VERSION ""

NS_ :

BS_:

BU_: ABS_BASE ATCM_DMSM GENERIC_GWMWakeup PBM IPMB TCU_TBS FDSM GSM TRCM GWM _delete ABS_ESC HUD IPMA CCM SASM PSCM SCCM HCM ATCM SUMA_RLM ATCM_FFSM PCU SECM VDM TBM OCS GENERIC TCCM TSTR RCM

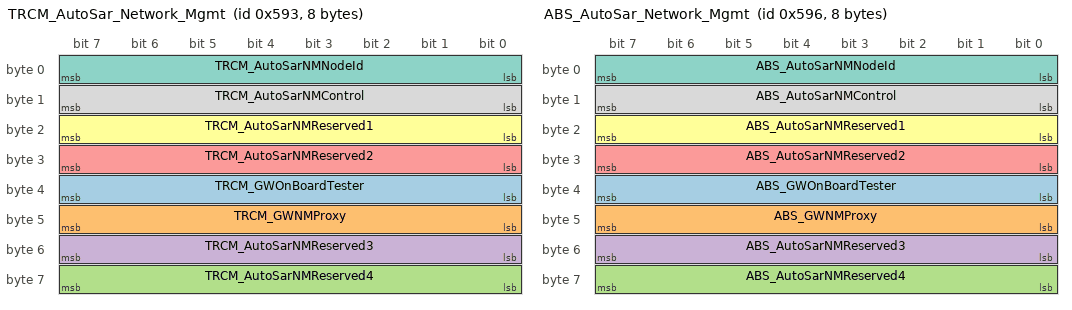
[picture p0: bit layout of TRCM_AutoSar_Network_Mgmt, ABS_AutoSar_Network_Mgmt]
BO_ 1427 TRCM_AutoSar_Network_Mgmt: 8 TRCM
 SG_ TRCM_GWOnBoardTester : 39|8@0+ (1,0) [0|255] "unitless"  GWM
 SG_ TRCM_GWNMProxy : 47|8@0+ (1,0) [0|255] "unitless"  GWM
 SG_ TRCM_AutoSarNMReserved4 : 63|8@0+ (1,0) [0|255] "unitless"  GWM
 SG_ TRCM_AutoSarNMReserved3 : 55|8@0+ (1,0) [0|255] "unitless"  GWM
 SG_ TRCM_AutoSarNMReserved2 : 31|8@0+ (1,0) [0|255] "unitless"  GWM
 SG_ TRCM_AutoSarNMReserved1 : 23|8@0+ (1,0) [0|255] "unitless"  GWM
 SG_ TRCM_AutoSarNMNodeId : 7|8@0+ (1,0) [0|255] "unitless"  GWM
 SG_ TRCM_AutoSarNMControl : 15|8@0+ (1,0) [0|255] "unitless"  GWM

BO_ 1430 ABS_AutoSar_Network_Mgmt: 8 ABS_ESC
 SG_ ABS_GWOnBoardTester : 39|8@0+ (1,0) [0|255] "unitless"  SCCM,GSM,PSCM,GWM
 SG_ ABS_GWNMProxy : 47|8@0+ (1,0) [0|255] "unitless"  SCCM,GSM,PSCM,GWM
 SG_ ABS_AutoSarNMReserved4 : 63|8@0+ (1,0) [0|255] "unitless"  SCCM,GSM,PSCM,GWM
 SG_ ABS_AutoSarNMReserved3 : 55|8@0+ (1,0) [0|255] "unitless"  SCCM,GSM,PSCM,GWM
 SG_ ABS_AutoSarNMReserved2 : 31|8@0+ (1,0) [0|255] "unitless"  SCCM,GSM,PSCM,GWM
 SG_ ABS_AutoSarNMReserved1 : 23|8@0+ (1,0) [0|255] "unitless"  SCCM,GSM,PSCM,GWM
 SG_ ABS_AutoSarNMNodeId : 7|8@0+ (1,0) [0|255] "unitless"  SCCM,GSM,PSCM,GWM
 SG_ ABS_AutoSarNMControl : 15|8@0+ (1,0) [0|255] "unitless"  SCCM,GSM,PSCM,GWM

BO_ 1082 GatewayData_HS2: 8 GWM
 SG_ EsaOn_B_Rq_UB : 33|1@0+ (1,0) [0|1] "SED"  PSCM
 SG_ EsaOn_B_Rq : 34|1@0+ (1,0) [0|1] "SED"  PSCM
 SG_ RearDiffLck_D_RqArb_UB : 35|1@0+ (1,0) [0|1] "SED"  TCCM
 SG_ RearDiffLck_D_RqArb : 25|2@0+ (1,0) [0|3] "SED"  TCCM
 SG_ AwdMde_D_RqArb_UB : 36|1@0+ (1,0) [0|1] "SED"  TCCM
 SG_ AwdMde_D_RqArb : 39|3@0+ (1,0) [0|7] "SED"  TCCM
 SG_ SelDrvMdeTxtReset_B_Rq_UB : 43|1@0+ (1,0) [0|1] "SED"  ABS_ESC,ABS_BASE
 SG_ SelDrvMdeTxtReset_B_Rq : 44|1@0+ (1,0) [0|1] "SED"  ABS_ESC,ABS_BASE
 SG_ SelDrvMdeDsply_B_Avail_UB : 50|1@0+ (1,0) [0|1] "SED"  ABS_BASE,ABS_ESC
 SG_ AirSusp_D_RqDrv_UB : 16|1@0+ (1,0) [0|1] "SED"  VDM
 SG_ DrvInputRequired_B_Rq_UB : 52|1@0+ (1,0) [0|1] "SED"  SCCM
 SG_ DrvInputRequired_B_Rq : 32|1@0+ (1,0) [0|1] "SED"  SCCM
 SG_ SelDrvMdeSwtch_D_Stat2_UB : 45|1@0+ (1,0) [0|1] "SED"  ABS_BASE,ABS_ESC
 SG_ SelDrvMdeSwtch_D_Stat2 : 47|2@0+ (1,0) [0|3] "SED"  ABS_BASE,ABS_ESC
 SG_ SelDrvMdeSwtch_D_Stat3_UB : 42|1@0+ (1,0) [0|1] "SED"  ABS_BASE,ABS_ESC
 SG_ FapLcStopHold_B_Rq : 57|1@0+ (1,0) [0|1] "SED"  ABS_BASE,ABS_ESC
 SG_ SelDrvMdeDsply_B_Avail : 51|1@0+ (1,0) [0|1] "SED"  ABS_BASE,ABS_ESC
 SG_ FapLcPrchgBrk_B_Rq : 59|1@0+ (1,0) [0|1] "SED"  ABS_BASE,ABS_ESC
 SG_ FapLcStopHold_B_Rq_UB : 56|1@0+ (1,0) [0|1] "SED"  ABS_BASE,ABS_ESC
 SG_ FapLcPrchgBrk_B_Rq_UB : 58|1@0+ (1,0) [0|1] "SED"  ABS_BASE,ABS_ESC
 SG_ LnchCtl_N_Rq_UB : 23|1@0+ (1,0) [0|1] "SED"  ABS_BASE,ABS_ESC
 SG_ LnchCtl_D_Rq_UB : 0|1@0+ (1,0) [0|1] "SED"  ABS_BASE,ABS_ESC
 SG_ LnchCtl_N_Rq : 15|8@0+ (50,0) [0|12750] "rpm"  ABS_BASE,ABS_ESC
 SG_ LnchCtl_D_Rq : 2|2@0+ (1,0) [0|3] "SED"  ABS_BASE,ABS_ESC
 SG_ AirSusp_D_RqDrv : 31|2@0+ (1,0) [0|3] "SED"  VDM
 SG_ AwdRnge_D_ActlIpc_UB : 26|1@0+ (1,0) [0|1] "SED"  ABS_BASE,ABS_ESC,TCCM
 SG_ AwdRnge_D_ActlIpc : 29|3@0+ (1,0) [0|7] "SED"  ABS_BASE,ABS_ESC,TCCM
 SG_ NtrlTowMdeEnbl_B_RqDrv_UB : 60|1@0+ (1,0) [0|1] "SED"  TCCM
 SG_ NtrlTowMdeEnbl_B_RqDrv : 48|1@0+ (1,0) [0|1] "SED"  TCCM
 SG_ DrvSlipCtlMde_B_RqMyKey_UB : 17|1@0+ (1,0) [0|1] "SED"  ABS_BASE,ABS_ESC
 SG_ DrvSlipCtlMde_B_RqMyKey : 18|1@0+ (1,0) [0|1] "SED"  ABS_BASE,ABS_ESC
 SG_ AwdDrvMde_D_Rq_UB : 49|1@0+ (1,0) [0|1] "SED"  TCCM
 SG_ AwdDrvMde_D_Rq : 63|3@0+ (1,0) [0|7] "SED"  TCCM
 SG_ MetricActv_B_Actl_UB : 53|1@0+ (1,0) [0|1] "SED"  IPMA
 SG_ MetricActv_B_Actl : 54|1@0+ (1,0) [0|1] "SED"  IPMA
 SG_ CamraFrntBttn_D_Stat2_UB : 3|1@0+ (1,0) [0|1] "SED"  IPMB
 SG_ CamraFrntBttn_D_Stat2 : 4|1@0+ (1,0) [0|1] "SED"  IPMB
 SG_ BrkLineLck_D_Rq_UB : 5|1@0+ (1,0) [0|1] "SED"  ABS_BASE,ABS_ESC
 SG_ BrkLineLck_D_Rq : 7|2@0+ (1,0) [0|3] "SED"  ABS_BASE,ABS_ESC
 SG_ SuspDrvMde_D_Rq_UB : 19|1@0+ (1,0) [0|1] "SED"  VDM
 SG_ SuspDrvMde_D_Rq : 22|3@0+ (1,0) [0|7] "SED"  VDM
 SG_ SelDrvMdePt_D_Stat_UB : 55|1@0+ (1,0) [0|1] "SED"  ABS_BASE,ABS_ESC
 SG_ SelDrvMdePt_D_Stat : 41|2@0+ (1,0) [0|3] "SED"  ABS_BASE,ABS_ESC

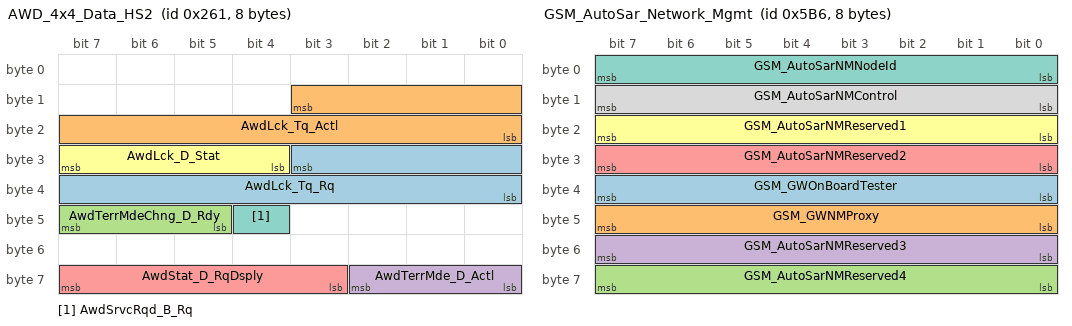
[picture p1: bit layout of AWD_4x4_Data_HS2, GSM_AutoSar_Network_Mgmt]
BO_ 609 AWD_4x4_Data_HS2: 8 GWM
 SG_ AwdLck_Tq_Rq : 27|12@0+ (1,0) [0|4093] "Nm"  GENERIC
 SG_ AwdLck_Tq_Actl : 11|12@0+ (1,0) [0|4093] "Nm"  ABS_BASE,ABS_ESC
 SG_ AwdTerrMdeChng_D_Rdy : 47|3@0+ (1,0) [0|7] "SED"  ATCM
 SG_ AwdTerrMde_D_Actl : 58|3@0+ (1,0) [0|7] "SED"  ATCM
 SG_ AwdStat_D_RqDsply : 63|5@0+ (1,0) [0|31] "SED"  ABS_BASE,ABS_ESC
 SG_ AwdLck_D_Stat : 31|4@0+ (1,0) [0|15] "SED"  ABS_BASE,ABS_ESC
 SG_ AwdSrvcRqd_B_Rq : 44|1@0+ (1,0) [0|1] "SED"  ABS_BASE,ABS_ESC,RCM

BO_ 1462 GSM_AutoSar_Network_Mgmt: 8 GSM
 SG_ GSM_GWOnBoardTester : 39|8@0+ (1,0) [0|255] "unitless"  GWM
 SG_ GSM_GWNMProxy : 47|8@0+ (1,0) [0|255] "unitless"  GWM
 SG_ GSM_AutoSarNMReserved4 : 63|8@0+ (1,0) [0|255] "unitless"  GWM
 SG_ GSM_AutoSarNMReserved3 : 55|8@0+ (1,0) [0|255] "unitless"  GWM
 SG_ GSM_AutoSarNMReserved2 : 31|8@0+ (1,0) [0|255] "unitless"  GWM
 SG_ GSM_AutoSarNMReserved1 : 23|8@0+ (1,0) [0|255] "unitless"  GWM
 SG_ GSM_AutoSarNMNodeId : 7|8@0+ (1,0) [0|255] "unitless"  GWM
 SG_ GSM_AutoSarNMControl : 15|8@0+ (1,0) [0|255] "unitless"  GWM

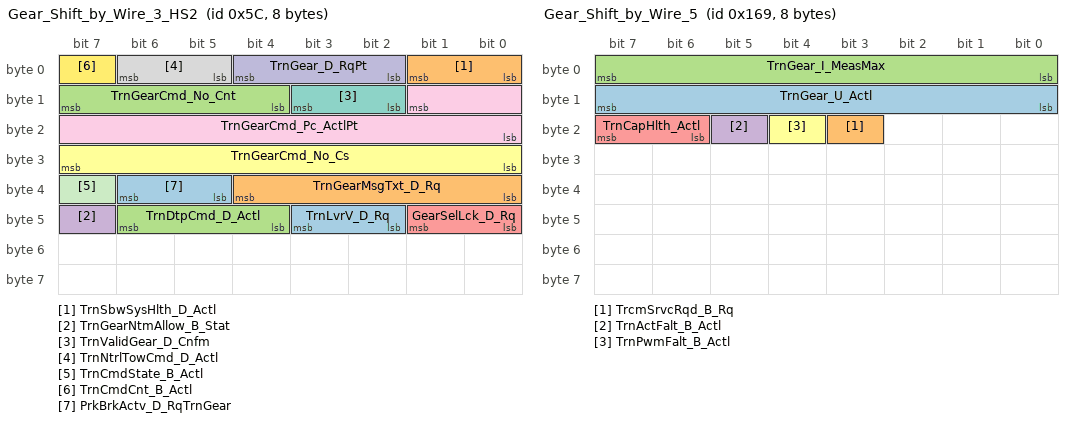
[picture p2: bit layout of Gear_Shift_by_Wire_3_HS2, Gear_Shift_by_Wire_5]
BO_ 92 Gear_Shift_by_Wire_3_HS2: 8 GWM
 SG_ TrnLvrV_D_Rq : 43|2@0+ (1,0) [0|3] "SED"  TRCM
 SG_ TrnSbwSysHlth_D_Actl : 1|2@0+ (1,0) [0|3] "SED"  GSM,TRCM
 SG_ TrnDtpCmd_D_Actl : 46|3@0+ (1,0) [0|7] "SED"  GSM,TRCM
 SG_ TrnGearNtmAllow_B_Stat : 47|1@0+ (1,0) [0|1] "SED"  GENERIC
 SG_ GearSelLck_D_Rq : 41|2@0+ (1,0) [0|3] "SED"  GSM,TRCM
 SG_ TrnGearCmd_No_Cs : 31|8@0+ (1,0) [0|255] "Unitless"  TRCM,GSM
 SG_ TrnValidGear_D_Cnfm : 11|2@0+ (1,0) [0|3] "SED"  TRCM,GSM
 SG_ TrnNtrlTowCmd_D_Actl : 6|2@0+ (1,0) [0|3] "SED"  ABS_BASE,ABS_ESC,TRCM,GSM
 SG_ TrnGearCmd_Pc_ActlPt : 9|10@0+ (0.1,0) [0|102.2] "percent duty cycle"  TRCM,GSM
 SG_ TrnGear_D_RqPt : 4|3@0+ (1,0) [0|7] "SED"  TRCM,GSM
 SG_ TrnCmdState_B_Actl : 39|1@0+ (1,0) [0|1] "SED"  TRCM,GSM
 SG_ TrnCmdCnt_B_Actl : 7|1@0+ (1,0) [0|1] "unitless"  TRCM,GSM
 SG_ PrkBrkActv_D_RqTrnGear : 38|2@0+ (1,0) [0|3] "SED"  ABS_BASE,GSM,TRCM,ABS_ESC
 SG_ TrnGearMsgTxt_D_Rq : 36|5@0+ (1,0) [0|31] "SED"  GENERIC
 SG_ TrnGearCmd_No_Cnt : 15|4@0+ (1,0) [0|15] "Unitless"  GSM,TRCM

BO_ 361 Gear_Shift_by_Wire_5: 8 TRCM
 SG_ TrnGear_U_Actl : 15|8@0+ (0.1,0) [0|25.5] "volt"  GWM
 SG_ TrcmSrvcRqd_B_Rq : 19|1@0+ (1,0) [0|1] "SED"  GWM
 SG_ TrnGear_I_MeasMax : 7|8@0+ (0.1,0) [0|25.4] "Amps"  GWM
 SG_ TrnActFalt_B_Actl : 21|1@0+ (1,0) [0|1] "SED"  GWM
 SG_ TrnCapHlth_Actl : 23|2@0+ (1,0) [0|3] "SED"  GWM
 SG_ TrnPwmFalt_B_Actl : 20|1@0+ (1,0) [0|1] "SED"  GWM

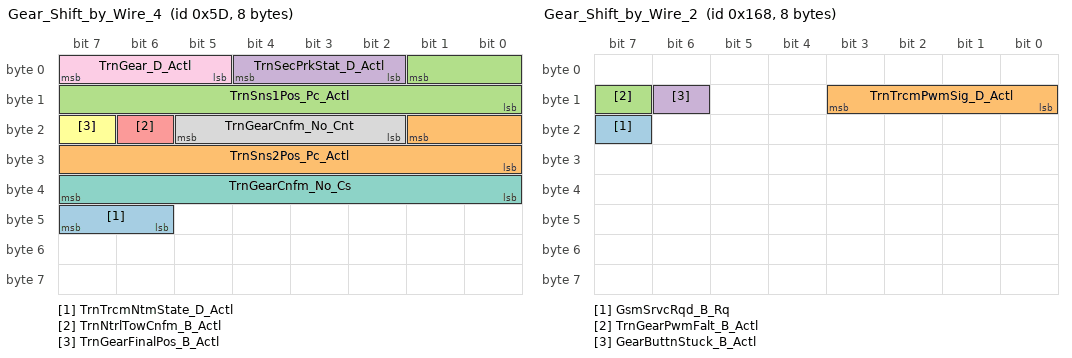
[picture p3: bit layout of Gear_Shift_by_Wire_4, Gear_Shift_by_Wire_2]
BO_ 93 Gear_Shift_by_Wire_4: 8 TRCM
 SG_ TrnTrcmNtmState_D_Actl : 47|2@0+ (1,0) [0|3] "SED"  GSM,GWM
 SG_ TrnSns2Pos_Pc_Actl : 17|10@0+ (0.1,0) [0|102.2] "percent duty cycle"  GSM,GWM
 SG_ TrnSns1Pos_Pc_Actl : 1|10@0+ (0.1,0) [0|102.2] "percent duty cycle"  GSM,GWM
 SG_ TrnSecPrkStat_D_Actl : 4|3@0+ (1,0) [0|7] "SED"  GSM,GWM
 SG_ TrnNtrlTowCnfm_B_Actl : 22|1@0+ (1,0) [0|1] "SED"  GSM,GWM
 SG_ TrnGearFinalPos_B_Actl : 23|1@0+ (1,0) [0|1] "SED"  GSM,GWM
 SG_ TrnGearCnfm_No_Cs : 39|8@0+ (1,0) [0|255] "Unitless"  GSM,GWM
 SG_ TrnGearCnfm_No_Cnt : 21|4@0+ (1,0) [0|15] "Unitless"  GSM,GWM
 SG_ TrnGear_D_Actl : 7|3@0+ (1,0) [0|7] "SED"  GSM,GWM

BO_ 360 Gear_Shift_by_Wire_2: 8 GSM
 SG_ GsmSrvcRqd_B_Rq : 23|1@0+ (1,0) [0|1] "SED"  GWM
 SG_ TrnTrcmPwmSig_D_Actl : 11|4@0+ (1,0) [0|15] "SED"  GWM
 SG_ TrnGearPwmFalt_B_Actl : 15|1@0+ (1,0) [0|1] "SED"  GWM
 SG_ GearButtnStuck_B_Actl : 14|1@0+ (1,0) [0|1] "SED"  GWM

BO_ 90 Gear_Shift_by_Wire: 8 GSM
 SG_ TrnGsmNtmState_D_Actl : 55|2@0+ (1,0) [0|3] "SED"  ABS_BASE,ABS_ESC,GWM,TRCM
 SG_ DrQltyDrv_D_StatGsm : 42|3@0+ (1,0) [0|7] "SED"  ABS_BASE,ABS_ESC,IPMA,TRCM,GWM,CCM
 SG_ TrnBtsiOvrrd_B_Stat : 43|1@0+ (1,0) [0|1] "SED"  TRCM,GWM
 SG_ GsmGearMsgTxt_D_Rq : 63|2@0+ (1,0) [0|3] "SED"  GWM
 SG_ TrnRng_D_RqGsm : 51|4@0+ (1,0) [0|15] "SED"  GWM
 SG_ PrkBrkActv_D_RqGsmGear : 53|2@0+ (1,0) [0|3] "SED"  ABS_ESC,ABS_BASE,GWM
 SG_ TrnValidGearRq_D_Stat : 25|2@0+ (1,0) [0|3] "SED"  TRCM,GWM
 SG_ TrnGearRqCnt_B_Actl : 26|1@0+ (1,0) [0|1] "unitless"  TRCM,GWM
 SG_ TrnGearButtn_U_Actl : 23|8@0+ (0.05,0) [0|12.7] "VOLT"  TRCM,GWM
 SG_ TrnGearButtn_B_ActlR2 : 8|1@0+ (1,0) [0|1] "SED"  TRCM,GWM
 SG_ TrnGearButtn_B_ActlR1 : 9|1@0+ (1,0) [0|1] "SED"  TRCM,GWM
 SG_ TrnGearButtn_B_ActlR0 : 10|1@0+ (1,0) [0|1] "SED"  TRCM,GWM
 SG_ TrnGearButtn_B_ActlP2 : 11|1@0+ (1,0) [0|1] "SED"  TRCM,GWM
 SG_ TrnGearButtn_B_ActlP1 : 12|1@0+ (1,0) [0|1] "SED"  TRCM,GWM
 SG_ TrnGearButtn_B_ActlP0 : 13|1@0+ (1,0) [0|1] "SED"  TRCM,GWM
 SG_ TrnGearButtn_B_ActlN2 : 14|1@0+ (1,0) [0|1] "SED"  TRCM,GWM
 SG_ TrnGearButtn_B_ActlN1 : 15|1@0+ (1,0) [0|1] "SED"  TRCM,GWM
 SG_ TrnGearButtn_B_ActlN0 : 0|1@0+ (1,0) [0|1] "SED"  TRCM,GWM
 SG_ TrnGearButtn_B_ActlM2 : 1|1@0+ (1,0) [0|1] "SED"  TRCM,GWM
 SG_ TrnGearButtn_B_ActlM1 : 2|1@0+ (1,0) [0|1] "SED"  TRCM,GWM
 SG_ TrnGearButtn_B_ActlM0 : 3|1@0+ (1,0) [0|1] "SED"  TRCM,GWM
 SG_ TrnGearButtn_B_ActlD2 : 4|1@0+ (1,0) [0|1] "SED"  TRCM,GWM
 SG_ TrnGearButtn_B_ActlD1 : 5|1@0+ (1,0) [0|1] "SED"  TRCM,GWM
 SG_ TrnGearButtn_B_ActlD0 : 6|1@0+ (1,0) [0|1] "SED"  TRCM,GWM
 SG_ TrnGear_No_Cs : 39|8@0+ (1,0) [0|255] "Unitless"  TRCM,GWM
 SG_ TrnGear_No_Cnt : 47|4@0+ (1,0) [0|15] "Unitless"  TRCM,GWM
 SG_ TrnGear_D_RqDrv : 31|5@0+ (1,0) [0|31] "SED"  TRCM,GWM
 SG_ BrkSwtchPos_B_ActlGsm : 7|1@0+ (1,0) [0|1] "SED"  TRCM,GWM

BO_ 1809 TesterPhysicalReqTRCM: 8 TSTR
 SG_ TesterPhysicalReqTRCM : 7|64@0+ (1,0) [0|1.84467E+019] "unitless"  TRCM

BO_ 1842 TesterPhysicalReqGSM: 8 TSTR
 SG_ TesterPhysicalReqGSM : 7|64@0+ (1,0) [0|1.84467E+019] "unitless"  GSM

BO_ 1817 TesterPhysicalResTRCM: 8 TRCM
 SG_ TesterPhysicalResTRCM : 7|64@0+ (1,0) [0|1.84467E+019] "unitless"  TSTR

BO_ 1850 TesterPhysicalResGSM: 8 GSM
 SG_ TesterPhysicalResGSM : 7|64@0+ (1,0) [0|1.84467E+019] "unitless"  TSTR

BO_ 1889 TesterPhysicalReqTCCM: 8 TSTR
 SG_ TesterPhysicalReqTCCM : 7|64@0+ (1,0) [0|1.84467E+019] "unitless"  TCCM

BO_ 1897 TesterPhysicalResTCCM: 8 TCCM
 SG_ TesterPhysicalResTCCM : 7|64@0+ (1,0) [0|1.84467E+019] "unitless"  TSTR

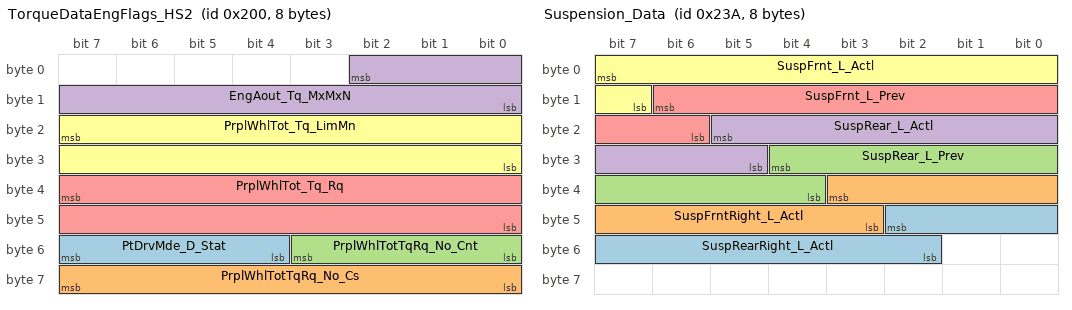
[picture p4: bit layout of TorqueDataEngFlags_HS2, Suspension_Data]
BO_ 512 TorqueDataEngFlags_HS2: 8 GWM
 SG_ PtDrvMde_D_Stat : 55|4@0+ (1,0) [0|15] "SED"  ABS_BASE,ABS_ESC,SASM,CCM,IPMA
 SG_ PrplWhlTotTqRq_No_Cs : 63|8@0+ (1,0) [0|255] "Unitless"  ABS_BASE,ABS_ESC
 SG_ PrplWhlTotTqRq_No_Cnt : 51|4@0+ (1,0) [0|15] "Unitless"  ABS_BASE,ABS_ESC
 SG_ EngAout_Tq_MxMxN : 2|11@0+ (1,-500) [-500|1547] "Nm"  GENERIC
 SG_ PrplWhlTot_Tq_Rq : 39|16@0+ (4,-131072) [-131072|131068] "Nm"  ABS_BASE,TCCM,ABS_ESC,VDM
 SG_ PrplWhlTot_Tq_LimMn : 23|16@0+ (4,-131072) [-131072|131068] "Nm"  ABS_BASE,ABS_ESC

BO_ 936 ParkAid_Data_HS2: 8 GWM
 SG_ ApaChime_D_Rq : 39|3@0+ (1,0) [0|7] "SED"  GENERIC
 SG_ ApaSys_D_Stat : 61|3@0+ (1,0) [0|7] "SED"  GENERIC
 SG_ ApaSteWhl_D_RqDrv : 63|2@0+ (1,0) [0|3] "SED"  GENERIC
 SG_ ApaSteScanMde_D_Stat : 49|2@0+ (1,0) [0|3] "SED"  GENERIC
 SG_ ApaSelSapp_D_Stat : 51|2@0+ (1,0) [0|3] "SED"  GENERIC
 SG_ ApaSelPpa_D_Stat : 53|2@0+ (1,0) [0|3] "SED"  GENERIC
 SG_ ApaSelPoa_D_Stat : 55|2@0+ (1,0) [0|3] "SED"  GENERIC
 SG_ ApaScan_D_Stat : 41|2@0+ (1,0) [0|3] "SED"  GENERIC
 SG_ ApaLongCtl_D_RqDrv : 44|3@0+ (1,0) [0|7] "SED"  GENERIC
 SG_ ApaGearShif_D_RqDrv : 47|3@0+ (1,0) [0|7] "SED"  GENERIC
 SG_ ApaActvSide2_D_Stat : 33|2@0+ (1,0) [0|3] "SED"  GENERIC
 SG_ ApaAcsy_D_RqDrv : 36|3@0+ (1,0) [0|7] "SED"  GENERIC
 SG_ ApaTrgtDist_D_Stat : 11|4@0+ (1,0) [0|15] "SED"  GENERIC
 SG_ ApaMsgTxt_D_Rq : 15|4@0+ (1,0) [0|15] "SED"  GENERIC
 SG_ EPASExtAngleStatReq : 23|1@0+ (1,0) [0|1] "SED"  ABS_BASE,ABS_ESC,PSCM
 SG_ SAPPStatusCoding : 7|8@0+ (1,0) [0|255] "unitless"  IPMB,VDM,PSCM
 SG_ ExtSteeringAngleReq2 : 22|15@0+ (0.1,-1000) [-1000|2276.5] "Degrees"  PSCM

BO_ 570 Suspension_Data: 8 VDM
 SG_ SuspRearRight_L_Actl : 42|9@0+ (0.782779,-200) [-200|199.21729] "millimeter"  HCM,ABS_BASE,PSCM,ABS_ESC
 SG_ SuspFrntRight_L_Actl : 35|9@0+ (0.782779,-200) [-200|199.21729] "millimeter"  HCM,ABS_BASE,PSCM,ABS_ESC
 SG_ SuspRear_L_Prev : 28|9@0+ (0.782779,-200) [-200|199.21729] "millimeter"  ABS_BASE,ABS_ESC,HCM
 SG_ SuspRear_L_Actl : 21|9@0+ (0.782779,-200) [-200|199.21729] "millimeter"  ABS_BASE,PSCM,ABS_ESC,HCM
 SG_ SuspFrnt_L_Prev : 14|9@0+ (0.782779,-200) [-200|199.21729] "millimeter"  ABS_BASE,ABS_ESC,HCM
 SG_ SuspFrnt_L_Actl : 7|9@0+ (0.782779,-200) [-200|199.21729] "millimeter"  ABS_BASE,PSCM,ABS_ESC,HCM

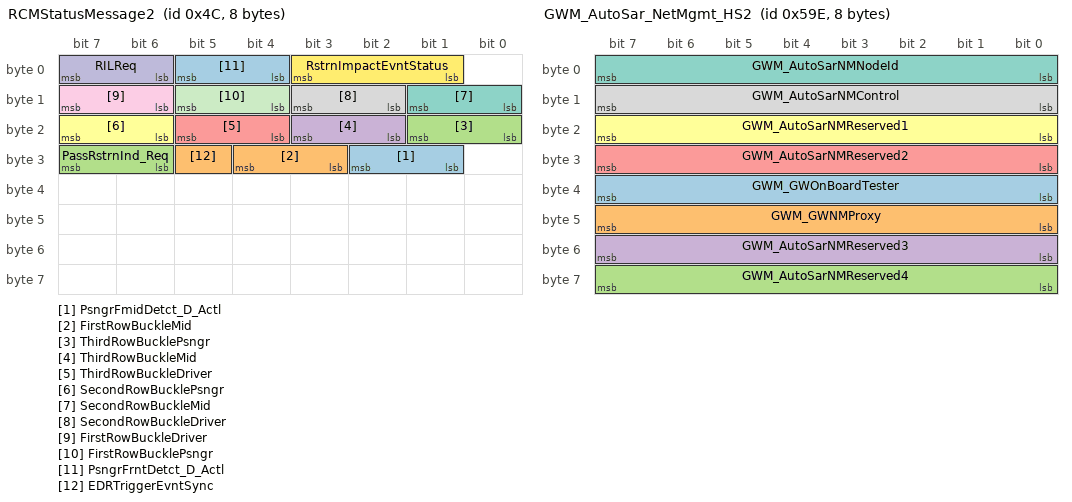
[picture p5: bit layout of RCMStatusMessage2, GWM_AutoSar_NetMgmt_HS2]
BO_ 76 RCMStatusMessage2: 8 RCM
 SG_ PsngrFmidDetct_D_Actl : 26|2@0+ (1,0) [0|3] "SED"  GWM
 SG_ FirstRowBuckleMid : 28|2@0+ (1,0) [0|3] "SED"  GWM
 SG_ ThirdRowBucklePsngr : 17|2@0+ (1,0) [0|3] "SED"  GWM
 SG_ ThirdRowBuckleMid : 19|2@0+ (1,0) [0|3] "SED"  GWM
 SG_ ThirdRowBuckleDriver : 21|2@0+ (1,0) [0|3] "SED"  GWM
 SG_ SecondRowBucklePsngr : 23|2@0+ (1,0) [0|3] "SED"  GWM
 SG_ SecondRowBuckleMid : 9|2@0+ (1,0) [0|3] "SED"  GWM
 SG_ SecondRowBuckleDriver : 11|2@0+ (1,0) [0|3] "SED"  GWM
 SG_ FirstRowBuckleDriver : 15|2@0+ (1,0) [0|3] "SED"  ABS_BASE,PBM,IPMA,GSM,ABS_ESC,CCM,GWM
 SG_ RILReq : 7|2@0+ (1,0) [0|3] "SED"  GWM
 SG_ FirstRowBucklePsngr : 13|2@0+ (1,0) [0|3] "SED"  OCS,GWM,CCM
 SG_ RstrnImpactEvntStatus : 3|3@0+ (1,0) [0|7] "SED"  ABS_BASE,SCCM,ABS_ESC,SASM,OCS,CCM,GWM,IPMA
 SG_ PsngrFrntDetct_D_Actl : 5|2@0+ (1,0) [0|3] "SED"  GWM
 SG_ EDRTriggerEvntSync : 29|1@0+ (1,0) [0|1] "SED"  IPMA,GWM,CCM
 SG_ PassRstrnInd_Req : 31|2@0+ (1,0) [0|3] "SED"  GWM

BO_ 120 EngineData_9_HS2: 8 GWM
 SG_ TrlrAidSwtch_D_RqDrv : 22|2@0+ (1,0) [0|3] "SED"  PSCM
 SG_ TrlrAidCtl_U_RqDrv : 27|12@0+ (0.00125,0) [0|5.11625] "volt"  PSCM
 SG_ TrlrAidSwtch_D_RqDrv_UB : 20|1@0+ (1,0) [0|1] "SED"  PSCM
 SG_ TrlrAidCtl_U_RqDrv_UB : 31|1@0+ (1,0) [0|1] "SED"  PSCM
 SG_ BpedDrvMsgTxt_B_Dsply_UB : 17|1@0+ (1,0) [0|1] "SED"  RCM
 SG_ BpedDrvMsgTxt_B_Dsply : 18|1@0+ (1,0) [0|1] "SED"  RCM
 SG_ PassRstrnInd_Stat_UB : 1|1@0+ (1,0) [0|1] "SED"  RCM
 SG_ PassRstrnInd_Stat : 30|3@0+ (1,0) [0|7] "SED"  RCM
 SG_ HtrnWarnLamp_B_Dsply_UB : 4|1@0+ (1,0) [0|1] "SED"  GENERIC
 SG_ HtrnWarnLamp_B_Dsply : 5|1@0+ (1,0) [0|1] "SED"  RCM
 SG_ ECMMILRequest_UB : 8|1@0+ (1,0) [0|1] "SED"  RCM
 SG_ ECMMILRequest : 10|2@0+ (1,0) [0|3] "SED"  RCM
 SG_ TrnIpcDsplyMde_D_Stat : 12|2@0+ (1,0) [0|3] "SED"  GSM,TRCM
 SG_ TrnIpcDsplyMde_D_Actl : 15|3@0+ (1,0) [0|7] "SED"  GSM,TRCM
 SG_ EngSrvcRqd_B_Rq_UB : 2|1@0+ (1,0) [0|1] "SED"  GENERIC
 SG_ EngSrvcRqd_B_Rq : 3|1@0+ (1,0) [0|1] "SED"  RCM
 SG_ HtrnSrvcRqd_B_Dsply : 7|1@0+ (1,0) [0|1] "SED"  RCM
 SG_ HtrnSrvcRqd_B_Dsply_UB : 6|1@0+ (1,0) [0|1] "SED"  GENERIC
 SG_ TrnIpcDsplyMde_D_Stat_UB : 23|1@0+ (1,0) [0|1] "SED"  GSM,TRCM
 SG_ TrnIpcDsplyMde_D_Actl_UB : 0|1@0+ (1,0) [0|1] "SED"  GSM,TRCM

BO_ 1665 RCM_Rapid_Data_Response_2: 8 RCM
 SG_ UUDTRCMResponse2 : 7|64@0+ (1,0) [0|1.844674407371E+019] "unitless"  TSTR

BO_ 2041 TesterPhysicalResPCU: 8 RCM
 SG_ TesterPhysicalResPCU : 7|64@0+ (1,0) [0|1.84467E+019] "unitless"  TSTR

BO_ 1438 GWM_AutoSar_NetMgmt_HS2: 8 GWM
 SG_ GWM_GWOnBoardTester : 39|8@0+ (1,0) [0|255] "unitless"  SCCM,GSM,PSCM,ABS_BASE,SUMA_RLM,ATCM_DMSM,ATCM_FFSM,ABS_ESC
 SG_ GWM_GWNMProxy : 47|8@0+ (1,0) [0|255] "unitless"  SCCM,GSM,PSCM,ABS_BASE,SUMA_RLM,ATCM_DMSM,ATCM_FFSM,ABS_ESC
 SG_ GWM_AutoSarNMReserved4 : 63|8@0+ (1,0) [0|255] "unitless"  SCCM,GSM,PSCM,ABS_BASE,SUMA_RLM,ATCM_DMSM,ATCM_FFSM,ABS_ESC
 SG_ GWM_AutoSarNMReserved3 : 55|8@0+ (1,0) [0|255] "unitless"  SCCM,GSM,PSCM,ABS_BASE,SUMA_RLM,ATCM_DMSM,ATCM_FFSM,ABS_ESC
 SG_ GWM_AutoSarNMReserved2 : 31|8@0+ (1,0) [0|255] "unitless"  SCCM,GSM,PSCM,ABS_BASE,SUMA_RLM,ATCM_DMSM,ATCM_FFSM,ABS_ESC
 SG_ GWM_AutoSarNMReserved1 : 23|8@0+ (1,0) [0|255] "unitless"  SCCM,GSM,PSCM,ABS_BASE,SUMA_RLM,ATCM_DMSM,ATCM_FFSM,ABS_ESC
 SG_ GWM_AutoSarNMNodeId : 7|8@0+ (1,0) [0|255] "unitless"  GSM,PSCM,ABS_BASE,SUMA_RLM,ATCM_DMSM,ATCM_FFSM,ABS_ESC,SCCM
 SG_ GWM_AutoSarNMControl : 15|8@0+ (1,0) [0|255] "unitless"  GSM,PSCM,ABS_BASE,SUMA_RLM,ATCM_DMSM,ATCM_FFSM,ABS_ESC,SCCM

BO_ 1034 GGCC_Config_Mgmt_ID_1_HS2: 8 GWM
 SG_ VehicleGGCCData : 7|64@0+ (1,0) [0|1.84467E+019] "mixed"  SUMA_RLM,ABS_BASE,PBM,TCU_TBS,FDSM,SASM,IPMA,HCM,TCCM,ABS_ESC,OCS,RCM,CCM,GSM,TRCM,TBM,ATCM,HUD,PSCM,SCCM,VDM

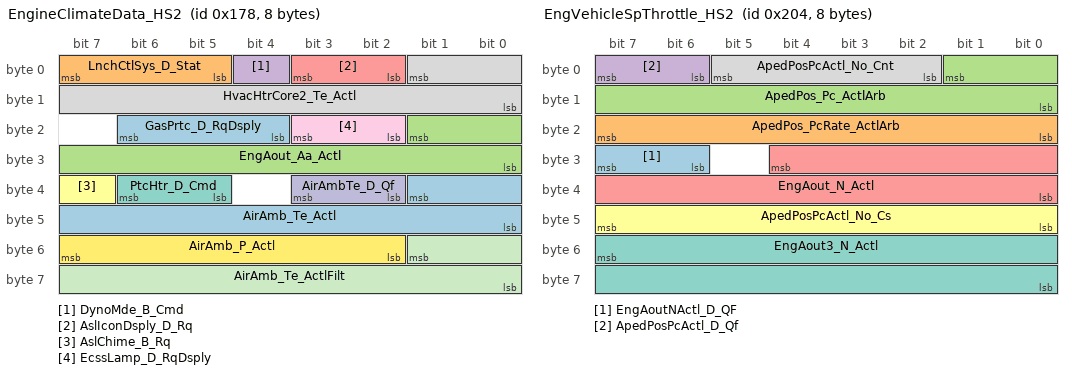
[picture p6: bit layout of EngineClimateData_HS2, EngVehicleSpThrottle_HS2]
BO_ 376 EngineClimateData_HS2: 8 GWM
 SG_ GasPrtc_D_RqDsply : 22|3@0+ (1,0) [0|7] "SED"  GENERIC
 SG_ LnchCtlSys_D_Stat : 7|3@0+ (1,0) [0|7] "SED"  ABS_BASE,ABS_ESC
 SG_ EngAout_Aa_Actl : 17|10@0+ (0.05,-25.6) [-25.6|25.55] "rpm/ms"  ABS_BASE,ABS_ESC
 SG_ DynoMde_B_Cmd : 4|1@0+ (1,0) [0|1] "SED"  ABS_BASE,ABS_ESC
 SG_ AslIconDsply_D_Rq : 3|2@0+ (1,0) [0|3] "SED"  IPMA
 SG_ AslChime_B_Rq : 39|1@0+ (1,0) [0|1] "SED"  GENERIC
 SG_ PtcHtr_D_Cmd : 38|2@0+ (1,0) [0|3] "SED"  GENERIC
 SG_ HvacHtrCore2_Te_Actl : 1|10@0+ (0.25,-50) [-50|205.5] "degC"  GENERIC
 SG_ EcssLamp_D_RqDsply : 19|2@0+ (1,0) [0|3] "SED"  GENERIC
 SG_ AirAmbTe_D_Qf : 35|2@0+ (1,0) [0|3] "SED"  SUMA_RLM,ABS_BASE,RCM,PBM,IPMA,TCCM,SCCM,FDSM,ABS_ESC,VDM
 SG_ AirAmb_Te_ActlFilt : 49|10@0+ (0.25,-128) [-128|127.75] "deg C"  RCM,FDSM,IPMA,VDM
 SG_ AirAmb_P_Actl : 55|6@0+ (10,500) [500|1110] "mbar"  SUMA_RLM,ABS_BASE,ABS_ESC,VDM
 SG_ AirAmb_Te_Actl : 33|10@0+ (0.25,-128) [-128|127.75] "degC"  SUMA_RLM,ABS_BASE,PBM,HCM,TCCM,SCCM,ABS_ESC,VDM

BO_ 516 EngVehicleSpThrottle_HS2: 8 GWM
 SG_ EngAoutNActl_D_QF : 31|2@0+ (1,0) [0|3] "SED"  GENERIC
 SG_ ApedPos_PcRate_ActlArb : 23|8@0+ (0.04,-5) [-5|5.12] "%/ms"  IPMA
 SG_ ApedPos_Pc_ActlArb : 1|10@0+ (0.1,0) [0|102.3] "%"  ABS_BASE,PBM,HCM,PSCM,TCCM,FDSM,ABS_ESC,VDM,CCM,IPMA,OCS,RCM
 SG_ ApedPosPcActl_D_Qf : 7|2@0+ (1,0) [0|3] "SED"  ABS_BASE,PBM,IPMA,HCM,FDSM,ABS_ESC,PSCM,VDM,OCS,CCM,RCM
 SG_ EngAout_N_Actl : 28|13@0+ (2,0) [0|16382] "rpm"  SUMA_RLM,ABS_BASE,PBM,HUD,HCM,PSCM,TCCM,GSM,TRCM,ABS_ESC,VDM,RCM
 SG_ ApedPosPcActl_No_Cs : 47|8@0+ (1,0) [0|255] "Unitless"  ABS_BASE,ABS_ESC
 SG_ EngAout3_N_Actl : 55|16@0+ (0.25,0) [0|16383.5] "RPM"  GENERIC
 SG_ ApedPosPcActl_No_Cnt : 5|4@0+ (1,0) [0|15] "Unitless"  ABS_BASE,ABS_ESC

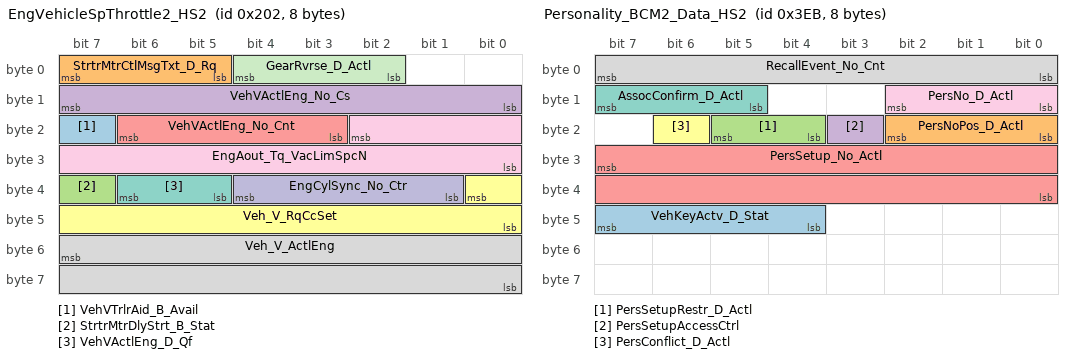
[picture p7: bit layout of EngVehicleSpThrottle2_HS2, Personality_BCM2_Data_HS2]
BO_ 514 EngVehicleSpThrottle2_HS2: 8 GWM
 SG_ VehVTrlrAid_B_Avail : 23|1@0+ (1,0) [0|1] "SED"  PSCM
 SG_ StrtrMtrCtlMsgTxt_D_Rq : 7|3@0+ (1,0) [0|7] "SED"  GENERIC
 SG_ StrtrMtrDlyStrt_B_Stat : 39|1@0+ (1,0) [0|1] "SED"  GENERIC
 SG_ VehVActlEng_No_Cs : 15|8@0+ (1,0) [0|255] "Unitless"  ABS_BASE,SASM,ABS_ESC,PSCM
 SG_ VehVActlEng_No_Cnt : 22|4@0+ (1,0) [0|15] "Unitless"  ABS_BASE,SASM,ABS_ESC,PSCM
 SG_ Veh_V_RqCcSet : 32|9@0+ (0.5,0) [0|255.5] "kph"  IPMA,CCM,PSCM
 SG_ VehVActlEng_D_Qf : 38|2@0+ (1,0) [0|3] "SED"  ABS_BASE,SCCM,HCM,TCU_TBS,SASM,IPMB,GSM,RCM,TRCM,ABS_ESC,VDM,OCS,CCM,IPMA,PSCM,HUD
 SG_ Veh_V_ActlEng : 55|16@0+ (0.01,0) [0|655.35] "kph"  SUMA_RLM,ABS_BASE,IPMB,TBM,HCM,SASM,TCU_TBS,GSM,RCM,TRCM,ABS_ESC,VDM,OCS,CCM,SCCM,PSCM,IPMA,HUD
 SG_ EngAout_Tq_VacLimSpcN : 18|11@0+ (1,-500) [-500|1547] "Nm"  GENERIC
 SG_ EngCylSync_No_Ctr : 36|4@0+ (1,0) [0|15] "unitless"  GENERIC
 SG_ GearRvrse_D_Actl : 4|3@0+ (1,0) [0|7] "SED"  ABS_BASE,IPMB,HCM,RCM,ABS_ESC,CCM,IPMA,OCS,SCCM,VDM,PSCM

BO_ 1003 Personality_BCM2_Data_HS2: 8 GWM
 SG_ VehKeyActv_D_Stat : 47|4@0+ (1,0) [0|15] "SED"  HCM,GENERIC
 SG_ PersNoPos_D_Actl : 18|3@0+ (1,0) [0|7] "SED"  HCM,VDM
 SG_ PersSetupRestr_D_Actl : 21|2@0+ (1,0) [0|3] "SED"  HCM,VDM,CCM
 SG_ PersSetupAccessCtrl : 19|1@0+ (1,0) [0|1] "SED"  HCM,VDM,CCM
 SG_ PersSetup_No_Actl : 31|16@0+ (1,0) [0|65535] "Number"  HCM,VDM,CCM
 SG_ PersConflict_D_Actl : 22|1@0+ (1,0) [0|1] "SED"  HCM,GENERIC
 SG_ AssocConfirm_D_Actl : 15|3@0+ (1,0) [0|7] "SED"  HCM,GENERIC
 SG_ RecallEvent_No_Cnt : 7|8@0+ (1,0) [0|255] "Counts"  HCM,IPMA,SASM,VDM,CCM
 SG_ PersNo_D_Actl : 10|3@0+ (1,0) [0|7] "SED"  HCM,SASM,IPMA,VDM,CCM

BO_TX_BU_ 1430 : ABS_BASE,ABS_ESC;
BO_TX_BU_ 90 : GENERIC_GWMWakeup,GSM;
BO_TX_BU_ 76 : GENERIC_GWMWakeup,RCM;
CM_ SG_ 1430 ABS_GWOnBoardTester "Signal not transmitted on gas, diesel and HEV.  Only supported on PHEV.";
CM_ SG_ 1430 ABS_GWNMProxy "Signal not transmitted on gas, diesel and HEV.  Only supported on PHEV.";
CM_ SG_ 1430 ABS_AutoSarNMReserved4 "Signal not transmitted on gas, diesel and HEV.  Only supported on PHEV.";
CM_ SG_ 1430 ABS_AutoSarNMReserved3 "Signal not transmitted on gas, diesel and HEV.  Only supported on PHEV.";
CM_ SG_ 1430 ABS_AutoSarNMReserved2 "Signal not transmitted on gas, diesel and HEV.  Only supported on PHEV.";
CM_ SG_ 1430 ABS_AutoSarNMReserved1 "Signal not transmitted on gas, diesel and HEV.  Only supported on PHEV.";
CM_ SG_ 1430 ABS_AutoSarNMNodeId "Signal not transmitted on gas, diesel and HEV.  Only supported on PHEV.";
CM_ SG_ 1430 ABS_AutoSarNMControl "Signal not transmitted on gas, diesel and HEV.  Only supported on PHEV.";
CM_ SG_ 1082 MetricActv_B_Actl "0 =Inactive(English), 1=Active(Metric)";
CM_ BO_ 609 "Used on Applications with 4x4 supplied by Motorola.";
CM_ SG_ 609 AwdLck_Tq_Rq "Signal not transmitted on programs that do not have AWD.";
CM_ SG_ 609 AwdStat_D_RqDsply "Signal not transmitted on programs that do not have AWD.";
CM_ SG_ 609 AwdSrvcRqd_B_Rq "Signal not transmitted on programs that do not have AWD.";
CM_ SG_ 1462 GSM_GWOnBoardTester "Signal not transmitted on gas, diesel and HEV.  Only supported on PHEV.";
CM_ SG_ 1462 GSM_GWNMProxy "Signal not transmitted on gas, diesel and HEV.  Only supported on PHEV.";
CM_ SG_ 1462 GSM_AutoSarNMReserved4 "Signal not transmitted on gas, diesel and HEV.  Only supported on PHEV.";
CM_ SG_ 1462 GSM_AutoSarNMReserved3 "Signal not transmitted on gas, diesel and HEV.  Only supported on PHEV.";
CM_ SG_ 1462 GSM_AutoSarNMReserved2 "Signal not transmitted on gas, diesel and HEV.  Only supported on PHEV.";
CM_ SG_ 1462 GSM_AutoSarNMReserved1 "Signal not transmitted on gas, diesel and HEV.  Only supported on PHEV.";
CM_ SG_ 1462 GSM_AutoSarNMNodeId "Signal not transmitted on gas, diesel and HEV.  Only supported on PHEV.";
CM_ SG_ 1462 GSM_AutoSarNMControl "Signal not transmitted on gas, diesel and HEV.  Only supported on PHEV.";
CM_ SG_ 92 TrnSbwSysHlth_D_Actl "Signal not transmitted on vehicles that do not have shift by wire.";
CM_ SG_ 92 TrnDtpCmd_D_Actl "Signal not transmitted on vehicles that do not have shift by wire.";
CM_ SG_ 92 TrnGearNtmAllow_B_Stat "Signal not transmitted on vehicles that do not have shift by wire.";
CM_ SG_ 92 TrnGearCmd_No_Cs "Signal not transmitted on vehicles that do not have shift by wire.";
CM_ SG_ 92 TrnValidGear_D_Cnfm "Signal not transmitted on vehicles that do not have shift by wire.";
CM_ SG_ 92 TrnNtrlTowCmd_D_Actl "Signal not transmitted on vehicles that do not have shift by wire.";
CM_ SG_ 92 TrnGearCmd_Pc_ActlPt "Signal not transmitted on vehicles that do not have shift by wire.";
CM_ SG_ 92 TrnGear_D_RqPt "Signal not transmitted on vehicles that do not have shift by wire.";
CM_ SG_ 92 TrnCmdState_B_Actl "Signal not transmitted on vehicles that do not have shift by wire.";
CM_ SG_ 92 TrnCmdCnt_B_Actl "Signal not transmitted on vehicles that do not have shift by wire.";
CM_ SG_ 92 PrkBrkActv_D_RqTrnGear "Signal not transmitted on vehicles that do not have shift by wire.";
CM_ SG_ 92 TrnGearMsgTxt_D_Rq "Signal not transmitted on vehicles that do not have shift by wire.";
CM_ SG_ 92 TrnGearCmd_No_Cnt "Signal not transmitted on vehicles that do not have shift by wire.";
CM_ SG_ 361 TrcmSrvcRqd_B_Rq "Signal not transmitted on vehicles that do not have shift by wire.";
CM_ SG_ 361 TrnGear_I_MeasMax "Signal not transmitted on vehicles that do not have shift by wire.";
CM_ SG_ 361 TrnActFalt_B_Actl "Signal not transmitted on vehicles that do not have shift by wire.";
CM_ SG_ 361 TrnCapHlth_Actl "Signal not transmitted on vehicles that do not have shift by wire.";
CM_ SG_ 361 TrnPwmFalt_B_Actl "Signal not transmitted on vehicles that do not have shift by wire.";
CM_ SG_ 93 TrnTrcmNtmState_D_Actl "Signal not transmitted on vehicles that do not have shift by wire.";
CM_ SG_ 93 TrnSns2Pos_Pc_Actl "Signal not transmitted on vehicles that do not have shift by wire.";
CM_ SG_ 93 TrnSns1Pos_Pc_Actl "Signal not transmitted on vehicles that do not have shift by wire.";
CM_ SG_ 93 TrnSecPrkStat_D_Actl "Signal not transmitted on vehicles that do not have shift by wire.";
CM_ SG_ 93 TrnNtrlTowCnfm_B_Actl "Signal not transmitted on vehicles that do not have shift by wire.";
CM_ SG_ 93 TrnGearFinalPos_B_Actl "Signal not transmitted on vehicles that do not have shift by wire.";
CM_ SG_ 93 TrnGearCnfm_No_Cs "Signal not transmitted on vehicles that do not have shift by wire.";
CM_ SG_ 93 TrnGearCnfm_No_Cnt "Signal not transmitted on vehicles that do not have shift by wire.";
CM_ SG_ 93 TrnGear_D_Actl "Signal not transmitted on vehicles that do not have shift by wire.";
CM_ SG_ 360 GsmSrvcRqd_B_Rq "Signal not transmitted on vehicles that do not have shift by wire.";
CM_ SG_ 360 TrnTrcmPwmSig_D_Actl "Signal not transmitted on vehicles that do not have shift by wire.";
CM_ SG_ 360 TrnGearPwmFalt_B_Actl "Signal not transmitted on vehicles that do not have shift by wire.";
CM_ SG_ 360 GearButtnStuck_B_Actl "Signal not transmitted on vehicles that do not have shift by wire.";
CM_ SG_ 90 TrnGsmNtmState_D_Actl "Signal not transmitted on vehicles that do not have shift by wire.";
CM_ SG_ 90 DrQltyDrv_D_StatGsm "Signal not transmitted on vehicles that do not have shift by wire.";
CM_ SG_ 90 TrnBtsiOvrrd_B_Stat "Signal not transmitted on vehicles that do not have shift by wire.";
CM_ SG_ 90 TrnValidGearRq_D_Stat "Signal not transmitted on vehicles that do not have shift by wire.";
CM_ SG_ 90 TrnGearRqCnt_B_Actl "Signal not transmitted on vehicles that do not have shift by wire.";
CM_ SG_ 90 TrnGearButtn_U_Actl "Signal not transmitted on vehicles that do not have shift by wire.";
CM_ SG_ 90 TrnGearButtn_B_ActlR2 "Signal not transmitted on vehicles that do not have shift by wire.";
CM_ SG_ 90 TrnGearButtn_B_ActlR1 "Signal not transmitted on vehicles that do not have shift by wire.";
CM_ SG_ 90 TrnGearButtn_B_ActlR0 "Signal not transmitted on vehicles that do not have shift by wire.";
CM_ SG_ 90 TrnGearButtn_B_ActlP2 "Signal not transmitted on vehicles that do not have shift by wire.";
CM_ SG_ 90 TrnGearButtn_B_ActlP1 "Signal not transmitted on vehicles that do not have shift by wire.";
CM_ SG_ 90 TrnGearButtn_B_ActlP0 "Signal not transmitted on vehicles that do not have shift by wire.";
CM_ SG_ 90 TrnGearButtn_B_ActlN2 "Signal not transmitted on vehicles that do not have shift by wire.";
CM_ SG_ 90 TrnGearButtn_B_ActlN1 "Signal not transmitted on vehicles that do not have shift by wire.";
CM_ SG_ 90 TrnGearButtn_B_ActlN0 "Signal not transmitted on vehicles that do not have shift by wire.";
CM_ SG_ 90 TrnGearButtn_B_ActlM2 "Signal not transmitted on vehicles that do not have shift by wire.";
CM_ SG_ 90 TrnGearButtn_B_ActlM1 "Signal not transmitted on vehicles that do not have shift by wire.";
CM_ SG_ 90 TrnGearButtn_B_ActlM0 "Signal not transmitted on vehicles that do not have shift by wire.";
CM_ SG_ 90 TrnGearButtn_B_ActlD2 "Signal not transmitted on vehicles that do not have shift by wire.";
CM_ SG_ 90 TrnGearButtn_B_ActlD1 "Signal not transmitted on vehicles that do not have shift by wire.";
CM_ SG_ 90 TrnGearButtn_B_ActlD0 "Signal not transmitted on vehicles that do not have shift by wire.";
CM_ SG_ 90 TrnGear_No_Cs "Signal not transmitted on vehicles that do not have shift by wire.";
CM_ SG_ 90 TrnGear_No_Cnt "Signal not transmitted on vehicles that do not have shift by wire.";
CM_ SG_ 90 TrnGear_D_RqDrv "Signal not transmitted on vehicles that do not have shift by wire.";
CM_ SG_ 90 BrkSwtchPos_B_ActlGsm "Signal not transmitted on vehicles that do not have shift by wire.";
CM_ SG_ 512 PrplWhlTotTqRq_No_Cs "Signal not transmitted on gas variants.";
CM_ SG_ 512 PrplWhlTotTqRq_No_Cnt "Signal not transmitted on gas variants.";
CM_ SG_ 512 EngAout_Tq_MxMxN "Signal not transmitted on gas variants.";
CM_ SG_ 1438 GWM_GWOnBoardTester "Signal not transmitted on gas, diesel and HEV.  Only supported on PHEV.";
CM_ SG_ 1438 GWM_GWNMProxy "Signal not transmitted on gas, diesel and HEV.  Only supported on PHEV.";
CM_ SG_ 1438 GWM_AutoSarNMReserved4 "Signal not transmitted on gas, diesel and HEV.  Only supported on PHEV.";
CM_ SG_ 1438 GWM_AutoSarNMReserved3 "Signal not transmitted on gas, diesel and HEV.  Only supported on PHEV.";
CM_ SG_ 1438 GWM_AutoSarNMReserved2 "Signal not transmitted on gas, diesel and HEV.  Only supported on PHEV.";
CM_ SG_ 1438 GWM_AutoSarNMReserved1 "Signal not transmitted on gas, diesel and HEV.  Only supported on PHEV.";
CM_ SG_ 1438 GWM_AutoSarNMNodeId "Signal not transmitted on gas, diesel and HEV.  Only supported on PHEV.";
CM_ SG_ 1438 GWM_AutoSarNMControl "Signal not transmitted on gas, diesel and HEV.  Only supported on PHEV.";
CM_ SG_ 1034 VehicleGGCCData "RCMGenSigTimeout=6000";
CM_ SG_ 376 EngAout_Aa_Actl "Signal not transmitted on HEV variants.";
CM_ SG_ 516 ApedPos_Pc_ActlArb "ABSGenSigTimeoutTime=1000";
CM_ SG_ 516 ApedPosPcActl_No_Cs "Signal not transmitted on gas and diesel variants.";
CM_ SG_ 516 EngAout3_N_Actl "Signal not transmitted on gas and diesel variants.";
CM_ SG_ 516 ApedPosPcActl_No_Cnt "Signal not transmitted on gas and diesel variants.";
CM_ SG_ 514 EngAout_Tq_VacLimSpcN "Signal not transmitted on gas and diesel variances.";
CM_ SG_ 514 EngCylSync_No_Ctr "Signal not transmitted on gas and diesel variances.";
CM_ SG_ 514 GearRvrse_D_Actl "Do not implement GearRvrse_D_Actl  until eTracker 8804151 is approved, 11/24/09";
BA_DEF_ SG_  "GenSigTimeoutTime_GWM" INT 0 100000;
BA_DEF_ BO_  "FrameGatewayNetwork" STRING ;
BA_DEF_ BO_  "FrameGatewayMS1" HEX 0 1407;
BA_DEF_ BO_  "FrameGatewayHS3" HEX 0 1407;
BA_DEF_ BO_  "FrameGatewayHS1" HEX 0 1407;
BA_DEF_ BO_  "NetworkInitialization" ENUM  "No","Yes";
BA_DEF_ BO_  "FrameGatewayId" HEX 0 1407;
BA_DEF_ BO_  "EventRateOfChange" INT 10 10000;
BA_DEF_ BO_  "GenMsgStartDelayTime" INT 0 10000;
BA_DEF_ BO_  "GenMsgNrOfRepetition" INT 0 100;
BA_DEF_ BO_  "GenMsgDelayTime" INT 0 1000;
BA_DEF_ BO_  "GenMsgCycleTime" INT 0 100000;
BA_DEF_ BO_  "GenMsgSendType" ENUM  "FixedPeriodic","Event","EnabledPeriodic","NotUsed","NotUsed","EventPeriodic","NotUsed","NotUsed","NoMsgSendType";
BA_DEF_ SG_  "U_U611_U625_MY20_Phev_Tx" ENUM  "No","Yes";
BA_DEF_ SG_  "U_CX482_CX483_MY20_Hev_Tx" ENUM  "No","Yes";
BA_DEF_ SG_  "U_CX482_CX483_MY20_Gas_Tx" ENUM  "No","Yes";
BA_DEF_ SG_  "U_CX482_CX483_MY20_Diesel_Tx" ENUM  "No","Yes";
BA_DEF_ SG_  "U_U611_U625_MY20_Hev_Tx" ENUM  "No","Yes";
BA_DEF_ SG_  "U_U611_U625_MY20_Gas_Tx" ENUM  "No","Yes";
BA_DEF_ SG_  "U_U611_U625_MY20_Diesel_Tx" ENUM  "No","Yes";
BA_DEF_ SG_  "U_LC1_B500_MY18_Gas_Tx" ENUM  "No","Yes";
BA_DEF_ SG_  "U_LC1_B500_MY18_Diesel_Tx" ENUM  "No","Yes";
BA_DEF_ SG_  "U_B500_MY18_Diesel_Tx" ENUM  "No","Yes";
BA_DEF_ SG_  "U_B500_MY18_Gas_Tx" ENUM  "No","Yes";
BA_DEF_ SG_  "U_C490_MY18_Tx" ENUM  "No","Yes";
BA_DEF_ SG_  "U_B562_MY18_Gas_Tx" ENUM  "No","Yes";
BA_DEF_ SG_  "U_C519_MY18_5_Gas_Tx" ENUM  "No","Yes";
BA_DEF_ SG_  "U_C519_MY18_5_Diesel_Tx" ENUM  "No","Yes";
BA_DEF_ SG_  "U_B515_MCA_MY17_Gas_Tx" ENUM  "No","Yes";
BA_DEF_ SG_  "U_B515_MCA_MY17_Diesel_Tx" ENUM  "No","Yes";
BA_DEF_ SG_  "U_B479_MY17_Diesel_Tx" ENUM  "No","Yes";
BA_DEF_ SG_  "U_B479_MY17_Gas_Tx" ENUM  "No","Yes";
BA_DEF_ SG_  "U_B562LC_MY15_Gas_Tx" ENUM  "No","Yes";
BA_DEF_ SG_  "U_B562LC_MY15_Diesel_Tx" ENUM  "No","Yes";
BA_DEF_ SG_  "U_U611_U625_MY20_Phev_Rx" ENUM  "No","Yes";
BA_DEF_ SG_  "U_CX482_CX483_MY20_Hev_Rx" ENUM  "No","Yes";
BA_DEF_ SG_  "U_CX482_CX483_MY20_Gas_Rx" ENUM  "No","Yes";
BA_DEF_ SG_  "U_CX482_CX483_MY20_Diesel_Rx" ENUM  "No","Yes";
BA_DEF_ SG_  "U_U611_U625_MY20_Hev_Rx" ENUM  "No","Yes";
BA_DEF_ SG_  "U_U611_U625_MY20_Gas_Rx" ENUM  "No","Yes";
BA_DEF_ SG_  "U_U611_U625_MY20_Diesel_Rx" ENUM  "No","Yes";
BA_DEF_ SG_  "U_B500_MY18_Diesel_Rx" ENUM  "No","Yes";
BA_DEF_ SG_  "U_B500_MY18_Gas_Rx" ENUM  "No","Yes";
BA_DEF_ SG_  "U_C490_MY18_Rx" ENUM  "No","Yes";
BA_DEF_ SG_  "U_B562_MY18_Gas_Rx" ENUM  "No","Yes";
BA_DEF_ SG_  "U_C519_MY18_5_Gas_Rx" ENUM  "No","Yes";
BA_DEF_ SG_  "U_C519_MY18_5_Diesel_Rx" ENUM  "No","Yes";
BA_DEF_ SG_  "U_B515_MCA_MY17_Gas_Rx" ENUM  "No","Yes";
BA_DEF_ SG_  "U_B515_MCA_MY17_Diesel_Rx" ENUM  "No","Yes";
BA_DEF_ SG_  "U_B479_MY17_Diesel_Rx" ENUM  "No","Yes";
BA_DEF_ SG_  "U_B479_MY17_Gas_Rx" ENUM  "No","Yes";
BA_DEF_ SG_  "U_B562LC_MY15_Gas_Rx" ENUM  "No","Yes";
BA_DEF_ SG_  "U_B562LC_MY15_Diesel_Rx" ENUM  "No","Yes";
BA_DEF_ SG_  "ContentDependant" ENUM  "No","Yes";
BA_DEF_ SG_  "GenSigStartValue" INT 0 1000000000;
BA_DEF_ SG_  "UsedOnPgmDBC" ENUM  "No","Yes";
BA_DEF_ SG_  "CrossOver_InfoCAN" ENUM  "No","Yes";
BA_DEF_ SG_  "WakeupSignal" ENUM  "No","Yes";
BA_DEF_ SG_  "GenSigMissingSourceValue" INT 0 1000000000;
BA_DEF_ SG_  "GenSigSendType" ENUM  "Cyclic","OnWrite","vector_leerstring","OnChange","vector_leerstring","IfActive","vector_leerstring","NoSigSendType";
BA_DEF_ BO_  "GenMsgRoutingTimeoutTime" INT 0 1000;
BA_DEF_ BO_  "MessageGateway" ENUM  "No","Yes";
BA_DEF_ BO_  "NmAsrMessage" ENUM  "No","Yes";
BA_DEF_ BO_  "TpApplType" STRING ;
BA_DEF_ BO_  "DiagState" ENUM  "No","Yes";
BA_DEF_ BO_  "DiagRequest" ENUM  "No","Yes";
BA_DEF_ BO_  "DiagResponse" ENUM  "No","Yes";
BA_DEF_ BO_  "GenMsgILSupport" ENUM  "No","Yes";
BA_DEF_DEF_  "GenSigTimeoutTime_GWM" 0;
BA_DEF_DEF_  "FrameGatewayNetwork" "NONE";
BA_DEF_DEF_  "FrameGatewayMS1" 0;
BA_DEF_DEF_  "FrameGatewayHS3" 0;
BA_DEF_DEF_  "FrameGatewayHS1" 0;
BA_DEF_DEF_  "NetworkInitialization" "Yes";
BA_DEF_DEF_  "FrameGatewayId" 0;
BA_DEF_DEF_  "EventRateOfChange" 10000;
BA_DEF_DEF_  "GenMsgStartDelayTime" 0;
BA_DEF_DEF_  "GenMsgNrOfRepetition" 1;
BA_DEF_DEF_  "GenMsgDelayTime" 20;
BA_DEF_DEF_  "GenMsgCycleTime" 0;
BA_DEF_DEF_  "GenMsgSendType" "NoMsgSendType";
BA_DEF_DEF_  "U_U611_U625_MY20_Phev_Tx" "No";
BA_DEF_DEF_  "U_CX482_CX483_MY20_Hev_Tx" "No";
BA_DEF_DEF_  "U_CX482_CX483_MY20_Gas_Tx" "No";
BA_DEF_DEF_  "U_CX482_CX483_MY20_Diesel_Tx" "No";
BA_DEF_DEF_  "U_U611_U625_MY20_Hev_Tx" "No";
BA_DEF_DEF_  "U_U611_U625_MY20_Gas_Tx" "No";
BA_DEF_DEF_  "U_U611_U625_MY20_Diesel_Tx" "No";
BA_DEF_DEF_  "U_LC1_B500_MY18_Gas_Tx" "No";
BA_DEF_DEF_  "U_LC1_B500_MY18_Diesel_Tx" "No";
BA_DEF_DEF_  "U_B500_MY18_Diesel_Tx" "No";
BA_DEF_DEF_  "U_B500_MY18_Gas_Tx" "No";
BA_DEF_DEF_  "U_C490_MY18_Tx" "No";
BA_DEF_DEF_  "U_B562_MY18_Gas_Tx" "No";
BA_DEF_DEF_  "U_C519_MY18_5_Gas_Tx" "No";
BA_DEF_DEF_  "U_C519_MY18_5_Diesel_Tx" "No";
BA_DEF_DEF_  "U_B515_MCA_MY17_Gas_Tx" "No";
BA_DEF_DEF_  "U_B515_MCA_MY17_Diesel_Tx" "No";
BA_DEF_DEF_  "U_B479_MY17_Diesel_Tx" "No";
BA_DEF_DEF_  "U_B479_MY17_Gas_Tx" "No";
BA_DEF_DEF_  "U_B562LC_MY15_Gas_Tx" "No";
BA_DEF_DEF_  "U_B562LC_MY15_Diesel_Tx" "No";
BA_DEF_DEF_  "U_U611_U625_MY20_Phev_Rx" "No";
BA_DEF_DEF_  "U_CX482_CX483_MY20_Hev_Rx" "No";
BA_DEF_DEF_  "U_CX482_CX483_MY20_Gas_Rx" "No";
BA_DEF_DEF_  "U_CX482_CX483_MY20_Diesel_Rx" "No";
BA_DEF_DEF_  "U_U611_U625_MY20_Hev_Rx" "No";
BA_DEF_DEF_  "U_U611_U625_MY20_Gas_Rx" "No";
BA_DEF_DEF_  "U_U611_U625_MY20_Diesel_Rx" "No";
BA_DEF_DEF_  "U_B500_MY18_Diesel_Rx" "No";
BA_DEF_DEF_  "U_B500_MY18_Gas_Rx" "No";
BA_DEF_DEF_  "U_C490_MY18_Rx" "No";
BA_DEF_DEF_  "U_B562_MY18_Gas_Rx" "No";
BA_DEF_DEF_  "U_C519_MY18_5_Gas_Rx" "No";
BA_DEF_DEF_  "U_C519_MY18_5_Diesel_Rx" "No";
BA_DEF_DEF_  "U_B515_MCA_MY17_Gas_Rx" "No";
BA_DEF_DEF_  "U_B515_MCA_MY17_Diesel_Rx" "No";
BA_DEF_DEF_  "U_B479_MY17_Diesel_Rx" "No";
BA_DEF_DEF_  "U_B479_MY17_Gas_Rx" "No";
BA_DEF_DEF_  "U_B562LC_MY15_Gas_Rx" "No";
BA_DEF_DEF_  "U_B562LC_MY15_Diesel_Rx" "No";
BA_DEF_DEF_  "ContentDependant" "No";
BA_DEF_DEF_  "GenSigStartValue" 0;
BA_DEF_DEF_  "UsedOnPgmDBC" "Yes";
BA_DEF_DEF_  "CrossOver_InfoCAN" "No";
BA_DEF_DEF_  "WakeupSignal" "No";
BA_DEF_DEF_  "GenSigMissingSourceValue" 0;
BA_DEF_DEF_  "GenSigSendType" "NoSigSendType";
BA_DEF_DEF_  "GenMsgRoutingTimeoutTime" 0;
BA_DEF_DEF_  "MessageGateway" "No";
BA_DEF_DEF_  "NmAsrMessage" "No";
BA_DEF_DEF_  "TpApplType" "";
BA_DEF_DEF_  "DiagState" "No";
BA_DEF_DEF_  "DiagRequest" "No";
BA_DEF_DEF_  "DiagResponse" "No";
BA_DEF_DEF_  "GenMsgILSupport" "Yes";
BA_ "NetworkInitialization" BO_ 1427 0;
BA_ "GenMsgCycleTime" BO_ 1427 1000;
BA_ "GenMsgSendType" BO_ 1427 0;
BA_ "NmAsrMessage" BO_ 1427 1;
BA_ "GenMsgILSupport" BO_ 1427 0;
BA_ "NetworkInitialization" BO_ 1430 0;
BA_ "GenMsgCycleTime" BO_ 1430 1000;
BA_ "GenMsgSendType" BO_ 1430 0;
BA_ "NmAsrMessage" BO_ 1430 1;
BA_ "GenMsgILSupport" BO_ 1430 0;
BA_ "GenMsgCycleTime" BO_ 1082 1000;
BA_ "GenMsgSendType" BO_ 1082 5;
BA_ "FrameGatewayNetwork" BO_ 609 "HS1_CAN";
BA_ "FrameGatewayHS1" BO_ 609 609;
BA_ "FrameGatewayId" BO_ 609 609;
BA_ "NetworkInitialization" BO_ 1462 0;
BA_ "GenMsgCycleTime" BO_ 1462 1000;
BA_ "GenMsgSendType" BO_ 1462 0;
BA_ "NmAsrMessage" BO_ 1462 1;
BA_ "GenMsgILSupport" BO_ 1462 0;
BA_ "FrameGatewayNetwork" BO_ 92 "HS1_CAN";
BA_ "FrameGatewayHS1" BO_ 92 92;
BA_ "FrameGatewayId" BO_ 92 92;
BA_ "GenMsgCycleTime" BO_ 361 1000;
BA_ "GenMsgSendType" BO_ 361 0;
BA_ "GenMsgCycleTime" BO_ 93 100;
BA_ "GenMsgSendType" BO_ 93 5;
BA_ "GenMsgCycleTime" BO_ 360 1000;
BA_ "GenMsgSendType" BO_ 360 0;
BA_ "GenMsgCycleTime" BO_ 90 100;
BA_ "GenMsgSendType" BO_ 90 5;
BA_ "NetworkInitialization" BO_ 1809 0;
BA_ "GenMsgDelayTime" BO_ 1809 0;
BA_ "GenMsgSendType" BO_ 1809 1;
BA_ "DiagRequest" BO_ 1809 1;
BA_ "GenMsgILSupport" BO_ 1809 0;
BA_ "NetworkInitialization" BO_ 1842 0;
BA_ "GenMsgDelayTime" BO_ 1842 0;
BA_ "GenMsgSendType" BO_ 1842 1;
BA_ "DiagRequest" BO_ 1842 1;
BA_ "GenMsgILSupport" BO_ 1842 0;
BA_ "NetworkInitialization" BO_ 1817 0;
BA_ "GenMsgDelayTime" BO_ 1817 0;
BA_ "GenMsgSendType" BO_ 1817 1;
BA_ "DiagResponse" BO_ 1817 1;
BA_ "GenMsgILSupport" BO_ 1817 0;
BA_ "NetworkInitialization" BO_ 1850 0;
BA_ "GenMsgDelayTime" BO_ 1850 0;
BA_ "GenMsgSendType" BO_ 1850 1;
BA_ "DiagResponse" BO_ 1850 1;
BA_ "GenMsgILSupport" BO_ 1850 0;
BA_ "NetworkInitialization" BO_ 1889 0;
BA_ "GenMsgDelayTime" BO_ 1889 0;
BA_ "GenMsgSendType" BO_ 1889 1;
BA_ "DiagRequest" BO_ 1889 1;
BA_ "GenMsgILSupport" BO_ 1889 0;
BA_ "NetworkInitialization" BO_ 1897 0;
BA_ "GenMsgDelayTime" BO_ 1897 0;
BA_ "GenMsgSendType" BO_ 1897 1;
BA_ "DiagResponse" BO_ 1897 1;
BA_ "GenMsgILSupport" BO_ 1897 0;
BA_ "FrameGatewayNetwork" BO_ 512 "HS1_CAN";
BA_ "FrameGatewayHS1" BO_ 512 512;
BA_ "FrameGatewayId" BO_ 512 512;
BA_ "FrameGatewayNetwork" BO_ 936 "HS1_CAN";
BA_ "FrameGatewayHS1" BO_ 936 936;
BA_ "FrameGatewayId" BO_ 936 936;
BA_ "GenMsgDelayTime" BO_ 936 10;
BA_ "GenMsgDelayTime" BO_ 570 10;
BA_ "GenMsgCycleTime" BO_ 570 20;
BA_ "GenMsgSendType" BO_ 570 0;
BA_ "GenMsgDelayTime" BO_ 76 10;
BA_ "GenMsgCycleTime" BO_ 76 100;
BA_ "GenMsgSendType" BO_ 76 5;
BA_ "GenMsgDelayTime" BO_ 120 10;
BA_ "GenMsgCycleTime" BO_ 120 50;
BA_ "GenMsgSendType" BO_ 120 0;
BA_ "NetworkInitialization" BO_ 1665 0;
BA_ "GenMsgSendType" BO_ 1665 1;
BA_ "TpApplType" BO_ 1665 "DiagUUDTResponse";
BA_ "GenMsgILSupport" BO_ 1665 0;
BA_ "NetworkInitialization" BO_ 2041 0;
BA_ "GenMsgDelayTime" BO_ 2041 0;
BA_ "GenMsgSendType" BO_ 2041 1;
BA_ "GenMsgILSupport" BO_ 2041 0;
BA_ "NetworkInitialization" BO_ 1438 0;
BA_ "GenMsgCycleTime" BO_ 1438 1000;
BA_ "GenMsgSendType" BO_ 1438 0;
BA_ "NmAsrMessage" BO_ 1438 1;
BA_ "GenMsgILSupport" BO_ 1438 0;
BA_ "FrameGatewayNetwork" BO_ 1034 "HS1_CAN";
BA_ "FrameGatewayHS1" BO_ 1034 1034;
BA_ "FrameGatewayId" BO_ 1034 1034;
BA_ "FrameGatewayNetwork" BO_ 376 "HS1_CAN";
BA_ "FrameGatewayHS1" BO_ 376 376;
BA_ "FrameGatewayId" BO_ 376 376;
BA_ "GenMsgStartDelayTime" BO_ 376 300;
BA_ "FrameGatewayNetwork" BO_ 516 "HS1_CAN";
BA_ "FrameGatewayHS1" BO_ 516 516;
BA_ "FrameGatewayId" BO_ 516 516;
BA_ "GenMsgDelayTime" BO_ 516 5;
BA_ "FrameGatewayNetwork" BO_ 514 "HS1_CAN";
BA_ "FrameGatewayHS1" BO_ 514 514;
BA_ "FrameGatewayId" BO_ 514 514;
BA_ "GenMsgDelayTime" BO_ 514 5;
BA_ "FrameGatewayNetwork" BO_ 1003 "HS1_CAN";
BA_ "FrameGatewayHS1" BO_ 1003 1003;
BA_ "FrameGatewayId" BO_ 1003 1003;
BA_ "ContentDependant" SG_ 1427 TRCM_GWOnBoardTester 1;
BA_ "GenSigStartValue" SG_ 1427 TRCM_GWOnBoardTester 255;
BA_ "ContentDependant" SG_ 1427 TRCM_GWNMProxy 1;
BA_ "GenSigStartValue" SG_ 1427 TRCM_GWNMProxy 255;
BA_ "ContentDependant" SG_ 1427 TRCM_AutoSarNMReserved4 1;
BA_ "GenSigStartValue" SG_ 1427 TRCM_AutoSarNMReserved4 255;
BA_ "ContentDependant" SG_ 1427 TRCM_AutoSarNMReserved3 1;
BA_ "GenSigStartValue" SG_ 1427 TRCM_AutoSarNMReserved3 255;
BA_ "ContentDependant" SG_ 1427 TRCM_AutoSarNMReserved2 1;
BA_ "GenSigStartValue" SG_ 1427 TRCM_AutoSarNMReserved2 255;
BA_ "ContentDependant" SG_ 1427 TRCM_AutoSarNMReserved1 1;
BA_ "GenSigStartValue" SG_ 1427 TRCM_AutoSarNMReserved1 255;
BA_ "ContentDependant" SG_ 1427 TRCM_AutoSarNMNodeId 1;
BA_ "GenSigStartValue" SG_ 1427 TRCM_AutoSarNMNodeId 147;
BA_ "ContentDependant" SG_ 1427 TRCM_AutoSarNMControl 1;
BA_ "U_U611_U625_MY20_Hev_Tx" SG_ 1430 ABS_GWOnBoardTester 1;
BA_ "U_U611_U625_MY20_Gas_Tx" SG_ 1430 ABS_GWOnBoardTester 1;
BA_ "U_U611_U625_MY20_Diesel_Tx" SG_ 1430 ABS_GWOnBoardTester 1;
BA_ "U_B500_MY18_Diesel_Tx" SG_ 1430 ABS_GWOnBoardTester 1;
BA_ "U_B500_MY18_Gas_Tx" SG_ 1430 ABS_GWOnBoardTester 1;
BA_ "U_C490_MY18_Tx" SG_ 1430 ABS_GWOnBoardTester 1;
BA_ "U_B562_MY18_Gas_Tx" SG_ 1430 ABS_GWOnBoardTester 1;
BA_ "U_C519_MY18_5_Gas_Tx" SG_ 1430 ABS_GWOnBoardTester 1;
BA_ "U_C519_MY18_5_Diesel_Tx" SG_ 1430 ABS_GWOnBoardTester 1;
BA_ "U_B500_MY18_Diesel_Rx" SG_ 1430 ABS_GWOnBoardTester 1;
BA_ "U_B500_MY18_Gas_Rx" SG_ 1430 ABS_GWOnBoardTester 1;
BA_ "U_U611_U625_MY20_Phev_Rx" SG_ 1430 ABS_GWOnBoardTester 1;
BA_ "U_U611_U625_MY20_Hev_Rx" SG_ 1430 ABS_GWOnBoardTester 1;
BA_ "U_U611_U625_MY20_Gas_Rx" SG_ 1430 ABS_GWOnBoardTester 1;
BA_ "U_U611_U625_MY20_Diesel_Rx" SG_ 1430 ABS_GWOnBoardTester 1;
BA_ "U_C519_MY18_5_Gas_Rx" SG_ 1430 ABS_GWOnBoardTester 1;
BA_ "U_C519_MY18_5_Diesel_Rx" SG_ 1430 ABS_GWOnBoardTester 1;
BA_ "ContentDependant" SG_ 1430 ABS_GWOnBoardTester 1;
BA_ "GenSigStartValue" SG_ 1430 ABS_GWOnBoardTester 255;
BA_ "U_U611_U625_MY20_Hev_Tx" SG_ 1430 ABS_GWNMProxy 1;
BA_ "U_U611_U625_MY20_Gas_Tx" SG_ 1430 ABS_GWNMProxy 1;
BA_ "U_U611_U625_MY20_Diesel_Tx" SG_ 1430 ABS_GWNMProxy 1;
BA_ "U_B500_MY18_Diesel_Tx" SG_ 1430 ABS_GWNMProxy 1;
BA_ "U_B500_MY18_Gas_Tx" SG_ 1430 ABS_GWNMProxy 1;
BA_ "U_C490_MY18_Tx" SG_ 1430 ABS_GWNMProxy 1;
BA_ "U_B562_MY18_Gas_Tx" SG_ 1430 ABS_GWNMProxy 1;
BA_ "U_C519_MY18_5_Gas_Tx" SG_ 1430 ABS_GWNMProxy 1;
BA_ "U_C519_MY18_5_Diesel_Tx" SG_ 1430 ABS_GWNMProxy 1;
BA_ "U_B500_MY18_Diesel_Rx" SG_ 1430 ABS_GWNMProxy 1;
BA_ "U_B500_MY18_Gas_Rx" SG_ 1430 ABS_GWNMProxy 1;
BA_ "U_U611_U625_MY20_Phev_Rx" SG_ 1430 ABS_GWNMProxy 1;
BA_ "U_U611_U625_MY20_Hev_Rx" SG_ 1430 ABS_GWNMProxy 1;
BA_ "U_U611_U625_MY20_Gas_Rx" SG_ 1430 ABS_GWNMProxy 1;
BA_ "U_U611_U625_MY20_Diesel_Rx" SG_ 1430 ABS_GWNMProxy 1;
BA_ "U_C519_MY18_5_Gas_Rx" SG_ 1430 ABS_GWNMProxy 1;
BA_ "U_C519_MY18_5_Diesel_Rx" SG_ 1430 ABS_GWNMProxy 1;
BA_ "ContentDependant" SG_ 1430 ABS_GWNMProxy 1;
BA_ "GenSigStartValue" SG_ 1430 ABS_GWNMProxy 255;
BA_ "U_U611_U625_MY20_Hev_Tx" SG_ 1430 ABS_AutoSarNMReserved4 1;
BA_ "U_U611_U625_MY20_Gas_Tx" SG_ 1430 ABS_AutoSarNMReserved4 1;
BA_ "U_U611_U625_MY20_Diesel_Tx" SG_ 1430 ABS_AutoSarNMReserved4 1;
BA_ "U_B500_MY18_Diesel_Tx" SG_ 1430 ABS_AutoSarNMReserved4 1;
BA_ "U_B500_MY18_Gas_Tx" SG_ 1430 ABS_AutoSarNMReserved4 1;
BA_ "U_C490_MY18_Tx" SG_ 1430 ABS_AutoSarNMReserved4 1;
BA_ "U_B562_MY18_Gas_Tx" SG_ 1430 ABS_AutoSarNMReserved4 1;
BA_ "U_C519_MY18_5_Gas_Tx" SG_ 1430 ABS_AutoSarNMReserved4 1;
BA_ "U_C519_MY18_5_Diesel_Tx" SG_ 1430 ABS_AutoSarNMReserved4 1;
BA_ "U_B500_MY18_Diesel_Rx" SG_ 1430 ABS_AutoSarNMReserved4 1;
BA_ "U_B500_MY18_Gas_Rx" SG_ 1430 ABS_AutoSarNMReserved4 1;
BA_ "U_U611_U625_MY20_Phev_Rx" SG_ 1430 ABS_AutoSarNMReserved4 1;
BA_ "U_U611_U625_MY20_Hev_Rx" SG_ 1430 ABS_AutoSarNMReserved4 1;
BA_ "U_U611_U625_MY20_Gas_Rx" SG_ 1430 ABS_AutoSarNMReserved4 1;
BA_ "U_U611_U625_MY20_Diesel_Rx" SG_ 1430 ABS_AutoSarNMReserved4 1;
BA_ "U_C519_MY18_5_Gas_Rx" SG_ 1430 ABS_AutoSarNMReserved4 1;
BA_ "U_C519_MY18_5_Diesel_Rx" SG_ 1430 ABS_AutoSarNMReserved4 1;
BA_ "ContentDependant" SG_ 1430 ABS_AutoSarNMReserved4 1;
BA_ "GenSigStartValue" SG_ 1430 ABS_AutoSarNMReserved4 255;
BA_ "U_U611_U625_MY20_Hev_Tx" SG_ 1430 ABS_AutoSarNMReserved3 1;
BA_ "U_U611_U625_MY20_Gas_Tx" SG_ 1430 ABS_AutoSarNMReserved3 1;
BA_ "U_U611_U625_MY20_Diesel_Tx" SG_ 1430 ABS_AutoSarNMReserved3 1;
BA_ "U_B500_MY18_Diesel_Tx" SG_ 1430 ABS_AutoSarNMReserved3 1;
BA_ "U_B500_MY18_Gas_Tx" SG_ 1430 ABS_AutoSarNMReserved3 1;
BA_ "U_C490_MY18_Tx" SG_ 1430 ABS_AutoSarNMReserved3 1;
BA_ "U_B562_MY18_Gas_Tx" SG_ 1430 ABS_AutoSarNMReserved3 1;
BA_ "U_C519_MY18_5_Gas_Tx" SG_ 1430 ABS_AutoSarNMReserved3 1;
BA_ "U_C519_MY18_5_Diesel_Tx" SG_ 1430 ABS_AutoSarNMReserved3 1;
BA_ "U_B500_MY18_Diesel_Rx" SG_ 1430 ABS_AutoSarNMReserved3 1;
BA_ "U_B500_MY18_Gas_Rx" SG_ 1430 ABS_AutoSarNMReserved3 1;
BA_ "U_U611_U625_MY20_Phev_Rx" SG_ 1430 ABS_AutoSarNMReserved3 1;
BA_ "U_U611_U625_MY20_Hev_Rx" SG_ 1430 ABS_AutoSarNMReserved3 1;
BA_ "U_U611_U625_MY20_Gas_Rx" SG_ 1430 ABS_AutoSarNMReserved3 1;
BA_ "U_U611_U625_MY20_Diesel_Rx" SG_ 1430 ABS_AutoSarNMReserved3 1;
BA_ "U_C519_MY18_5_Gas_Rx" SG_ 1430 ABS_AutoSarNMReserved3 1;
BA_ "U_C519_MY18_5_Diesel_Rx" SG_ 1430 ABS_AutoSarNMReserved3 1;
BA_ "ContentDependant" SG_ 1430 ABS_AutoSarNMReserved3 1;
BA_ "GenSigStartValue" SG_ 1430 ABS_AutoSarNMReserved3 255;
BA_ "U_U611_U625_MY20_Hev_Tx" SG_ 1430 ABS_AutoSarNMReserved2 1;
BA_ "U_U611_U625_MY20_Gas_Tx" SG_ 1430 ABS_AutoSarNMReserved2 1;
BA_ "U_U611_U625_MY20_Diesel_Tx" SG_ 1430 ABS_AutoSarNMReserved2 1;
BA_ "U_B500_MY18_Diesel_Tx" SG_ 1430 ABS_AutoSarNMReserved2 1;
BA_ "U_B500_MY18_Gas_Tx" SG_ 1430 ABS_AutoSarNMReserved2 1;
BA_ "U_C490_MY18_Tx" SG_ 1430 ABS_AutoSarNMReserved2 1;
BA_ "U_B562_MY18_Gas_Tx" SG_ 1430 ABS_AutoSarNMReserved2 1;
BA_ "U_C519_MY18_5_Gas_Tx" SG_ 1430 ABS_AutoSarNMReserved2 1;
BA_ "U_C519_MY18_5_Diesel_Tx" SG_ 1430 ABS_AutoSarNMReserved2 1;
BA_ "U_B500_MY18_Diesel_Rx" SG_ 1430 ABS_AutoSarNMReserved2 1;
BA_ "U_B500_MY18_Gas_Rx" SG_ 1430 ABS_AutoSarNMReserved2 1;
BA_ "U_U611_U625_MY20_Phev_Rx" SG_ 1430 ABS_AutoSarNMReserved2 1;
BA_ "U_U611_U625_MY20_Hev_Rx" SG_ 1430 ABS_AutoSarNMReserved2 1;
BA_ "U_U611_U625_MY20_Gas_Rx" SG_ 1430 ABS_AutoSarNMReserved2 1;
BA_ "U_U611_U625_MY20_Diesel_Rx" SG_ 1430 ABS_AutoSarNMReserved2 1;
BA_ "U_C519_MY18_5_Gas_Rx" SG_ 1430 ABS_AutoSarNMReserved2 1;
BA_ "U_C519_MY18_5_Diesel_Rx" SG_ 1430 ABS_AutoSarNMReserved2 1;
BA_ "ContentDependant" SG_ 1430 ABS_AutoSarNMReserved2 1;
BA_ "GenSigStartValue" SG_ 1430 ABS_AutoSarNMReserved2 255;
BA_ "U_U611_U625_MY20_Hev_Tx" SG_ 1430 ABS_AutoSarNMReserved1 1;
BA_ "U_U611_U625_MY20_Gas_Tx" SG_ 1430 ABS_AutoSarNMReserved1 1;
BA_ "U_U611_U625_MY20_Diesel_Tx" SG_ 1430 ABS_AutoSarNMReserved1 1;
BA_ "U_B500_MY18_Diesel_Tx" SG_ 1430 ABS_AutoSarNMReserved1 1;
BA_ "U_B500_MY18_Gas_Tx" SG_ 1430 ABS_AutoSarNMReserved1 1;
BA_ "U_C490_MY18_Tx" SG_ 1430 ABS_AutoSarNMReserved1 1;
BA_ "U_B562_MY18_Gas_Tx" SG_ 1430 ABS_AutoSarNMReserved1 1;
BA_ "U_C519_MY18_5_Gas_Tx" SG_ 1430 ABS_AutoSarNMReserved1 1;
BA_ "U_C519_MY18_5_Diesel_Tx" SG_ 1430 ABS_AutoSarNMReserved1 1;
BA_ "U_B500_MY18_Diesel_Rx" SG_ 1430 ABS_AutoSarNMReserved1 1;
BA_ "U_B500_MY18_Gas_Rx" SG_ 1430 ABS_AutoSarNMReserved1 1;
BA_ "U_U611_U625_MY20_Phev_Rx" SG_ 1430 ABS_AutoSarNMReserved1 1;
BA_ "U_U611_U625_MY20_Hev_Rx" SG_ 1430 ABS_AutoSarNMReserved1 1;
BA_ "U_U611_U625_MY20_Gas_Rx" SG_ 1430 ABS_AutoSarNMReserved1 1;
BA_ "U_U611_U625_MY20_Diesel_Rx" SG_ 1430 ABS_AutoSarNMReserved1 1;
BA_ "U_C519_MY18_5_Gas_Rx" SG_ 1430 ABS_AutoSarNMReserved1 1;
BA_ "U_C519_MY18_5_Diesel_Rx" SG_ 1430 ABS_AutoSarNMReserved1 1;
BA_ "ContentDependant" SG_ 1430 ABS_AutoSarNMReserved1 1;
BA_ "GenSigStartValue" SG_ 1430 ABS_AutoSarNMReserved1 255;
BA_ "U_U611_U625_MY20_Hev_Tx" SG_ 1430 ABS_AutoSarNMNodeId 1;
BA_ "U_U611_U625_MY20_Gas_Tx" SG_ 1430 ABS_AutoSarNMNodeId 1;
BA_ "U_U611_U625_MY20_Diesel_Tx" SG_ 1430 ABS_AutoSarNMNodeId 1;
BA_ "U_B500_MY18_Diesel_Tx" SG_ 1430 ABS_AutoSarNMNodeId 1;
BA_ "U_B500_MY18_Gas_Tx" SG_ 1430 ABS_AutoSarNMNodeId 1;
BA_ "U_C490_MY18_Tx" SG_ 1430 ABS_AutoSarNMNodeId 1;
BA_ "U_B562_MY18_Gas_Tx" SG_ 1430 ABS_AutoSarNMNodeId 1;
BA_ "U_C519_MY18_5_Gas_Tx" SG_ 1430 ABS_AutoSarNMNodeId 1;
BA_ "U_C519_MY18_5_Diesel_Tx" SG_ 1430 ABS_AutoSarNMNodeId 1;
BA_ "U_B500_MY18_Diesel_Rx" SG_ 1430 ABS_AutoSarNMNodeId 1;
BA_ "U_B500_MY18_Gas_Rx" SG_ 1430 ABS_AutoSarNMNodeId 1;
BA_ "U_U611_U625_MY20_Phev_Rx" SG_ 1430 ABS_AutoSarNMNodeId 1;
BA_ "U_U611_U625_MY20_Hev_Rx" SG_ 1430 ABS_AutoSarNMNodeId 1;
BA_ "U_U611_U625_MY20_Gas_Rx" SG_ 1430 ABS_AutoSarNMNodeId 1;
BA_ "U_U611_U625_MY20_Diesel_Rx" SG_ 1430 ABS_AutoSarNMNodeId 1;
BA_ "U_C519_MY18_5_Gas_Rx" SG_ 1430 ABS_AutoSarNMNodeId 1;
BA_ "U_C519_MY18_5_Diesel_Rx" SG_ 1430 ABS_AutoSarNMNodeId 1;
BA_ "ContentDependant" SG_ 1430 ABS_AutoSarNMNodeId 1;
BA_ "GenSigStartValue" SG_ 1430 ABS_AutoSarNMNodeId 150;
BA_ "U_U611_U625_MY20_Hev_Tx" SG_ 1430 ABS_AutoSarNMControl 1;
BA_ "U_U611_U625_MY20_Gas_Tx" SG_ 1430 ABS_AutoSarNMControl 1;
BA_ "U_U611_U625_MY20_Diesel_Tx" SG_ 1430 ABS_AutoSarNMControl 1;
BA_ "U_B500_MY18_Diesel_Tx" SG_ 1430 ABS_AutoSarNMControl 1;
BA_ "U_B500_MY18_Gas_Tx" SG_ 1430 ABS_AutoSarNMControl 1;
BA_ "U_C490_MY18_Tx" SG_ 1430 ABS_AutoSarNMControl 1;
BA_ "U_B562_MY18_Gas_Tx" SG_ 1430 ABS_AutoSarNMControl 1;
BA_ "U_C519_MY18_5_Gas_Tx" SG_ 1430 ABS_AutoSarNMControl 1;
BA_ "U_C519_MY18_5_Diesel_Tx" SG_ 1430 ABS_AutoSarNMControl 1;
BA_ "U_B500_MY18_Diesel_Rx" SG_ 1430 ABS_AutoSarNMControl 1;
BA_ "U_B500_MY18_Gas_Rx" SG_ 1430 ABS_AutoSarNMControl 1;
BA_ "U_U611_U625_MY20_Phev_Rx" SG_ 1430 ABS_AutoSarNMControl 1;
BA_ "U_U611_U625_MY20_Hev_Rx" SG_ 1430 ABS_AutoSarNMControl 1;
BA_ "U_U611_U625_MY20_Gas_Rx" SG_ 1430 ABS_AutoSarNMControl 1;
BA_ "U_U611_U625_MY20_Diesel_Rx" SG_ 1430 ABS_AutoSarNMControl 1;
BA_ "U_C519_MY18_5_Gas_Rx" SG_ 1430 ABS_AutoSarNMControl 1;
BA_ "U_C519_MY18_5_Diesel_Rx" SG_ 1430 ABS_AutoSarNMControl 1;
BA_ "ContentDependant" SG_ 1430 ABS_AutoSarNMControl 1;
BA_ "U_U611_U625_MY20_Phev_Rx" SG_ 1082 EsaOn_B_Rq_UB 1;
BA_ "U_CX482_CX483_MY20_Hev_Rx" SG_ 1082 EsaOn_B_Rq_UB 1;
BA_ "U_CX482_CX483_MY20_Gas_Rx" SG_ 1082 EsaOn_B_Rq_UB 1;
BA_ "U_CX482_CX483_MY20_Diesel_Rx" SG_ 1082 EsaOn_B_Rq_UB 1;
BA_ "U_U611_U625_MY20_Hev_Rx" SG_ 1082 EsaOn_B_Rq_UB 1;
BA_ "U_U611_U625_MY20_Gas_Rx" SG_ 1082 EsaOn_B_Rq_UB 1;
BA_ "U_U611_U625_MY20_Diesel_Rx" SG_ 1082 EsaOn_B_Rq_UB 1;
BA_ "U_C519_MY18_5_Gas_Rx" SG_ 1082 EsaOn_B_Rq_UB 1;
BA_ "U_C519_MY18_5_Diesel_Rx" SG_ 1082 EsaOn_B_Rq_UB 1;
BA_ "U_U611_U625_MY20_Phev_Rx" SG_ 1082 EsaOn_B_Rq 1;
BA_ "U_CX482_CX483_MY20_Hev_Rx" SG_ 1082 EsaOn_B_Rq 1;
BA_ "U_CX482_CX483_MY20_Gas_Rx" SG_ 1082 EsaOn_B_Rq 1;
BA_ "U_CX482_CX483_MY20_Diesel_Rx" SG_ 1082 EsaOn_B_Rq 1;
BA_ "U_U611_U625_MY20_Hev_Rx" SG_ 1082 EsaOn_B_Rq 1;
BA_ "U_U611_U625_MY20_Gas_Rx" SG_ 1082 EsaOn_B_Rq 1;
BA_ "U_U611_U625_MY20_Diesel_Rx" SG_ 1082 EsaOn_B_Rq 1;
BA_ "U_C519_MY18_5_Gas_Rx" SG_ 1082 EsaOn_B_Rq 1;
BA_ "U_C519_MY18_5_Diesel_Rx" SG_ 1082 EsaOn_B_Rq 1;
BA_ "GenSigSendType" SG_ 1082 EsaOn_B_Rq 3;
BA_ "GenSigStartValue" SG_ 1082 EsaOn_B_Rq 1;
BA_ "GenSigSendType" SG_ 1082 RearDiffLck_D_RqArb 3;
BA_ "GenSigStartValue" SG_ 1082 RearDiffLck_D_RqArb 3;
BA_ "GenSigSendType" SG_ 1082 AwdMde_D_RqArb 3;
BA_ "GenSigStartValue" SG_ 1082 AwdMde_D_RqArb 5;
BA_ "U_CX482_CX483_MY20_Hev_Rx" SG_ 1082 SelDrvMdeTxtReset_B_Rq 1;
BA_ "U_CX482_CX483_MY20_Gas_Rx" SG_ 1082 SelDrvMdeTxtReset_B_Rq 1;
BA_ "U_CX482_CX483_MY20_Diesel_Rx" SG_ 1082 SelDrvMdeTxtReset_B_Rq 1;
BA_ "U_U611_U625_MY20_Hev_Rx" SG_ 1082 SelDrvMdeTxtReset_B_Rq 1;
BA_ "U_U611_U625_MY20_Gas_Rx" SG_ 1082 SelDrvMdeTxtReset_B_Rq 1;
BA_ "U_U611_U625_MY20_Diesel_Rx" SG_ 1082 SelDrvMdeTxtReset_B_Rq 1;
BA_ "U_C519_MY18_5_Gas_Rx" SG_ 1082 SelDrvMdeTxtReset_B_Rq 1;
BA_ "U_C519_MY18_5_Diesel_Rx" SG_ 1082 SelDrvMdeTxtReset_B_Rq 1;
BA_ "GenSigSendType" SG_ 1082 SelDrvMdeTxtReset_B_Rq 3;
BA_ "U_U611_U625_MY20_Phev_Rx" SG_ 1082 DrvInputRequired_B_Rq_UB 1;
BA_ "U_CX482_CX483_MY20_Hev_Rx" SG_ 1082 DrvInputRequired_B_Rq_UB 1;
BA_ "U_CX482_CX483_MY20_Gas_Rx" SG_ 1082 DrvInputRequired_B_Rq_UB 1;
BA_ "U_CX482_CX483_MY20_Diesel_Rx" SG_ 1082 DrvInputRequired_B_Rq_UB 1;
BA_ "U_U611_U625_MY20_Hev_Rx" SG_ 1082 DrvInputRequired_B_Rq_UB 1;
BA_ "U_U611_U625_MY20_Gas_Rx" SG_ 1082 DrvInputRequired_B_Rq_UB 1;
BA_ "U_B500_MY18_Diesel_Rx" SG_ 1082 DrvInputRequired_B_Rq_UB 1;
BA_ "U_B500_MY18_Gas_Rx" SG_ 1082 DrvInputRequired_B_Rq_UB 1;
BA_ "U_C519_MY18_5_Gas_Rx" SG_ 1082 DrvInputRequired_B_Rq_UB 1;
BA_ "U_C519_MY18_5_Diesel_Rx" SG_ 1082 DrvInputRequired_B_Rq_UB 1;
BA_ "U_B479_MY17_Diesel_Rx" SG_ 1082 DrvInputRequired_B_Rq_UB 1;
BA_ "U_B479_MY17_Gas_Rx" SG_ 1082 DrvInputRequired_B_Rq_UB 1;
BA_ "U_U611_U625_MY20_Phev_Rx" SG_ 1082 DrvInputRequired_B_Rq 1;
BA_ "U_CX482_CX483_MY20_Hev_Rx" SG_ 1082 DrvInputRequired_B_Rq 1;
BA_ "U_CX482_CX483_MY20_Gas_Rx" SG_ 1082 DrvInputRequired_B_Rq 1;
BA_ "U_CX482_CX483_MY20_Diesel_Rx" SG_ 1082 DrvInputRequired_B_Rq 1;
BA_ "U_U611_U625_MY20_Hev_Rx" SG_ 1082 DrvInputRequired_B_Rq 1;
BA_ "U_U611_U625_MY20_Gas_Rx" SG_ 1082 DrvInputRequired_B_Rq 1;
BA_ "U_B500_MY18_Diesel_Rx" SG_ 1082 DrvInputRequired_B_Rq 1;
BA_ "U_B500_MY18_Gas_Rx" SG_ 1082 DrvInputRequired_B_Rq 1;
BA_ "U_C519_MY18_5_Gas_Rx" SG_ 1082 DrvInputRequired_B_Rq 1;
BA_ "U_C519_MY18_5_Diesel_Rx" SG_ 1082 DrvInputRequired_B_Rq 1;
BA_ "U_B515_MCA_MY17_Gas_Rx" SG_ 1082 DrvInputRequired_B_Rq 1;
BA_ "U_B515_MCA_MY17_Diesel_Rx" SG_ 1082 DrvInputRequired_B_Rq 1;
BA_ "U_B479_MY17_Diesel_Rx" SG_ 1082 DrvInputRequired_B_Rq 1;
BA_ "U_B479_MY17_Gas_Rx" SG_ 1082 DrvInputRequired_B_Rq 1;
BA_ "GenSigSendType" SG_ 1082 DrvInputRequired_B_Rq 3;
BA_ "WakeupSignal" SG_ 1082 DrvInputRequired_B_Rq 1;
BA_ "U_CX482_CX483_MY20_Hev_Rx" SG_ 1082 SelDrvMdeSwtch_D_Stat2_UB 1;
BA_ "U_CX482_CX483_MY20_Gas_Rx" SG_ 1082 SelDrvMdeSwtch_D_Stat2_UB 1;
BA_ "U_CX482_CX483_MY20_Diesel_Rx" SG_ 1082 SelDrvMdeSwtch_D_Stat2_UB 1;
BA_ "U_B500_MY18_Diesel_Rx" SG_ 1082 SelDrvMdeSwtch_D_Stat2_UB 1;
BA_ "U_B500_MY18_Gas_Rx" SG_ 1082 SelDrvMdeSwtch_D_Stat2_UB 1;
BA_ "U_C519_MY18_5_Gas_Rx" SG_ 1082 SelDrvMdeSwtch_D_Stat2_UB 1;
BA_ "U_C519_MY18_5_Diesel_Rx" SG_ 1082 SelDrvMdeSwtch_D_Stat2_UB 1;
BA_ "U_B479_MY17_Diesel_Rx" SG_ 1082 SelDrvMdeSwtch_D_Stat2_UB 1;
BA_ "U_B479_MY17_Gas_Rx" SG_ 1082 SelDrvMdeSwtch_D_Stat2_UB 1;
BA_ "U_CX482_CX483_MY20_Hev_Rx" SG_ 1082 SelDrvMdeSwtch_D_Stat2 1;
BA_ "U_CX482_CX483_MY20_Gas_Rx" SG_ 1082 SelDrvMdeSwtch_D_Stat2 1;
BA_ "U_CX482_CX483_MY20_Diesel_Rx" SG_ 1082 SelDrvMdeSwtch_D_Stat2 1;
BA_ "U_U611_U625_MY20_Hev_Rx" SG_ 1082 SelDrvMdeSwtch_D_Stat2 1;
BA_ "U_U611_U625_MY20_Gas_Rx" SG_ 1082 SelDrvMdeSwtch_D_Stat2 1;
BA_ "U_U611_U625_MY20_Diesel_Rx" SG_ 1082 SelDrvMdeSwtch_D_Stat2 1;
BA_ "U_B500_MY18_Diesel_Rx" SG_ 1082 SelDrvMdeSwtch_D_Stat2 1;
BA_ "U_B500_MY18_Gas_Rx" SG_ 1082 SelDrvMdeSwtch_D_Stat2 1;
BA_ "U_C519_MY18_5_Gas_Rx" SG_ 1082 SelDrvMdeSwtch_D_Stat2 1;
BA_ "U_C519_MY18_5_Diesel_Rx" SG_ 1082 SelDrvMdeSwtch_D_Stat2 1;
BA_ "U_B479_MY17_Diesel_Rx" SG_ 1082 SelDrvMdeSwtch_D_Stat2 1;
BA_ "U_B479_MY17_Gas_Rx" SG_ 1082 SelDrvMdeSwtch_D_Stat2 1;
BA_ "GenSigSendType" SG_ 1082 SelDrvMdeSwtch_D_Stat2 3;
BA_ "U_CX482_CX483_MY20_Hev_Rx" SG_ 1082 SelDrvMdeSwtch_D_Stat3_UB 1;
BA_ "U_CX482_CX483_MY20_Gas_Rx" SG_ 1082 SelDrvMdeSwtch_D_Stat3_UB 1;
BA_ "U_CX482_CX483_MY20_Diesel_Rx" SG_ 1082 SelDrvMdeSwtch_D_Stat3_UB 1;
BA_ "U_U611_U625_MY20_Hev_Rx" SG_ 1082 SelDrvMdeSwtch_D_Stat3_UB 1;
BA_ "U_U611_U625_MY20_Gas_Rx" SG_ 1082 SelDrvMdeSwtch_D_Stat3_UB 1;
BA_ "U_U611_U625_MY20_Diesel_Rx" SG_ 1082 SelDrvMdeSwtch_D_Stat3_UB 1;
BA_ "U_C519_MY18_5_Gas_Rx" SG_ 1082 SelDrvMdeSwtch_D_Stat3_UB 1;
BA_ "U_C519_MY18_5_Diesel_Rx" SG_ 1082 SelDrvMdeSwtch_D_Stat3_UB 1;
BA_ "U_B479_MY17_Diesel_Rx" SG_ 1082 SelDrvMdeSwtch_D_Stat3_UB 1;
BA_ "U_B479_MY17_Gas_Rx" SG_ 1082 SelDrvMdeSwtch_D_Stat3_UB 1;
BA_ "U_CX482_CX483_MY20_Hev_Rx" SG_ 1082 FapLcStopHold_B_Rq 1;
BA_ "U_CX482_CX483_MY20_Gas_Rx" SG_ 1082 FapLcStopHold_B_Rq 1;
BA_ "U_CX482_CX483_MY20_Diesel_Rx" SG_ 1082 FapLcStopHold_B_Rq 1;
BA_ "U_B500_MY18_Diesel_Rx" SG_ 1082 FapLcStopHold_B_Rq 1;
BA_ "U_B500_MY18_Gas_Rx" SG_ 1082 FapLcStopHold_B_Rq 1;
BA_ "U_C519_MY18_5_Gas_Rx" SG_ 1082 FapLcStopHold_B_Rq 1;
BA_ "U_C519_MY18_5_Diesel_Rx" SG_ 1082 FapLcStopHold_B_Rq 1;
BA_ "GenSigSendType" SG_ 1082 FapLcStopHold_B_Rq 3;
BA_ "U_CX482_CX483_MY20_Hev_Rx" SG_ 1082 SelDrvMdeDsply_B_Avail 1;
BA_ "U_CX482_CX483_MY20_Gas_Rx" SG_ 1082 SelDrvMdeDsply_B_Avail 1;
BA_ "U_CX482_CX483_MY20_Diesel_Rx" SG_ 1082 SelDrvMdeDsply_B_Avail 1;
BA_ "U_U611_U625_MY20_Hev_Rx" SG_ 1082 SelDrvMdeDsply_B_Avail 1;
BA_ "U_U611_U625_MY20_Gas_Rx" SG_ 1082 SelDrvMdeDsply_B_Avail 1;
BA_ "U_U611_U625_MY20_Diesel_Rx" SG_ 1082 SelDrvMdeDsply_B_Avail 1;
BA_ "U_C519_MY18_5_Gas_Rx" SG_ 1082 SelDrvMdeDsply_B_Avail 1;
BA_ "U_C519_MY18_5_Diesel_Rx" SG_ 1082 SelDrvMdeDsply_B_Avail 1;
BA_ "GenSigSendType" SG_ 1082 SelDrvMdeDsply_B_Avail 3;
BA_ "U_CX482_CX483_MY20_Hev_Rx" SG_ 1082 FapLcPrchgBrk_B_Rq 1;
BA_ "U_CX482_CX483_MY20_Gas_Rx" SG_ 1082 FapLcPrchgBrk_B_Rq 1;
BA_ "U_CX482_CX483_MY20_Diesel_Rx" SG_ 1082 FapLcPrchgBrk_B_Rq 1;
BA_ "U_B500_MY18_Diesel_Rx" SG_ 1082 FapLcPrchgBrk_B_Rq 1;
BA_ "U_B500_MY18_Gas_Rx" SG_ 1082 FapLcPrchgBrk_B_Rq 1;
BA_ "U_C519_MY18_5_Gas_Rx" SG_ 1082 FapLcPrchgBrk_B_Rq 1;
BA_ "U_C519_MY18_5_Diesel_Rx" SG_ 1082 FapLcPrchgBrk_B_Rq 1;
BA_ "GenSigSendType" SG_ 1082 FapLcPrchgBrk_B_Rq 3;
BA_ "U_CX482_CX483_MY20_Hev_Rx" SG_ 1082 FapLcStopHold_B_Rq_UB 1;
BA_ "U_CX482_CX483_MY20_Gas_Rx" SG_ 1082 FapLcStopHold_B_Rq_UB 1;
BA_ "U_CX482_CX483_MY20_Diesel_Rx" SG_ 1082 FapLcStopHold_B_Rq_UB 1;
BA_ "U_B500_MY18_Diesel_Rx" SG_ 1082 FapLcStopHold_B_Rq_UB 1;
BA_ "U_B500_MY18_Gas_Rx" SG_ 1082 FapLcStopHold_B_Rq_UB 1;
BA_ "U_C519_MY18_5_Gas_Rx" SG_ 1082 FapLcStopHold_B_Rq_UB 1;
BA_ "U_C519_MY18_5_Diesel_Rx" SG_ 1082 FapLcStopHold_B_Rq_UB 1;
BA_ "U_CX482_CX483_MY20_Hev_Rx" SG_ 1082 FapLcPrchgBrk_B_Rq_UB 1;
BA_ "U_CX482_CX483_MY20_Gas_Rx" SG_ 1082 FapLcPrchgBrk_B_Rq_UB 1;
BA_ "U_CX482_CX483_MY20_Diesel_Rx" SG_ 1082 FapLcPrchgBrk_B_Rq_UB 1;
BA_ "U_B500_MY18_Diesel_Rx" SG_ 1082 FapLcPrchgBrk_B_Rq_UB 1;
BA_ "U_B500_MY18_Gas_Rx" SG_ 1082 FapLcPrchgBrk_B_Rq_UB 1;
BA_ "U_C519_MY18_5_Gas_Rx" SG_ 1082 FapLcPrchgBrk_B_Rq_UB 1;
BA_ "U_C519_MY18_5_Diesel_Rx" SG_ 1082 FapLcPrchgBrk_B_Rq_UB 1;
BA_ "U_B515_MCA_MY17_Gas_Rx" SG_ 1082 LnchCtl_N_Rq_UB 1;
BA_ "U_B515_MCA_MY17_Diesel_Rx" SG_ 1082 LnchCtl_N_Rq_UB 1;
BA_ "U_B515_MCA_MY17_Gas_Rx" SG_ 1082 LnchCtl_D_Rq_UB 1;
BA_ "U_B515_MCA_MY17_Diesel_Rx" SG_ 1082 LnchCtl_D_Rq_UB 1;
BA_ "U_B515_MCA_MY17_Gas_Rx" SG_ 1082 LnchCtl_N_Rq 1;
BA_ "U_B515_MCA_MY17_Diesel_Rx" SG_ 1082 LnchCtl_N_Rq 1;
BA_ "U_B515_MCA_MY17_Gas_Rx" SG_ 1082 LnchCtl_D_Rq 1;
BA_ "U_B515_MCA_MY17_Diesel_Rx" SG_ 1082 LnchCtl_D_Rq 1;
BA_ "GenSigSendType" SG_ 1082 LnchCtl_D_Rq 3;
BA_ "GenSigSendType" SG_ 1082 AirSusp_D_RqDrv 3;
BA_ "U_B515_MCA_MY17_Gas_Rx" SG_ 1082 AwdRnge_D_ActlIpc_UB 1;
BA_ "U_B515_MCA_MY17_Diesel_Rx" SG_ 1082 AwdRnge_D_ActlIpc_UB 1;
BA_ "U_B515_MCA_MY17_Gas_Rx" SG_ 1082 AwdRnge_D_ActlIpc 1;
BA_ "U_B515_MCA_MY17_Diesel_Rx" SG_ 1082 AwdRnge_D_ActlIpc 1;
BA_ "GenSigSendType" SG_ 1082 AwdRnge_D_ActlIpc 3;
BA_ "GenSigStartValue" SG_ 1082 AwdRnge_D_ActlIpc 7;
BA_ "CrossOver_InfoCAN" SG_ 1082 AwdRnge_D_ActlIpc 1;
BA_ "GenSigSendType" SG_ 1082 NtrlTowMdeEnbl_B_RqDrv 3;
BA_ "CrossOver_InfoCAN" SG_ 1082 NtrlTowMdeEnbl_B_RqDrv 1;
BA_ "U_CX482_CX483_MY20_Hev_Rx" SG_ 1082 DrvSlipCtlMde_B_RqMyKey_UB 1;
BA_ "U_CX482_CX483_MY20_Gas_Rx" SG_ 1082 DrvSlipCtlMde_B_RqMyKey_UB 1;
BA_ "U_CX482_CX483_MY20_Diesel_Rx" SG_ 1082 DrvSlipCtlMde_B_RqMyKey_UB 1;
BA_ "U_B500_MY18_Diesel_Rx" SG_ 1082 DrvSlipCtlMde_B_RqMyKey_UB 1;
BA_ "U_B500_MY18_Gas_Rx" SG_ 1082 DrvSlipCtlMde_B_RqMyKey_UB 1;
BA_ "U_B562_MY18_Gas_Rx" SG_ 1082 DrvSlipCtlMde_B_RqMyKey_UB 1;
BA_ "U_C519_MY18_5_Gas_Rx" SG_ 1082 DrvSlipCtlMde_B_RqMyKey_UB 1;
BA_ "U_C519_MY18_5_Diesel_Rx" SG_ 1082 DrvSlipCtlMde_B_RqMyKey_UB 1;
BA_ "U_B515_MCA_MY17_Gas_Rx" SG_ 1082 DrvSlipCtlMde_B_RqMyKey_UB 1;
BA_ "U_B515_MCA_MY17_Diesel_Rx" SG_ 1082 DrvSlipCtlMde_B_RqMyKey_UB 1;
BA_ "U_B479_MY17_Diesel_Rx" SG_ 1082 DrvSlipCtlMde_B_RqMyKey_UB 1;
BA_ "U_B479_MY17_Gas_Rx" SG_ 1082 DrvSlipCtlMde_B_RqMyKey_UB 1;
BA_ "U_CX482_CX483_MY20_Hev_Rx" SG_ 1082 DrvSlipCtlMde_B_RqMyKey 1;
BA_ "U_CX482_CX483_MY20_Gas_Rx" SG_ 1082 DrvSlipCtlMde_B_RqMyKey 1;
BA_ "U_CX482_CX483_MY20_Diesel_Rx" SG_ 1082 DrvSlipCtlMde_B_RqMyKey 1;
BA_ "U_U611_U625_MY20_Hev_Rx" SG_ 1082 DrvSlipCtlMde_B_RqMyKey 1;
BA_ "U_U611_U625_MY20_Gas_Rx" SG_ 1082 DrvSlipCtlMde_B_RqMyKey 1;
BA_ "U_U611_U625_MY20_Diesel_Rx" SG_ 1082 DrvSlipCtlMde_B_RqMyKey 1;
BA_ "U_B500_MY18_Diesel_Rx" SG_ 1082 DrvSlipCtlMde_B_RqMyKey 1;
BA_ "U_B500_MY18_Gas_Rx" SG_ 1082 DrvSlipCtlMde_B_RqMyKey 1;
BA_ "U_B562_MY18_Gas_Rx" SG_ 1082 DrvSlipCtlMde_B_RqMyKey 1;
BA_ "U_C519_MY18_5_Gas_Rx" SG_ 1082 DrvSlipCtlMde_B_RqMyKey 1;
BA_ "U_C519_MY18_5_Diesel_Rx" SG_ 1082 DrvSlipCtlMde_B_RqMyKey 1;
BA_ "U_B515_MCA_MY17_Gas_Rx" SG_ 1082 DrvSlipCtlMde_B_RqMyKey 1;
BA_ "U_B515_MCA_MY17_Diesel_Rx" SG_ 1082 DrvSlipCtlMde_B_RqMyKey 1;
BA_ "U_B479_MY17_Diesel_Rx" SG_ 1082 DrvSlipCtlMde_B_RqMyKey 1;
BA_ "U_B479_MY17_Gas_Rx" SG_ 1082 DrvSlipCtlMde_B_RqMyKey 1;
BA_ "GenSigSendType" SG_ 1082 DrvSlipCtlMde_B_RqMyKey 3;
BA_ "CrossOver_InfoCAN" SG_ 1082 DrvSlipCtlMde_B_RqMyKey 1;
BA_ "GenSigSendType" SG_ 1082 AwdDrvMde_D_Rq 3;
BA_ "U_CX482_CX483_MY20_Hev_Rx" SG_ 1082 MetricActv_B_Actl_UB 1;
BA_ "U_CX482_CX483_MY20_Gas_Rx" SG_ 1082 MetricActv_B_Actl_UB 1;
BA_ "U_CX482_CX483_MY20_Diesel_Rx" SG_ 1082 MetricActv_B_Actl_UB 1;
BA_ "U_U611_U625_MY20_Hev_Rx" SG_ 1082 MetricActv_B_Actl_UB 1;
BA_ "U_U611_U625_MY20_Gas_Rx" SG_ 1082 MetricActv_B_Actl_UB 1;
BA_ "U_U611_U625_MY20_Diesel_Rx" SG_ 1082 MetricActv_B_Actl_UB 1;
BA_ "U_C519_MY18_5_Gas_Rx" SG_ 1082 MetricActv_B_Actl_UB 1;
BA_ "U_C519_MY18_5_Diesel_Rx" SG_ 1082 MetricActv_B_Actl_UB 1;
BA_ "U_B479_MY17_Diesel_Rx" SG_ 1082 MetricActv_B_Actl_UB 1;
BA_ "U_B479_MY17_Gas_Rx" SG_ 1082 MetricActv_B_Actl_UB 1;
BA_ "U_CX482_CX483_MY20_Hev_Rx" SG_ 1082 MetricActv_B_Actl 1;
BA_ "U_CX482_CX483_MY20_Gas_Rx" SG_ 1082 MetricActv_B_Actl 1;
BA_ "U_CX482_CX483_MY20_Diesel_Rx" SG_ 1082 MetricActv_B_Actl 1;
BA_ "U_U611_U625_MY20_Hev_Rx" SG_ 1082 MetricActv_B_Actl 1;
BA_ "U_U611_U625_MY20_Gas_Rx" SG_ 1082 MetricActv_B_Actl 1;
BA_ "U_U611_U625_MY20_Diesel_Rx" SG_ 1082 MetricActv_B_Actl 1;
BA_ "U_C519_MY18_5_Gas_Rx" SG_ 1082 MetricActv_B_Actl 1;
BA_ "U_C519_MY18_5_Diesel_Rx" SG_ 1082 MetricActv_B_Actl 1;
BA_ "U_B479_MY17_Diesel_Rx" SG_ 1082 MetricActv_B_Actl 1;
BA_ "U_B479_MY17_Gas_Rx" SG_ 1082 MetricActv_B_Actl 1;
BA_ "GenSigSendType" SG_ 1082 MetricActv_B_Actl 3;
BA_ "CrossOver_InfoCAN" SG_ 1082 MetricActv_B_Actl 1;
BA_ "GenSigSendType" SG_ 1082 CamraFrntBttn_D_Stat2 3;
BA_ "U_B515_MCA_MY17_Gas_Rx" SG_ 1082 BrkLineLck_D_Rq_UB 1;
BA_ "U_B515_MCA_MY17_Diesel_Rx" SG_ 1082 BrkLineLck_D_Rq_UB 1;
BA_ "U_B479_MY17_Diesel_Rx" SG_ 1082 BrkLineLck_D_Rq_UB 1;
BA_ "U_B479_MY17_Gas_Rx" SG_ 1082 BrkLineLck_D_Rq_UB 1;
BA_ "U_B515_MCA_MY17_Gas_Rx" SG_ 1082 BrkLineLck_D_Rq 1;
BA_ "U_B515_MCA_MY17_Diesel_Rx" SG_ 1082 BrkLineLck_D_Rq 1;
BA_ "U_B479_MY17_Diesel_Rx" SG_ 1082 BrkLineLck_D_Rq 1;
BA_ "U_B479_MY17_Gas_Rx" SG_ 1082 BrkLineLck_D_Rq 1;
BA_ "GenSigSendType" SG_ 1082 BrkLineLck_D_Rq 3;
BA_ "GenSigSendType" SG_ 1082 SuspDrvMde_D_Rq 3;
BA_ "U_CX482_CX483_MY20_Hev_Rx" SG_ 1082 SelDrvMdePt_D_Stat_UB 1;
BA_ "U_CX482_CX483_MY20_Gas_Rx" SG_ 1082 SelDrvMdePt_D_Stat_UB 1;
BA_ "U_CX482_CX483_MY20_Diesel_Rx" SG_ 1082 SelDrvMdePt_D_Stat_UB 1;
BA_ "U_B500_MY18_Diesel_Rx" SG_ 1082 SelDrvMdePt_D_Stat_UB 1;
BA_ "U_B500_MY18_Gas_Rx" SG_ 1082 SelDrvMdePt_D_Stat_UB 1;
BA_ "U_C519_MY18_5_Gas_Rx" SG_ 1082 SelDrvMdePt_D_Stat_UB 1;
BA_ "U_C519_MY18_5_Diesel_Rx" SG_ 1082 SelDrvMdePt_D_Stat_UB 1;
BA_ "U_B479_MY17_Diesel_Rx" SG_ 1082 SelDrvMdePt_D_Stat_UB 1;
BA_ "U_B479_MY17_Gas_Rx" SG_ 1082 SelDrvMdePt_D_Stat_UB 1;
BA_ "U_CX482_CX483_MY20_Hev_Rx" SG_ 1082 SelDrvMdePt_D_Stat 1;
BA_ "U_CX482_CX483_MY20_Gas_Rx" SG_ 1082 SelDrvMdePt_D_Stat 1;
BA_ "U_CX482_CX483_MY20_Diesel_Rx" SG_ 1082 SelDrvMdePt_D_Stat 1;
BA_ "U_U611_U625_MY20_Hev_Rx" SG_ 1082 SelDrvMdePt_D_Stat 1;
BA_ "U_U611_U625_MY20_Gas_Rx" SG_ 1082 SelDrvMdePt_D_Stat 1;
BA_ "U_U611_U625_MY20_Diesel_Rx" SG_ 1082 SelDrvMdePt_D_Stat 1;
BA_ "U_B500_MY18_Diesel_Rx" SG_ 1082 SelDrvMdePt_D_Stat 1;
BA_ "U_B500_MY18_Gas_Rx" SG_ 1082 SelDrvMdePt_D_Stat 1;
BA_ "U_C519_MY18_5_Gas_Rx" SG_ 1082 SelDrvMdePt_D_Stat 1;
BA_ "U_C519_MY18_5_Diesel_Rx" SG_ 1082 SelDrvMdePt_D_Stat 1;
BA_ "U_B479_MY17_Diesel_Rx" SG_ 1082 SelDrvMdePt_D_Stat 1;
BA_ "U_B479_MY17_Gas_Rx" SG_ 1082 SelDrvMdePt_D_Stat 1;
BA_ "GenSigSendType" SG_ 1082 SelDrvMdePt_D_Stat 3;
BA_ "U_B515_MCA_MY17_Gas_Rx" SG_ 609 AwdLck_Tq_Rq 1;
BA_ "U_B515_MCA_MY17_Diesel_Rx" SG_ 609 AwdLck_Tq_Rq 1;
BA_ "ContentDependant" SG_ 609 AwdLck_Tq_Rq 1;
BA_ "CrossOver_InfoCAN" SG_ 609 AwdLck_Tq_Rq 1;
BA_ "U_U611_U625_MY20_Hev_Rx" SG_ 609 AwdLck_Tq_Actl 1;
BA_ "U_U611_U625_MY20_Gas_Rx" SG_ 609 AwdLck_Tq_Actl 1;
BA_ "U_U611_U625_MY20_Diesel_Rx" SG_ 609 AwdLck_Tq_Actl 1;
BA_ "U_B515_MCA_MY17_Gas_Rx" SG_ 609 AwdLck_Tq_Actl 1;
BA_ "U_B515_MCA_MY17_Diesel_Rx" SG_ 609 AwdLck_Tq_Actl 1;
BA_ "CrossOver_InfoCAN" SG_ 609 AwdLck_Tq_Actl 1;
BA_ "GenSigSendType" SG_ 609 AwdTerrMdeChng_D_Rdy 3;
BA_ "CrossOver_InfoCAN" SG_ 609 AwdTerrMdeChng_D_Rdy 1;
BA_ "GenSigSendType" SG_ 609 AwdTerrMde_D_Actl 3;
BA_ "CrossOver_InfoCAN" SG_ 609 AwdTerrMde_D_Actl 1;
BA_ "U_U611_U625_MY20_Hev_Rx" SG_ 609 AwdStat_D_RqDsply 1;
BA_ "U_U611_U625_MY20_Gas_Rx" SG_ 609 AwdStat_D_RqDsply 1;
BA_ "U_U611_U625_MY20_Diesel_Rx" SG_ 609 AwdStat_D_RqDsply 1;
BA_ "GenSigSendType" SG_ 609 AwdStat_D_RqDsply 3;
BA_ "ContentDependant" SG_ 609 AwdStat_D_RqDsply 1;
BA_ "CrossOver_InfoCAN" SG_ 609 AwdStat_D_RqDsply 1;
BA_ "U_U611_U625_MY20_Hev_Rx" SG_ 609 AwdLck_D_Stat 1;
BA_ "U_U611_U625_MY20_Gas_Rx" SG_ 609 AwdLck_D_Stat 1;
BA_ "U_U611_U625_MY20_Diesel_Rx" SG_ 609 AwdLck_D_Stat 1;
BA_ "U_B515_MCA_MY17_Gas_Rx" SG_ 609 AwdLck_D_Stat 1;
BA_ "U_B515_MCA_MY17_Diesel_Rx" SG_ 609 AwdLck_D_Stat 1;
BA_ "GenSigSendType" SG_ 609 AwdLck_D_Stat 3;
BA_ "CrossOver_InfoCAN" SG_ 609 AwdLck_D_Stat 1;
BA_ "U_U611_U625_MY20_Hev_Rx" SG_ 609 AwdSrvcRqd_B_Rq 1;
BA_ "U_U611_U625_MY20_Gas_Rx" SG_ 609 AwdSrvcRqd_B_Rq 1;
BA_ "U_U611_U625_MY20_Diesel_Rx" SG_ 609 AwdSrvcRqd_B_Rq 1;
BA_ "U_B515_MCA_MY17_Gas_Rx" SG_ 609 AwdSrvcRqd_B_Rq 1;
BA_ "U_B515_MCA_MY17_Diesel_Rx" SG_ 609 AwdSrvcRqd_B_Rq 1;
BA_ "GenSigSendType" SG_ 609 AwdSrvcRqd_B_Rq 3;
BA_ "ContentDependant" SG_ 609 AwdSrvcRqd_B_Rq 1;
BA_ "CrossOver_InfoCAN" SG_ 609 AwdSrvcRqd_B_Rq 1;
BA_ "U_U611_U625_MY20_Phev_Tx" SG_ 1462 GSM_GWOnBoardTester 1;
BA_ "U_U611_U625_MY20_Hev_Tx" SG_ 1462 GSM_GWOnBoardTester 1;
BA_ "U_U611_U625_MY20_Gas_Tx" SG_ 1462 GSM_GWOnBoardTester 1;
BA_ "U_U611_U625_MY20_Diesel_Tx" SG_ 1462 GSM_GWOnBoardTester 1;
BA_ "U_C519_MY18_5_Gas_Tx" SG_ 1462 GSM_GWOnBoardTester 1;
BA_ "U_C519_MY18_5_Diesel_Tx" SG_ 1462 GSM_GWOnBoardTester 1;
BA_ "ContentDependant" SG_ 1462 GSM_GWOnBoardTester 1;
BA_ "GenSigStartValue" SG_ 1462 GSM_GWOnBoardTester 255;
BA_ "U_U611_U625_MY20_Phev_Tx" SG_ 1462 GSM_GWNMProxy 1;
BA_ "U_U611_U625_MY20_Hev_Tx" SG_ 1462 GSM_GWNMProxy 1;
BA_ "U_U611_U625_MY20_Gas_Tx" SG_ 1462 GSM_GWNMProxy 1;
BA_ "U_U611_U625_MY20_Diesel_Tx" SG_ 1462 GSM_GWNMProxy 1;
BA_ "U_C519_MY18_5_Gas_Tx" SG_ 1462 GSM_GWNMProxy 1;
BA_ "U_C519_MY18_5_Diesel_Tx" SG_ 1462 GSM_GWNMProxy 1;
BA_ "ContentDependant" SG_ 1462 GSM_GWNMProxy 1;
BA_ "GenSigStartValue" SG_ 1462 GSM_GWNMProxy 255;
BA_ "U_U611_U625_MY20_Phev_Tx" SG_ 1462 GSM_AutoSarNMReserved4 1;
BA_ "U_U611_U625_MY20_Hev_Tx" SG_ 1462 GSM_AutoSarNMReserved4 1;
BA_ "U_U611_U625_MY20_Gas_Tx" SG_ 1462 GSM_AutoSarNMReserved4 1;
BA_ "U_U611_U625_MY20_Diesel_Tx" SG_ 1462 GSM_AutoSarNMReserved4 1;
BA_ "U_C519_MY18_5_Gas_Tx" SG_ 1462 GSM_AutoSarNMReserved4 1;
BA_ "U_C519_MY18_5_Diesel_Tx" SG_ 1462 GSM_AutoSarNMReserved4 1;
BA_ "ContentDependant" SG_ 1462 GSM_AutoSarNMReserved4 1;
BA_ "GenSigStartValue" SG_ 1462 GSM_AutoSarNMReserved4 255;
BA_ "U_U611_U625_MY20_Phev_Tx" SG_ 1462 GSM_AutoSarNMReserved3 1;
BA_ "U_U611_U625_MY20_Hev_Tx" SG_ 1462 GSM_AutoSarNMReserved3 1;
BA_ "U_U611_U625_MY20_Gas_Tx" SG_ 1462 GSM_AutoSarNMReserved3 1;
BA_ "U_U611_U625_MY20_Diesel_Tx" SG_ 1462 GSM_AutoSarNMReserved3 1;
BA_ "U_C519_MY18_5_Gas_Tx" SG_ 1462 GSM_AutoSarNMReserved3 1;
BA_ "U_C519_MY18_5_Diesel_Tx" SG_ 1462 GSM_AutoSarNMReserved3 1;
BA_ "ContentDependant" SG_ 1462 GSM_AutoSarNMReserved3 1;
BA_ "GenSigStartValue" SG_ 1462 GSM_AutoSarNMReserved3 255;
BA_ "U_U611_U625_MY20_Phev_Tx" SG_ 1462 GSM_AutoSarNMReserved2 1;
BA_ "U_U611_U625_MY20_Hev_Tx" SG_ 1462 GSM_AutoSarNMReserved2 1;
BA_ "U_U611_U625_MY20_Gas_Tx" SG_ 1462 GSM_AutoSarNMReserved2 1;
BA_ "U_U611_U625_MY20_Diesel_Tx" SG_ 1462 GSM_AutoSarNMReserved2 1;
BA_ "U_C519_MY18_5_Gas_Tx" SG_ 1462 GSM_AutoSarNMReserved2 1;
BA_ "U_C519_MY18_5_Diesel_Tx" SG_ 1462 GSM_AutoSarNMReserved2 1;
BA_ "ContentDependant" SG_ 1462 GSM_AutoSarNMReserved2 1;
BA_ "GenSigStartValue" SG_ 1462 GSM_AutoSarNMReserved2 255;
BA_ "U_U611_U625_MY20_Phev_Tx" SG_ 1462 GSM_AutoSarNMReserved1 1;
BA_ "U_U611_U625_MY20_Hev_Tx" SG_ 1462 GSM_AutoSarNMReserved1 1;
BA_ "U_U611_U625_MY20_Gas_Tx" SG_ 1462 GSM_AutoSarNMReserved1 1;
BA_ "U_U611_U625_MY20_Diesel_Tx" SG_ 1462 GSM_AutoSarNMReserved1 1;
BA_ "U_C519_MY18_5_Gas_Tx" SG_ 1462 GSM_AutoSarNMReserved1 1;
BA_ "U_C519_MY18_5_Diesel_Tx" SG_ 1462 GSM_AutoSarNMReserved1 1;
BA_ "ContentDependant" SG_ 1462 GSM_AutoSarNMReserved1 1;
BA_ "GenSigStartValue" SG_ 1462 GSM_AutoSarNMReserved1 255;
BA_ "U_U611_U625_MY20_Phev_Tx" SG_ 1462 GSM_AutoSarNMNodeId 1;
BA_ "U_U611_U625_MY20_Hev_Tx" SG_ 1462 GSM_AutoSarNMNodeId 1;
BA_ "U_U611_U625_MY20_Gas_Tx" SG_ 1462 GSM_AutoSarNMNodeId 1;
BA_ "U_U611_U625_MY20_Diesel_Tx" SG_ 1462 GSM_AutoSarNMNodeId 1;
BA_ "U_C519_MY18_5_Gas_Tx" SG_ 1462 GSM_AutoSarNMNodeId 1;
BA_ "U_C519_MY18_5_Diesel_Tx" SG_ 1462 GSM_AutoSarNMNodeId 1;
BA_ "ContentDependant" SG_ 1462 GSM_AutoSarNMNodeId 1;
BA_ "GenSigStartValue" SG_ 1462 GSM_AutoSarNMNodeId 182;
BA_ "U_U611_U625_MY20_Phev_Tx" SG_ 1462 GSM_AutoSarNMControl 1;
BA_ "U_U611_U625_MY20_Hev_Tx" SG_ 1462 GSM_AutoSarNMControl 1;
BA_ "U_U611_U625_MY20_Gas_Tx" SG_ 1462 GSM_AutoSarNMControl 1;
BA_ "U_U611_U625_MY20_Diesel_Tx" SG_ 1462 GSM_AutoSarNMControl 1;
BA_ "U_C519_MY18_5_Gas_Tx" SG_ 1462 GSM_AutoSarNMControl 1;
BA_ "U_C519_MY18_5_Diesel_Tx" SG_ 1462 GSM_AutoSarNMControl 1;
BA_ "ContentDependant" SG_ 1462 GSM_AutoSarNMControl 1;
BA_ "U_C519_MY18_5_Gas_Tx" SG_ 92 TrnLvrV_D_Rq 1;
BA_ "U_C519_MY18_5_Diesel_Tx" SG_ 92 TrnLvrV_D_Rq 1;
BA_ "GenSigStartValue" SG_ 92 TrnLvrV_D_Rq 1;
BA_ "U_U611_U625_MY20_Phev_Rx" SG_ 92 TrnSbwSysHlth_D_Actl 1;
BA_ "U_U611_U625_MY20_Hev_Rx" SG_ 92 TrnSbwSysHlth_D_Actl 1;
BA_ "U_U611_U625_MY20_Gas_Rx" SG_ 92 TrnSbwSysHlth_D_Actl 1;
BA_ "U_U611_U625_MY20_Diesel_Rx" SG_ 92 TrnSbwSysHlth_D_Actl 1;
BA_ "ContentDependant" SG_ 92 TrnSbwSysHlth_D_Actl 1;
BA_ "GenSigStartValue" SG_ 92 TrnSbwSysHlth_D_Actl 1;
BA_ "U_C519_MY18_5_Gas_Tx" SG_ 92 TrnDtpCmd_D_Actl 1;
BA_ "U_C519_MY18_5_Diesel_Tx" SG_ 92 TrnDtpCmd_D_Actl 1;
BA_ "U_U611_U625_MY20_Phev_Rx" SG_ 92 TrnDtpCmd_D_Actl 1;
BA_ "U_CX482_CX483_MY20_Hev_Rx" SG_ 92 TrnDtpCmd_D_Actl 1;
BA_ "U_CX482_CX483_MY20_Gas_Rx" SG_ 92 TrnDtpCmd_D_Actl 1;
BA_ "U_CX482_CX483_MY20_Diesel_Rx" SG_ 92 TrnDtpCmd_D_Actl 1;
BA_ "U_U611_U625_MY20_Hev_Rx" SG_ 92 TrnDtpCmd_D_Actl 1;
BA_ "U_U611_U625_MY20_Gas_Rx" SG_ 92 TrnDtpCmd_D_Actl 1;
BA_ "U_U611_U625_MY20_Diesel_Rx" SG_ 92 TrnDtpCmd_D_Actl 1;
BA_ "U_C519_MY18_5_Gas_Rx" SG_ 92 TrnDtpCmd_D_Actl 1;
BA_ "U_C519_MY18_5_Diesel_Rx" SG_ 92 TrnDtpCmd_D_Actl 1;
BA_ "ContentDependant" SG_ 92 TrnDtpCmd_D_Actl 1;
BA_ "GenSigStartValue" SG_ 92 TrnDtpCmd_D_Actl 1;
BA_ "WakeupSignal" SG_ 92 TrnDtpCmd_D_Actl 1;
BA_ "U_C519_MY18_5_Gas_Tx" SG_ 92 TrnGearNtmAllow_B_Stat 1;
BA_ "U_C519_MY18_5_Diesel_Tx" SG_ 92 TrnGearNtmAllow_B_Stat 1;
BA_ "ContentDependant" SG_ 92 TrnGearNtmAllow_B_Stat 1;
BA_ "CrossOver_InfoCAN" SG_ 92 TrnGearNtmAllow_B_Stat 1;
BA_ "U_U611_U625_MY20_Phev_Rx" SG_ 92 GearSelLck_D_Rq 1;
BA_ "U_CX482_CX483_MY20_Hev_Rx" SG_ 92 GearSelLck_D_Rq 1;
BA_ "U_CX482_CX483_MY20_Gas_Rx" SG_ 92 GearSelLck_D_Rq 1;
BA_ "U_CX482_CX483_MY20_Diesel_Rx" SG_ 92 GearSelLck_D_Rq 1;
BA_ "U_U611_U625_MY20_Hev_Rx" SG_ 92 GearSelLck_D_Rq 1;
BA_ "U_U611_U625_MY20_Gas_Rx" SG_ 92 GearSelLck_D_Rq 1;
BA_ "U_U611_U625_MY20_Diesel_Rx" SG_ 92 GearSelLck_D_Rq 1;
BA_ "U_C519_MY18_5_Gas_Rx" SG_ 92 GearSelLck_D_Rq 1;
BA_ "U_C519_MY18_5_Diesel_Rx" SG_ 92 GearSelLck_D_Rq 1;
BA_ "U_C519_MY18_5_Gas_Tx" SG_ 92 TrnGearCmd_No_Cs 1;
BA_ "U_C519_MY18_5_Diesel_Tx" SG_ 92 TrnGearCmd_No_Cs 1;
BA_ "U_U611_U625_MY20_Phev_Rx" SG_ 92 TrnGearCmd_No_Cs 1;
BA_ "U_CX482_CX483_MY20_Hev_Rx" SG_ 92 TrnGearCmd_No_Cs 1;
BA_ "U_CX482_CX483_MY20_Gas_Rx" SG_ 92 TrnGearCmd_No_Cs 1;
BA_ "U_CX482_CX483_MY20_Diesel_Rx" SG_ 92 TrnGearCmd_No_Cs 1;
BA_ "U_U611_U625_MY20_Hev_Rx" SG_ 92 TrnGearCmd_No_Cs 1;
BA_ "U_U611_U625_MY20_Gas_Rx" SG_ 92 TrnGearCmd_No_Cs 1;
BA_ "U_U611_U625_MY20_Diesel_Rx" SG_ 92 TrnGearCmd_No_Cs 1;
BA_ "U_C519_MY18_5_Gas_Rx" SG_ 92 TrnGearCmd_No_Cs 1;
BA_ "U_C519_MY18_5_Diesel_Rx" SG_ 92 TrnGearCmd_No_Cs 1;
BA_ "ContentDependant" SG_ 92 TrnGearCmd_No_Cs 1;
BA_ "U_C519_MY18_5_Gas_Tx" SG_ 92 TrnValidGear_D_Cnfm 1;
BA_ "U_C519_MY18_5_Diesel_Tx" SG_ 92 TrnValidGear_D_Cnfm 1;
BA_ "U_U611_U625_MY20_Phev_Rx" SG_ 92 TrnValidGear_D_Cnfm 1;
BA_ "U_CX482_CX483_MY20_Hev_Rx" SG_ 92 TrnValidGear_D_Cnfm 1;
BA_ "U_CX482_CX483_MY20_Gas_Rx" SG_ 92 TrnValidGear_D_Cnfm 1;
BA_ "U_CX482_CX483_MY20_Diesel_Rx" SG_ 92 TrnValidGear_D_Cnfm 1;
BA_ "U_U611_U625_MY20_Hev_Rx" SG_ 92 TrnValidGear_D_Cnfm 1;
BA_ "U_U611_U625_MY20_Gas_Rx" SG_ 92 TrnValidGear_D_Cnfm 1;
BA_ "U_U611_U625_MY20_Diesel_Rx" SG_ 92 TrnValidGear_D_Cnfm 1;
BA_ "U_C519_MY18_5_Gas_Rx" SG_ 92 TrnValidGear_D_Cnfm 1;
BA_ "U_C519_MY18_5_Diesel_Rx" SG_ 92 TrnValidGear_D_Cnfm 1;
BA_ "ContentDependant" SG_ 92 TrnValidGear_D_Cnfm 1;
BA_ "U_C519_MY18_5_Gas_Tx" SG_ 92 TrnNtrlTowCmd_D_Actl 1;
BA_ "U_C519_MY18_5_Diesel_Tx" SG_ 92 TrnNtrlTowCmd_D_Actl 1;
BA_ "U_U611_U625_MY20_Phev_Rx" SG_ 92 TrnNtrlTowCmd_D_Actl 1;
BA_ "U_CX482_CX483_MY20_Hev_Rx" SG_ 92 TrnNtrlTowCmd_D_Actl 1;
BA_ "U_CX482_CX483_MY20_Gas_Rx" SG_ 92 TrnNtrlTowCmd_D_Actl 1;
BA_ "U_CX482_CX483_MY20_Diesel_Rx" SG_ 92 TrnNtrlTowCmd_D_Actl 1;
BA_ "U_U611_U625_MY20_Hev_Rx" SG_ 92 TrnNtrlTowCmd_D_Actl 1;
BA_ "U_U611_U625_MY20_Gas_Rx" SG_ 92 TrnNtrlTowCmd_D_Actl 1;
BA_ "U_U611_U625_MY20_Diesel_Rx" SG_ 92 TrnNtrlTowCmd_D_Actl 1;
BA_ "U_C519_MY18_5_Gas_Rx" SG_ 92 TrnNtrlTowCmd_D_Actl 1;
BA_ "U_C519_MY18_5_Diesel_Rx" SG_ 92 TrnNtrlTowCmd_D_Actl 1;
BA_ "ContentDependant" SG_ 92 TrnNtrlTowCmd_D_Actl 1;
BA_ "U_C519_MY18_5_Gas_Tx" SG_ 92 TrnGearCmd_Pc_ActlPt 1;
BA_ "U_C519_MY18_5_Diesel_Tx" SG_ 92 TrnGearCmd_Pc_ActlPt 1;
BA_ "U_U611_U625_MY20_Phev_Rx" SG_ 92 TrnGearCmd_Pc_ActlPt 1;
BA_ "U_CX482_CX483_MY20_Hev_Rx" SG_ 92 TrnGearCmd_Pc_ActlPt 1;
BA_ "U_CX482_CX483_MY20_Gas_Rx" SG_ 92 TrnGearCmd_Pc_ActlPt 1;
BA_ "U_CX482_CX483_MY20_Diesel_Rx" SG_ 92 TrnGearCmd_Pc_ActlPt 1;
BA_ "U_U611_U625_MY20_Hev_Rx" SG_ 92 TrnGearCmd_Pc_ActlPt 1;
BA_ "U_U611_U625_MY20_Gas_Rx" SG_ 92 TrnGearCmd_Pc_ActlPt 1;
BA_ "U_U611_U625_MY20_Diesel_Rx" SG_ 92 TrnGearCmd_Pc_ActlPt 1;
BA_ "U_C519_MY18_5_Gas_Rx" SG_ 92 TrnGearCmd_Pc_ActlPt 1;
BA_ "U_C519_MY18_5_Diesel_Rx" SG_ 92 TrnGearCmd_Pc_ActlPt 1;
BA_ "ContentDependant" SG_ 92 TrnGearCmd_Pc_ActlPt 1;
BA_ "U_C519_MY18_5_Gas_Tx" SG_ 92 TrnGear_D_RqPt 1;
BA_ "U_C519_MY18_5_Diesel_Tx" SG_ 92 TrnGear_D_RqPt 1;
BA_ "U_U611_U625_MY20_Phev_Rx" SG_ 92 TrnGear_D_RqPt 1;
BA_ "U_CX482_CX483_MY20_Hev_Rx" SG_ 92 TrnGear_D_RqPt 1;
BA_ "U_CX482_CX483_MY20_Gas_Rx" SG_ 92 TrnGear_D_RqPt 1;
BA_ "U_CX482_CX483_MY20_Diesel_Rx" SG_ 92 TrnGear_D_RqPt 1;
BA_ "U_U611_U625_MY20_Hev_Rx" SG_ 92 TrnGear_D_RqPt 1;
BA_ "U_U611_U625_MY20_Gas_Rx" SG_ 92 TrnGear_D_RqPt 1;
BA_ "U_U611_U625_MY20_Diesel_Rx" SG_ 92 TrnGear_D_RqPt 1;
BA_ "U_C519_MY18_5_Gas_Rx" SG_ 92 TrnGear_D_RqPt 1;
BA_ "U_C519_MY18_5_Diesel_Rx" SG_ 92 TrnGear_D_RqPt 1;
BA_ "ContentDependant" SG_ 92 TrnGear_D_RqPt 1;
BA_ "U_C519_MY18_5_Gas_Tx" SG_ 92 TrnCmdState_B_Actl 1;
BA_ "U_C519_MY18_5_Diesel_Tx" SG_ 92 TrnCmdState_B_Actl 1;
BA_ "U_U611_U625_MY20_Phev_Rx" SG_ 92 TrnCmdState_B_Actl 1;
BA_ "U_CX482_CX483_MY20_Hev_Rx" SG_ 92 TrnCmdState_B_Actl 1;
BA_ "U_CX482_CX483_MY20_Gas_Rx" SG_ 92 TrnCmdState_B_Actl 1;
BA_ "U_CX482_CX483_MY20_Diesel_Rx" SG_ 92 TrnCmdState_B_Actl 1;
BA_ "U_U611_U625_MY20_Hev_Rx" SG_ 92 TrnCmdState_B_Actl 1;
BA_ "U_U611_U625_MY20_Gas_Rx" SG_ 92 TrnCmdState_B_Actl 1;
BA_ "U_U611_U625_MY20_Diesel_Rx" SG_ 92 TrnCmdState_B_Actl 1;
BA_ "U_C519_MY18_5_Gas_Rx" SG_ 92 TrnCmdState_B_Actl 1;
BA_ "U_C519_MY18_5_Diesel_Rx" SG_ 92 TrnCmdState_B_Actl 1;
BA_ "ContentDependant" SG_ 92 TrnCmdState_B_Actl 1;
BA_ "U_C519_MY18_5_Gas_Tx" SG_ 92 TrnCmdCnt_B_Actl 1;
BA_ "U_C519_MY18_5_Diesel_Tx" SG_ 92 TrnCmdCnt_B_Actl 1;
BA_ "U_U611_U625_MY20_Phev_Rx" SG_ 92 TrnCmdCnt_B_Actl 1;
BA_ "U_CX482_CX483_MY20_Hev_Rx" SG_ 92 TrnCmdCnt_B_Actl 1;
BA_ "U_CX482_CX483_MY20_Gas_Rx" SG_ 92 TrnCmdCnt_B_Actl 1;
BA_ "U_CX482_CX483_MY20_Diesel_Rx" SG_ 92 TrnCmdCnt_B_Actl 1;
BA_ "U_U611_U625_MY20_Hev_Rx" SG_ 92 TrnCmdCnt_B_Actl 1;
BA_ "U_U611_U625_MY20_Gas_Rx" SG_ 92 TrnCmdCnt_B_Actl 1;
BA_ "U_U611_U625_MY20_Diesel_Rx" SG_ 92 TrnCmdCnt_B_Actl 1;
BA_ "U_C519_MY18_5_Gas_Rx" SG_ 92 TrnCmdCnt_B_Actl 1;
BA_ "U_C519_MY18_5_Diesel_Rx" SG_ 92 TrnCmdCnt_B_Actl 1;
BA_ "ContentDependant" SG_ 92 TrnCmdCnt_B_Actl 1;
BA_ "U_C519_MY18_5_Gas_Tx" SG_ 92 PrkBrkActv_D_RqTrnGear 1;
BA_ "U_C519_MY18_5_Diesel_Tx" SG_ 92 PrkBrkActv_D_RqTrnGear 1;
BA_ "U_U611_U625_MY20_Phev_Rx" SG_ 92 PrkBrkActv_D_RqTrnGear 1;
BA_ "U_CX482_CX483_MY20_Hev_Rx" SG_ 92 PrkBrkActv_D_RqTrnGear 1;
BA_ "U_CX482_CX483_MY20_Gas_Rx" SG_ 92 PrkBrkActv_D_RqTrnGear 1;
BA_ "U_CX482_CX483_MY20_Diesel_Rx" SG_ 92 PrkBrkActv_D_RqTrnGear 1;
BA_ "U_U611_U625_MY20_Hev_Rx" SG_ 92 PrkBrkActv_D_RqTrnGear 1;
BA_ "U_U611_U625_MY20_Gas_Rx" SG_ 92 PrkBrkActv_D_RqTrnGear 1;
BA_ "U_U611_U625_MY20_Diesel_Rx" SG_ 92 PrkBrkActv_D_RqTrnGear 1;
BA_ "U_C519_MY18_5_Gas_Rx" SG_ 92 PrkBrkActv_D_RqTrnGear 1;
BA_ "U_C519_MY18_5_Diesel_Rx" SG_ 92 PrkBrkActv_D_RqTrnGear 1;
BA_ "ContentDependant" SG_ 92 PrkBrkActv_D_RqTrnGear 1;
BA_ "GenSigStartValue" SG_ 92 PrkBrkActv_D_RqTrnGear 1;
BA_ "U_C519_MY18_5_Gas_Tx" SG_ 92 TrnGearMsgTxt_D_Rq 1;
BA_ "U_C519_MY18_5_Diesel_Tx" SG_ 92 TrnGearMsgTxt_D_Rq 1;
BA_ "ContentDependant" SG_ 92 TrnGearMsgTxt_D_Rq 1;
BA_ "CrossOver_InfoCAN" SG_ 92 TrnGearMsgTxt_D_Rq 1;
BA_ "U_C519_MY18_5_Gas_Tx" SG_ 92 TrnGearCmd_No_Cnt 1;
BA_ "U_C519_MY18_5_Diesel_Tx" SG_ 92 TrnGearCmd_No_Cnt 1;
BA_ "U_U611_U625_MY20_Phev_Rx" SG_ 92 TrnGearCmd_No_Cnt 1;
BA_ "U_CX482_CX483_MY20_Hev_Rx" SG_ 92 TrnGearCmd_No_Cnt 1;
BA_ "U_CX482_CX483_MY20_Gas_Rx" SG_ 92 TrnGearCmd_No_Cnt 1;
BA_ "U_CX482_CX483_MY20_Diesel_Rx" SG_ 92 TrnGearCmd_No_Cnt 1;
BA_ "U_U611_U625_MY20_Hev_Rx" SG_ 92 TrnGearCmd_No_Cnt 1;
BA_ "U_U611_U625_MY20_Gas_Rx" SG_ 92 TrnGearCmd_No_Cnt 1;
BA_ "U_U611_U625_MY20_Diesel_Rx" SG_ 92 TrnGearCmd_No_Cnt 1;
BA_ "U_C519_MY18_5_Gas_Rx" SG_ 92 TrnGearCmd_No_Cnt 1;
BA_ "U_C519_MY18_5_Diesel_Rx" SG_ 92 TrnGearCmd_No_Cnt 1;
BA_ "ContentDependant" SG_ 92 TrnGearCmd_No_Cnt 1;
BA_ "ContentDependant" SG_ 361 TrcmSrvcRqd_B_Rq 1;
BA_ "CrossOver_InfoCAN" SG_ 361 TrcmSrvcRqd_B_Rq 1;
BA_ "ContentDependant" SG_ 361 TrnGear_I_MeasMax 1;
BA_ "CrossOver_InfoCAN" SG_ 361 TrnGear_I_MeasMax 1;
BA_ "ContentDependant" SG_ 361 TrnActFalt_B_Actl 1;
BA_ "CrossOver_InfoCAN" SG_ 361 TrnActFalt_B_Actl 1;
BA_ "ContentDependant" SG_ 361 TrnCapHlth_Actl 1;
BA_ "CrossOver_InfoCAN" SG_ 361 TrnCapHlth_Actl 1;
BA_ "ContentDependant" SG_ 361 TrnPwmFalt_B_Actl 1;
BA_ "CrossOver_InfoCAN" SG_ 361 TrnPwmFalt_B_Actl 1;
BA_ "U_U611_U625_MY20_Phev_Rx" SG_ 93 TrnTrcmNtmState_D_Actl 1;
BA_ "U_U611_U625_MY20_Hev_Rx" SG_ 93 TrnTrcmNtmState_D_Actl 1;
BA_ "U_U611_U625_MY20_Gas_Rx" SG_ 93 TrnTrcmNtmState_D_Actl 1;
BA_ "U_U611_U625_MY20_Diesel_Rx" SG_ 93 TrnTrcmNtmState_D_Actl 1;
BA_ "GenSigSendType" SG_ 93 TrnTrcmNtmState_D_Actl 3;
BA_ "ContentDependant" SG_ 93 TrnTrcmNtmState_D_Actl 1;
BA_ "CrossOver_InfoCAN" SG_ 93 TrnTrcmNtmState_D_Actl 1;
BA_ "U_U611_U625_MY20_Phev_Rx" SG_ 93 TrnSns2Pos_Pc_Actl 1;
BA_ "U_U611_U625_MY20_Hev_Rx" SG_ 93 TrnSns2Pos_Pc_Actl 1;
BA_ "U_U611_U625_MY20_Gas_Rx" SG_ 93 TrnSns2Pos_Pc_Actl 1;
BA_ "U_U611_U625_MY20_Diesel_Rx" SG_ 93 TrnSns2Pos_Pc_Actl 1;
BA_ "ContentDependant" SG_ 93 TrnSns2Pos_Pc_Actl 1;
BA_ "U_U611_U625_MY20_Phev_Rx" SG_ 93 TrnSns1Pos_Pc_Actl 1;
BA_ "U_U611_U625_MY20_Hev_Rx" SG_ 93 TrnSns1Pos_Pc_Actl 1;
BA_ "U_U611_U625_MY20_Gas_Rx" SG_ 93 TrnSns1Pos_Pc_Actl 1;
BA_ "U_U611_U625_MY20_Diesel_Rx" SG_ 93 TrnSns1Pos_Pc_Actl 1;
BA_ "ContentDependant" SG_ 93 TrnSns1Pos_Pc_Actl 1;
BA_ "U_U611_U625_MY20_Phev_Rx" SG_ 93 TrnSecPrkStat_D_Actl 1;
BA_ "U_U611_U625_MY20_Hev_Rx" SG_ 93 TrnSecPrkStat_D_Actl 1;
BA_ "U_U611_U625_MY20_Gas_Rx" SG_ 93 TrnSecPrkStat_D_Actl 1;
BA_ "U_U611_U625_MY20_Diesel_Rx" SG_ 93 TrnSecPrkStat_D_Actl 1;
BA_ "GenSigSendType" SG_ 93 TrnSecPrkStat_D_Actl 3;
BA_ "ContentDependant" SG_ 93 TrnSecPrkStat_D_Actl 1;
BA_ "U_U611_U625_MY20_Phev_Rx" SG_ 93 TrnNtrlTowCnfm_B_Actl 1;
BA_ "U_U611_U625_MY20_Hev_Rx" SG_ 93 TrnNtrlTowCnfm_B_Actl 1;
BA_ "U_U611_U625_MY20_Gas_Rx" SG_ 93 TrnNtrlTowCnfm_B_Actl 1;
BA_ "U_U611_U625_MY20_Diesel_Rx" SG_ 93 TrnNtrlTowCnfm_B_Actl 1;
BA_ "GenSigSendType" SG_ 93 TrnNtrlTowCnfm_B_Actl 3;
BA_ "ContentDependant" SG_ 93 TrnNtrlTowCnfm_B_Actl 1;
BA_ "U_U611_U625_MY20_Phev_Rx" SG_ 93 TrnGearFinalPos_B_Actl 1;
BA_ "U_U611_U625_MY20_Hev_Rx" SG_ 93 TrnGearFinalPos_B_Actl 1;
BA_ "U_U611_U625_MY20_Gas_Rx" SG_ 93 TrnGearFinalPos_B_Actl 1;
BA_ "U_U611_U625_MY20_Diesel_Rx" SG_ 93 TrnGearFinalPos_B_Actl 1;
BA_ "GenSigSendType" SG_ 93 TrnGearFinalPos_B_Actl 3;
BA_ "ContentDependant" SG_ 93 TrnGearFinalPos_B_Actl 1;
BA_ "U_U611_U625_MY20_Phev_Rx" SG_ 93 TrnGearCnfm_No_Cs 1;
BA_ "U_U611_U625_MY20_Hev_Rx" SG_ 93 TrnGearCnfm_No_Cs 1;
BA_ "U_U611_U625_MY20_Gas_Rx" SG_ 93 TrnGearCnfm_No_Cs 1;
BA_ "U_U611_U625_MY20_Diesel_Rx" SG_ 93 TrnGearCnfm_No_Cs 1;
BA_ "ContentDependant" SG_ 93 TrnGearCnfm_No_Cs 1;
BA_ "U_U611_U625_MY20_Phev_Rx" SG_ 93 TrnGearCnfm_No_Cnt 1;
BA_ "U_U611_U625_MY20_Hev_Rx" SG_ 93 TrnGearCnfm_No_Cnt 1;
BA_ "U_U611_U625_MY20_Gas_Rx" SG_ 93 TrnGearCnfm_No_Cnt 1;
BA_ "U_U611_U625_MY20_Diesel_Rx" SG_ 93 TrnGearCnfm_No_Cnt 1;
BA_ "ContentDependant" SG_ 93 TrnGearCnfm_No_Cnt 1;
BA_ "U_U611_U625_MY20_Phev_Rx" SG_ 93 TrnGear_D_Actl 1;
BA_ "U_U611_U625_MY20_Hev_Rx" SG_ 93 TrnGear_D_Actl 1;
BA_ "U_U611_U625_MY20_Gas_Rx" SG_ 93 TrnGear_D_Actl 1;
BA_ "U_U611_U625_MY20_Diesel_Rx" SG_ 93 TrnGear_D_Actl 1;
BA_ "GenSigSendType" SG_ 93 TrnGear_D_Actl 3;
BA_ "ContentDependant" SG_ 93 TrnGear_D_Actl 1;
BA_ "U_U611_U625_MY20_Phev_Tx" SG_ 360 GsmSrvcRqd_B_Rq 1;
BA_ "U_CX482_CX483_MY20_Hev_Tx" SG_ 360 GsmSrvcRqd_B_Rq 1;
BA_ "U_CX482_CX483_MY20_Gas_Tx" SG_ 360 GsmSrvcRqd_B_Rq 1;
BA_ "U_CX482_CX483_MY20_Diesel_Tx" SG_ 360 GsmSrvcRqd_B_Rq 1;
BA_ "U_U611_U625_MY20_Hev_Tx" SG_ 360 GsmSrvcRqd_B_Rq 1;
BA_ "U_U611_U625_MY20_Gas_Tx" SG_ 360 GsmSrvcRqd_B_Rq 1;
BA_ "U_U611_U625_MY20_Diesel_Tx" SG_ 360 GsmSrvcRqd_B_Rq 1;
BA_ "U_C519_MY18_5_Gas_Tx" SG_ 360 GsmSrvcRqd_B_Rq 1;
BA_ "U_C519_MY18_5_Diesel_Tx" SG_ 360 GsmSrvcRqd_B_Rq 1;
BA_ "ContentDependant" SG_ 360 GsmSrvcRqd_B_Rq 1;
BA_ "CrossOver_InfoCAN" SG_ 360 GsmSrvcRqd_B_Rq 1;
BA_ "U_U611_U625_MY20_Phev_Tx" SG_ 360 TrnTrcmPwmSig_D_Actl 1;
BA_ "U_U611_U625_MY20_Hev_Tx" SG_ 360 TrnTrcmPwmSig_D_Actl 1;
BA_ "U_U611_U625_MY20_Gas_Tx" SG_ 360 TrnTrcmPwmSig_D_Actl 1;
BA_ "U_U611_U625_MY20_Diesel_Tx" SG_ 360 TrnTrcmPwmSig_D_Actl 1;
BA_ "U_C519_MY18_5_Gas_Tx" SG_ 360 TrnTrcmPwmSig_D_Actl 1;
BA_ "U_C519_MY18_5_Diesel_Tx" SG_ 360 TrnTrcmPwmSig_D_Actl 1;
BA_ "ContentDependant" SG_ 360 TrnTrcmPwmSig_D_Actl 1;
BA_ "CrossOver_InfoCAN" SG_ 360 TrnTrcmPwmSig_D_Actl 1;
BA_ "U_U611_U625_MY20_Phev_Tx" SG_ 360 TrnGearPwmFalt_B_Actl 1;
BA_ "U_CX482_CX483_MY20_Hev_Tx" SG_ 360 TrnGearPwmFalt_B_Actl 1;
BA_ "U_CX482_CX483_MY20_Gas_Tx" SG_ 360 TrnGearPwmFalt_B_Actl 1;
BA_ "U_CX482_CX483_MY20_Diesel_Tx" SG_ 360 TrnGearPwmFalt_B_Actl 1;
BA_ "U_U611_U625_MY20_Hev_Tx" SG_ 360 TrnGearPwmFalt_B_Actl 1;
BA_ "U_U611_U625_MY20_Gas_Tx" SG_ 360 TrnGearPwmFalt_B_Actl 1;
BA_ "U_U611_U625_MY20_Diesel_Tx" SG_ 360 TrnGearPwmFalt_B_Actl 1;
BA_ "U_C519_MY18_5_Gas_Tx" SG_ 360 TrnGearPwmFalt_B_Actl 1;
BA_ "U_C519_MY18_5_Diesel_Tx" SG_ 360 TrnGearPwmFalt_B_Actl 1;
BA_ "ContentDependant" SG_ 360 TrnGearPwmFalt_B_Actl 1;
BA_ "CrossOver_InfoCAN" SG_ 360 TrnGearPwmFalt_B_Actl 1;
BA_ "U_U611_U625_MY20_Phev_Tx" SG_ 360 GearButtnStuck_B_Actl 1;
BA_ "U_CX482_CX483_MY20_Hev_Tx" SG_ 360 GearButtnStuck_B_Actl 1;
BA_ "U_CX482_CX483_MY20_Gas_Tx" SG_ 360 GearButtnStuck_B_Actl 1;
BA_ "U_CX482_CX483_MY20_Diesel_Tx" SG_ 360 GearButtnStuck_B_Actl 1;
BA_ "U_U611_U625_MY20_Hev_Tx" SG_ 360 GearButtnStuck_B_Actl 1;
BA_ "U_U611_U625_MY20_Gas_Tx" SG_ 360 GearButtnStuck_B_Actl 1;
BA_ "U_U611_U625_MY20_Diesel_Tx" SG_ 360 GearButtnStuck_B_Actl 1;
BA_ "U_C519_MY18_5_Gas_Tx" SG_ 360 GearButtnStuck_B_Actl 1;
BA_ "U_C519_MY18_5_Diesel_Tx" SG_ 360 GearButtnStuck_B_Actl 1;
BA_ "ContentDependant" SG_ 360 GearButtnStuck_B_Actl 1;
BA_ "CrossOver_InfoCAN" SG_ 360 GearButtnStuck_B_Actl 1;
BA_ "U_U611_U625_MY20_Phev_Tx" SG_ 90 TrnGsmNtmState_D_Actl 1;
BA_ "U_CX482_CX483_MY20_Hev_Tx" SG_ 90 TrnGsmNtmState_D_Actl 1;
BA_ "U_CX482_CX483_MY20_Gas_Tx" SG_ 90 TrnGsmNtmState_D_Actl 1;
BA_ "U_CX482_CX483_MY20_Diesel_Tx" SG_ 90 TrnGsmNtmState_D_Actl 1;
BA_ "U_U611_U625_MY20_Hev_Tx" SG_ 90 TrnGsmNtmState_D_Actl 1;
BA_ "U_U611_U625_MY20_Gas_Tx" SG_ 90 TrnGsmNtmState_D_Actl 1;
BA_ "U_U611_U625_MY20_Diesel_Tx" SG_ 90 TrnGsmNtmState_D_Actl 1;
BA_ "U_C519_MY18_5_Gas_Tx" SG_ 90 TrnGsmNtmState_D_Actl 1;
BA_ "U_C519_MY18_5_Diesel_Tx" SG_ 90 TrnGsmNtmState_D_Actl 1;
BA_ "U_CX482_CX483_MY20_Hev_Rx" SG_ 90 TrnGsmNtmState_D_Actl 1;
BA_ "U_CX482_CX483_MY20_Gas_Rx" SG_ 90 TrnGsmNtmState_D_Actl 1;
BA_ "U_CX482_CX483_MY20_Diesel_Rx" SG_ 90 TrnGsmNtmState_D_Actl 1;
BA_ "U_C519_MY18_5_Gas_Rx" SG_ 90 TrnGsmNtmState_D_Actl 1;
BA_ "U_C519_MY18_5_Diesel_Rx" SG_ 90 TrnGsmNtmState_D_Actl 1;
BA_ "ContentDependant" SG_ 90 TrnGsmNtmState_D_Actl 1;
BA_ "CrossOver_InfoCAN" SG_ 90 TrnGsmNtmState_D_Actl 1;
BA_ "U_U611_U625_MY20_Phev_Tx" SG_ 90 DrQltyDrv_D_StatGsm 1;
BA_ "U_CX482_CX483_MY20_Hev_Tx" SG_ 90 DrQltyDrv_D_StatGsm 1;
BA_ "U_CX482_CX483_MY20_Gas_Tx" SG_ 90 DrQltyDrv_D_StatGsm 1;
BA_ "U_CX482_CX483_MY20_Diesel_Tx" SG_ 90 DrQltyDrv_D_StatGsm 1;
BA_ "U_U611_U625_MY20_Hev_Tx" SG_ 90 DrQltyDrv_D_StatGsm 1;
BA_ "U_U611_U625_MY20_Gas_Tx" SG_ 90 DrQltyDrv_D_StatGsm 1;
BA_ "U_U611_U625_MY20_Diesel_Tx" SG_ 90 DrQltyDrv_D_StatGsm 1;
BA_ "U_C519_MY18_5_Gas_Tx" SG_ 90 DrQltyDrv_D_StatGsm 1;
BA_ "U_C519_MY18_5_Diesel_Tx" SG_ 90 DrQltyDrv_D_StatGsm 1;
BA_ "U_CX482_CX483_MY20_Hev_Rx" SG_ 90 DrQltyDrv_D_StatGsm 1;
BA_ "U_CX482_CX483_MY20_Gas_Rx" SG_ 90 DrQltyDrv_D_StatGsm 1;
BA_ "U_CX482_CX483_MY20_Diesel_Rx" SG_ 90 DrQltyDrv_D_StatGsm 1;
BA_ "U_U611_U625_MY20_Hev_Rx" SG_ 90 DrQltyDrv_D_StatGsm 1;
BA_ "U_U611_U625_MY20_Gas_Rx" SG_ 90 DrQltyDrv_D_StatGsm 1;
BA_ "U_U611_U625_MY20_Diesel_Rx" SG_ 90 DrQltyDrv_D_StatGsm 1;
BA_ "U_C519_MY18_5_Gas_Rx" SG_ 90 DrQltyDrv_D_StatGsm 1;
BA_ "U_C519_MY18_5_Diesel_Rx" SG_ 90 DrQltyDrv_D_StatGsm 1;
BA_ "ContentDependant" SG_ 90 DrQltyDrv_D_StatGsm 1;
BA_ "U_U611_U625_MY20_Phev_Tx" SG_ 90 TrnBtsiOvrrd_B_Stat 1;
BA_ "U_CX482_CX483_MY20_Hev_Tx" SG_ 90 TrnBtsiOvrrd_B_Stat 1;
BA_ "U_CX482_CX483_MY20_Gas_Tx" SG_ 90 TrnBtsiOvrrd_B_Stat 1;
BA_ "U_CX482_CX483_MY20_Diesel_Tx" SG_ 90 TrnBtsiOvrrd_B_Stat 1;
BA_ "U_U611_U625_MY20_Hev_Tx" SG_ 90 TrnBtsiOvrrd_B_Stat 1;
BA_ "U_U611_U625_MY20_Gas_Tx" SG_ 90 TrnBtsiOvrrd_B_Stat 1;
BA_ "U_U611_U625_MY20_Diesel_Tx" SG_ 90 TrnBtsiOvrrd_B_Stat 1;
BA_ "U_C519_MY18_5_Gas_Tx" SG_ 90 TrnBtsiOvrrd_B_Stat 1;
BA_ "U_C519_MY18_5_Diesel_Tx" SG_ 90 TrnBtsiOvrrd_B_Stat 1;
BA_ "ContentDependant" SG_ 90 TrnBtsiOvrrd_B_Stat 1;
BA_ "U_U611_U625_MY20_Phev_Tx" SG_ 90 GsmGearMsgTxt_D_Rq 1;
BA_ "U_U611_U625_MY20_Hev_Tx" SG_ 90 GsmGearMsgTxt_D_Rq 1;
BA_ "U_U611_U625_MY20_Gas_Tx" SG_ 90 GsmGearMsgTxt_D_Rq 1;
BA_ "U_U611_U625_MY20_Diesel_Tx" SG_ 90 GsmGearMsgTxt_D_Rq 1;
BA_ "U_C519_MY18_5_Gas_Tx" SG_ 90 GsmGearMsgTxt_D_Rq 1;
BA_ "U_C519_MY18_5_Diesel_Tx" SG_ 90 GsmGearMsgTxt_D_Rq 1;
BA_ "GenSigSendType" SG_ 90 GsmGearMsgTxt_D_Rq 3;
BA_ "U_U611_U625_MY20_Phev_Tx" SG_ 90 TrnRng_D_RqGsm 1;
BA_ "U_U611_U625_MY20_Hev_Tx" SG_ 90 TrnRng_D_RqGsm 1;
BA_ "U_U611_U625_MY20_Gas_Tx" SG_ 90 TrnRng_D_RqGsm 1;
BA_ "U_U611_U625_MY20_Diesel_Tx" SG_ 90 TrnRng_D_RqGsm 1;
BA_ "U_C519_MY18_5_Gas_Tx" SG_ 90 TrnRng_D_RqGsm 1;
BA_ "U_C519_MY18_5_Diesel_Tx" SG_ 90 TrnRng_D_RqGsm 1;
BA_ "GenSigSendType" SG_ 90 TrnRng_D_RqGsm 3;
BA_ "GenSigStartValue" SG_ 90 TrnRng_D_RqGsm 14;
BA_ "U_U611_U625_MY20_Phev_Tx" SG_ 90 PrkBrkActv_D_RqGsmGear 1;
BA_ "U_U611_U625_MY20_Hev_Tx" SG_ 90 PrkBrkActv_D_RqGsmGear 1;
BA_ "U_U611_U625_MY20_Gas_Tx" SG_ 90 PrkBrkActv_D_RqGsmGear 1;
BA_ "U_U611_U625_MY20_Diesel_Tx" SG_ 90 PrkBrkActv_D_RqGsmGear 1;
BA_ "U_C519_MY18_5_Gas_Tx" SG_ 90 PrkBrkActv_D_RqGsmGear 1;
BA_ "U_C519_MY18_5_Diesel_Tx" SG_ 90 PrkBrkActv_D_RqGsmGear 1;
BA_ "GenSigSendType" SG_ 90 PrkBrkActv_D_RqGsmGear 3;
BA_ "U_U611_U625_MY20_Phev_Tx" SG_ 90 TrnValidGearRq_D_Stat 1;
BA_ "U_CX482_CX483_MY20_Hev_Tx" SG_ 90 TrnValidGearRq_D_Stat 1;
BA_ "U_CX482_CX483_MY20_Gas_Tx" SG_ 90 TrnValidGearRq_D_Stat 1;
BA_ "U_CX482_CX483_MY20_Diesel_Tx" SG_ 90 TrnValidGearRq_D_Stat 1;
BA_ "U_U611_U625_MY20_Hev_Tx" SG_ 90 TrnValidGearRq_D_Stat 1;
BA_ "U_U611_U625_MY20_Gas_Tx" SG_ 90 TrnValidGearRq_D_Stat 1;
BA_ "U_U611_U625_MY20_Diesel_Tx" SG_ 90 TrnValidGearRq_D_Stat 1;
BA_ "U_C519_MY18_5_Gas_Tx" SG_ 90 TrnValidGearRq_D_Stat 1;
BA_ "U_C519_MY18_5_Diesel_Tx" SG_ 90 TrnValidGearRq_D_Stat 1;
BA_ "ContentDependant" SG_ 90 TrnValidGearRq_D_Stat 1;
BA_ "U_U611_U625_MY20_Phev_Tx" SG_ 90 TrnGearRqCnt_B_Actl 1;
BA_ "U_CX482_CX483_MY20_Hev_Tx" SG_ 90 TrnGearRqCnt_B_Actl 1;
BA_ "U_CX482_CX483_MY20_Gas_Tx" SG_ 90 TrnGearRqCnt_B_Actl 1;
BA_ "U_CX482_CX483_MY20_Diesel_Tx" SG_ 90 TrnGearRqCnt_B_Actl 1;
BA_ "U_U611_U625_MY20_Hev_Tx" SG_ 90 TrnGearRqCnt_B_Actl 1;
BA_ "U_U611_U625_MY20_Gas_Tx" SG_ 90 TrnGearRqCnt_B_Actl 1;
BA_ "U_U611_U625_MY20_Diesel_Tx" SG_ 90 TrnGearRqCnt_B_Actl 1;
BA_ "U_C519_MY18_5_Gas_Tx" SG_ 90 TrnGearRqCnt_B_Actl 1;
BA_ "U_C519_MY18_5_Diesel_Tx" SG_ 90 TrnGearRqCnt_B_Actl 1;
BA_ "GenSigSendType" SG_ 90 TrnGearRqCnt_B_Actl 3;
BA_ "ContentDependant" SG_ 90 TrnGearRqCnt_B_Actl 1;
BA_ "U_U611_U625_MY20_Phev_Tx" SG_ 90 TrnGearButtn_U_Actl 1;
BA_ "U_CX482_CX483_MY20_Hev_Tx" SG_ 90 TrnGearButtn_U_Actl 1;
BA_ "U_CX482_CX483_MY20_Gas_Tx" SG_ 90 TrnGearButtn_U_Actl 1;
BA_ "U_CX482_CX483_MY20_Diesel_Tx" SG_ 90 TrnGearButtn_U_Actl 1;
BA_ "U_U611_U625_MY20_Hev_Tx" SG_ 90 TrnGearButtn_U_Actl 1;
BA_ "U_U611_U625_MY20_Gas_Tx" SG_ 90 TrnGearButtn_U_Actl 1;
BA_ "U_U611_U625_MY20_Diesel_Tx" SG_ 90 TrnGearButtn_U_Actl 1;
BA_ "U_C519_MY18_5_Gas_Tx" SG_ 90 TrnGearButtn_U_Actl 1;
BA_ "U_C519_MY18_5_Diesel_Tx" SG_ 90 TrnGearButtn_U_Actl 1;
BA_ "U_B479_MY17_Gas_Rx" SG_ 90 TrnGearButtn_U_Actl 1;
BA_ "ContentDependant" SG_ 90 TrnGearButtn_U_Actl 1;
BA_ "WakeupSignal" SG_ 90 TrnGearButtn_U_Actl 1;
BA_ "U_U611_U625_MY20_Phev_Tx" SG_ 90 TrnGearButtn_B_ActlR2 1;
BA_ "U_CX482_CX483_MY20_Hev_Tx" SG_ 90 TrnGearButtn_B_ActlR2 1;
BA_ "U_CX482_CX483_MY20_Gas_Tx" SG_ 90 TrnGearButtn_B_ActlR2 1;
BA_ "U_CX482_CX483_MY20_Diesel_Tx" SG_ 90 TrnGearButtn_B_ActlR2 1;
BA_ "U_U611_U625_MY20_Hev_Tx" SG_ 90 TrnGearButtn_B_ActlR2 1;
BA_ "U_U611_U625_MY20_Gas_Tx" SG_ 90 TrnGearButtn_B_ActlR2 1;
BA_ "U_U611_U625_MY20_Diesel_Tx" SG_ 90 TrnGearButtn_B_ActlR2 1;
BA_ "U_C519_MY18_5_Gas_Tx" SG_ 90 TrnGearButtn_B_ActlR2 1;
BA_ "U_C519_MY18_5_Diesel_Tx" SG_ 90 TrnGearButtn_B_ActlR2 1;
BA_ "U_B479_MY17_Gas_Rx" SG_ 90 TrnGearButtn_B_ActlR2 1;
BA_ "ContentDependant" SG_ 90 TrnGearButtn_B_ActlR2 1;
BA_ "WakeupSignal" SG_ 90 TrnGearButtn_B_ActlR2 1;
BA_ "U_U611_U625_MY20_Phev_Tx" SG_ 90 TrnGearButtn_B_ActlR1 1;
BA_ "U_CX482_CX483_MY20_Hev_Tx" SG_ 90 TrnGearButtn_B_ActlR1 1;
BA_ "U_CX482_CX483_MY20_Gas_Tx" SG_ 90 TrnGearButtn_B_ActlR1 1;
BA_ "U_CX482_CX483_MY20_Diesel_Tx" SG_ 90 TrnGearButtn_B_ActlR1 1;
BA_ "U_U611_U625_MY20_Hev_Tx" SG_ 90 TrnGearButtn_B_ActlR1 1;
BA_ "U_U611_U625_MY20_Gas_Tx" SG_ 90 TrnGearButtn_B_ActlR1 1;
BA_ "U_U611_U625_MY20_Diesel_Tx" SG_ 90 TrnGearButtn_B_ActlR1 1;
BA_ "U_C519_MY18_5_Gas_Tx" SG_ 90 TrnGearButtn_B_ActlR1 1;
BA_ "U_C519_MY18_5_Diesel_Tx" SG_ 90 TrnGearButtn_B_ActlR1 1;
BA_ "U_B479_MY17_Gas_Rx" SG_ 90 TrnGearButtn_B_ActlR1 1;
BA_ "ContentDependant" SG_ 90 TrnGearButtn_B_ActlR1 1;
BA_ "WakeupSignal" SG_ 90 TrnGearButtn_B_ActlR1 1;
BA_ "U_U611_U625_MY20_Phev_Tx" SG_ 90 TrnGearButtn_B_ActlR0 1;
BA_ "U_CX482_CX483_MY20_Hev_Tx" SG_ 90 TrnGearButtn_B_ActlR0 1;
BA_ "U_CX482_CX483_MY20_Gas_Tx" SG_ 90 TrnGearButtn_B_ActlR0 1;
BA_ "U_CX482_CX483_MY20_Diesel_Tx" SG_ 90 TrnGearButtn_B_ActlR0 1;
BA_ "U_U611_U625_MY20_Hev_Tx" SG_ 90 TrnGearButtn_B_ActlR0 1;
BA_ "U_U611_U625_MY20_Gas_Tx" SG_ 90 TrnGearButtn_B_ActlR0 1;
BA_ "U_U611_U625_MY20_Diesel_Tx" SG_ 90 TrnGearButtn_B_ActlR0 1;
BA_ "U_C519_MY18_5_Gas_Tx" SG_ 90 TrnGearButtn_B_ActlR0 1;
BA_ "U_C519_MY18_5_Diesel_Tx" SG_ 90 TrnGearButtn_B_ActlR0 1;
BA_ "U_B479_MY17_Gas_Rx" SG_ 90 TrnGearButtn_B_ActlR0 1;
BA_ "ContentDependant" SG_ 90 TrnGearButtn_B_ActlR0 1;
BA_ "WakeupSignal" SG_ 90 TrnGearButtn_B_ActlR0 1;
BA_ "U_U611_U625_MY20_Phev_Tx" SG_ 90 TrnGearButtn_B_ActlP2 1;
BA_ "U_CX482_CX483_MY20_Hev_Tx" SG_ 90 TrnGearButtn_B_ActlP2 1;
BA_ "U_CX482_CX483_MY20_Gas_Tx" SG_ 90 TrnGearButtn_B_ActlP2 1;
BA_ "U_CX482_CX483_MY20_Diesel_Tx" SG_ 90 TrnGearButtn_B_ActlP2 1;
BA_ "U_U611_U625_MY20_Hev_Tx" SG_ 90 TrnGearButtn_B_ActlP2 1;
BA_ "U_U611_U625_MY20_Gas_Tx" SG_ 90 TrnGearButtn_B_ActlP2 1;
BA_ "U_U611_U625_MY20_Diesel_Tx" SG_ 90 TrnGearButtn_B_ActlP2 1;
BA_ "U_C519_MY18_5_Gas_Tx" SG_ 90 TrnGearButtn_B_ActlP2 1;
BA_ "U_C519_MY18_5_Diesel_Tx" SG_ 90 TrnGearButtn_B_ActlP2 1;
BA_ "U_B479_MY17_Gas_Rx" SG_ 90 TrnGearButtn_B_ActlP2 1;
BA_ "ContentDependant" SG_ 90 TrnGearButtn_B_ActlP2 1;
BA_ "WakeupSignal" SG_ 90 TrnGearButtn_B_ActlP2 1;
BA_ "U_U611_U625_MY20_Phev_Tx" SG_ 90 TrnGearButtn_B_ActlP1 1;
BA_ "U_CX482_CX483_MY20_Hev_Tx" SG_ 90 TrnGearButtn_B_ActlP1 1;
BA_ "U_CX482_CX483_MY20_Gas_Tx" SG_ 90 TrnGearButtn_B_ActlP1 1;
BA_ "U_CX482_CX483_MY20_Diesel_Tx" SG_ 90 TrnGearButtn_B_ActlP1 1;
BA_ "U_U611_U625_MY20_Hev_Tx" SG_ 90 TrnGearButtn_B_ActlP1 1;
BA_ "U_U611_U625_MY20_Gas_Tx" SG_ 90 TrnGearButtn_B_ActlP1 1;
BA_ "U_U611_U625_MY20_Diesel_Tx" SG_ 90 TrnGearButtn_B_ActlP1 1;
BA_ "U_C519_MY18_5_Gas_Tx" SG_ 90 TrnGearButtn_B_ActlP1 1;
BA_ "U_C519_MY18_5_Diesel_Tx" SG_ 90 TrnGearButtn_B_ActlP1 1;
BA_ "U_B479_MY17_Gas_Rx" SG_ 90 TrnGearButtn_B_ActlP1 1;
BA_ "ContentDependant" SG_ 90 TrnGearButtn_B_ActlP1 1;
BA_ "WakeupSignal" SG_ 90 TrnGearButtn_B_ActlP1 1;
BA_ "U_U611_U625_MY20_Phev_Tx" SG_ 90 TrnGearButtn_B_ActlP0 1;
BA_ "U_CX482_CX483_MY20_Hev_Tx" SG_ 90 TrnGearButtn_B_ActlP0 1;
BA_ "U_CX482_CX483_MY20_Gas_Tx" SG_ 90 TrnGearButtn_B_ActlP0 1;
BA_ "U_CX482_CX483_MY20_Diesel_Tx" SG_ 90 TrnGearButtn_B_ActlP0 1;
BA_ "U_U611_U625_MY20_Hev_Tx" SG_ 90 TrnGearButtn_B_ActlP0 1;
BA_ "U_U611_U625_MY20_Gas_Tx" SG_ 90 TrnGearButtn_B_ActlP0 1;
BA_ "U_U611_U625_MY20_Diesel_Tx" SG_ 90 TrnGearButtn_B_ActlP0 1;
BA_ "U_C519_MY18_5_Gas_Tx" SG_ 90 TrnGearButtn_B_ActlP0 1;
BA_ "U_C519_MY18_5_Diesel_Tx" SG_ 90 TrnGearButtn_B_ActlP0 1;
BA_ "U_B479_MY17_Gas_Rx" SG_ 90 TrnGearButtn_B_ActlP0 1;
BA_ "ContentDependant" SG_ 90 TrnGearButtn_B_ActlP0 1;
BA_ "WakeupSignal" SG_ 90 TrnGearButtn_B_ActlP0 1;
BA_ "U_U611_U625_MY20_Phev_Tx" SG_ 90 TrnGearButtn_B_ActlN2 1;
BA_ "U_CX482_CX483_MY20_Hev_Tx" SG_ 90 TrnGearButtn_B_ActlN2 1;
BA_ "U_CX482_CX483_MY20_Gas_Tx" SG_ 90 TrnGearButtn_B_ActlN2 1;
BA_ "U_CX482_CX483_MY20_Diesel_Tx" SG_ 90 TrnGearButtn_B_ActlN2 1;
BA_ "U_U611_U625_MY20_Hev_Tx" SG_ 90 TrnGearButtn_B_ActlN2 1;
BA_ "U_U611_U625_MY20_Gas_Tx" SG_ 90 TrnGearButtn_B_ActlN2 1;
BA_ "U_U611_U625_MY20_Diesel_Tx" SG_ 90 TrnGearButtn_B_ActlN2 1;
BA_ "U_C519_MY18_5_Gas_Tx" SG_ 90 TrnGearButtn_B_ActlN2 1;
BA_ "U_C519_MY18_5_Diesel_Tx" SG_ 90 TrnGearButtn_B_ActlN2 1;
BA_ "U_B479_MY17_Gas_Rx" SG_ 90 TrnGearButtn_B_ActlN2 1;
BA_ "ContentDependant" SG_ 90 TrnGearButtn_B_ActlN2 1;
BA_ "WakeupSignal" SG_ 90 TrnGearButtn_B_ActlN2 1;
BA_ "U_U611_U625_MY20_Phev_Tx" SG_ 90 TrnGearButtn_B_ActlN1 1;
BA_ "U_CX482_CX483_MY20_Hev_Tx" SG_ 90 TrnGearButtn_B_ActlN1 1;
BA_ "U_CX482_CX483_MY20_Gas_Tx" SG_ 90 TrnGearButtn_B_ActlN1 1;
BA_ "U_CX482_CX483_MY20_Diesel_Tx" SG_ 90 TrnGearButtn_B_ActlN1 1;
BA_ "U_U611_U625_MY20_Hev_Tx" SG_ 90 TrnGearButtn_B_ActlN1 1;
BA_ "U_U611_U625_MY20_Gas_Tx" SG_ 90 TrnGearButtn_B_ActlN1 1;
BA_ "U_U611_U625_MY20_Diesel_Tx" SG_ 90 TrnGearButtn_B_ActlN1 1;
BA_ "U_C519_MY18_5_Gas_Tx" SG_ 90 TrnGearButtn_B_ActlN1 1;
BA_ "U_C519_MY18_5_Diesel_Tx" SG_ 90 TrnGearButtn_B_ActlN1 1;
BA_ "U_B479_MY17_Gas_Rx" SG_ 90 TrnGearButtn_B_ActlN1 1;
BA_ "ContentDependant" SG_ 90 TrnGearButtn_B_ActlN1 1;
BA_ "WakeupSignal" SG_ 90 TrnGearButtn_B_ActlN1 1;
BA_ "U_U611_U625_MY20_Phev_Tx" SG_ 90 TrnGearButtn_B_ActlN0 1;
BA_ "U_CX482_CX483_MY20_Hev_Tx" SG_ 90 TrnGearButtn_B_ActlN0 1;
BA_ "U_CX482_CX483_MY20_Gas_Tx" SG_ 90 TrnGearButtn_B_ActlN0 1;
BA_ "U_CX482_CX483_MY20_Diesel_Tx" SG_ 90 TrnGearButtn_B_ActlN0 1;
BA_ "U_U611_U625_MY20_Hev_Tx" SG_ 90 TrnGearButtn_B_ActlN0 1;
BA_ "U_U611_U625_MY20_Gas_Tx" SG_ 90 TrnGearButtn_B_ActlN0 1;
BA_ "U_U611_U625_MY20_Diesel_Tx" SG_ 90 TrnGearButtn_B_ActlN0 1;
BA_ "U_C519_MY18_5_Gas_Tx" SG_ 90 TrnGearButtn_B_ActlN0 1;
BA_ "U_C519_MY18_5_Diesel_Tx" SG_ 90 TrnGearButtn_B_ActlN0 1;
BA_ "U_B479_MY17_Gas_Rx" SG_ 90 TrnGearButtn_B_ActlN0 1;
BA_ "ContentDependant" SG_ 90 TrnGearButtn_B_ActlN0 1;
BA_ "WakeupSignal" SG_ 90 TrnGearButtn_B_ActlN0 1;
BA_ "U_U611_U625_MY20_Phev_Tx" SG_ 90 TrnGearButtn_B_ActlM2 1;
BA_ "U_CX482_CX483_MY20_Hev_Tx" SG_ 90 TrnGearButtn_B_ActlM2 1;
BA_ "U_CX482_CX483_MY20_Gas_Tx" SG_ 90 TrnGearButtn_B_ActlM2 1;
BA_ "U_CX482_CX483_MY20_Diesel_Tx" SG_ 90 TrnGearButtn_B_ActlM2 1;
BA_ "U_U611_U625_MY20_Hev_Tx" SG_ 90 TrnGearButtn_B_ActlM2 1;
BA_ "U_U611_U625_MY20_Gas_Tx" SG_ 90 TrnGearButtn_B_ActlM2 1;
BA_ "U_U611_U625_MY20_Diesel_Tx" SG_ 90 TrnGearButtn_B_ActlM2 1;
BA_ "U_C519_MY18_5_Gas_Tx" SG_ 90 TrnGearButtn_B_ActlM2 1;
BA_ "U_C519_MY18_5_Diesel_Tx" SG_ 90 TrnGearButtn_B_ActlM2 1;
BA_ "U_B479_MY17_Gas_Rx" SG_ 90 TrnGearButtn_B_ActlM2 1;
BA_ "ContentDependant" SG_ 90 TrnGearButtn_B_ActlM2 1;
BA_ "WakeupSignal" SG_ 90 TrnGearButtn_B_ActlM2 1;
BA_ "U_U611_U625_MY20_Phev_Tx" SG_ 90 TrnGearButtn_B_ActlM1 1;
BA_ "U_CX482_CX483_MY20_Hev_Tx" SG_ 90 TrnGearButtn_B_ActlM1 1;
BA_ "U_CX482_CX483_MY20_Gas_Tx" SG_ 90 TrnGearButtn_B_ActlM1 1;
BA_ "U_CX482_CX483_MY20_Diesel_Tx" SG_ 90 TrnGearButtn_B_ActlM1 1;
BA_ "U_U611_U625_MY20_Hev_Tx" SG_ 90 TrnGearButtn_B_ActlM1 1;
BA_ "U_U611_U625_MY20_Gas_Tx" SG_ 90 TrnGearButtn_B_ActlM1 1;
BA_ "U_U611_U625_MY20_Diesel_Tx" SG_ 90 TrnGearButtn_B_ActlM1 1;
BA_ "U_C519_MY18_5_Gas_Tx" SG_ 90 TrnGearButtn_B_ActlM1 1;
BA_ "U_C519_MY18_5_Diesel_Tx" SG_ 90 TrnGearButtn_B_ActlM1 1;
BA_ "U_B479_MY17_Gas_Rx" SG_ 90 TrnGearButtn_B_ActlM1 1;
BA_ "ContentDependant" SG_ 90 TrnGearButtn_B_ActlM1 1;
BA_ "WakeupSignal" SG_ 90 TrnGearButtn_B_ActlM1 1;
BA_ "U_U611_U625_MY20_Phev_Tx" SG_ 90 TrnGearButtn_B_ActlM0 1;
BA_ "U_CX482_CX483_MY20_Hev_Tx" SG_ 90 TrnGearButtn_B_ActlM0 1;
BA_ "U_CX482_CX483_MY20_Gas_Tx" SG_ 90 TrnGearButtn_B_ActlM0 1;
BA_ "U_CX482_CX483_MY20_Diesel_Tx" SG_ 90 TrnGearButtn_B_ActlM0 1;
BA_ "U_U611_U625_MY20_Hev_Tx" SG_ 90 TrnGearButtn_B_ActlM0 1;
BA_ "U_U611_U625_MY20_Gas_Tx" SG_ 90 TrnGearButtn_B_ActlM0 1;
BA_ "U_U611_U625_MY20_Diesel_Tx" SG_ 90 TrnGearButtn_B_ActlM0 1;
BA_ "U_C519_MY18_5_Gas_Tx" SG_ 90 TrnGearButtn_B_ActlM0 1;
BA_ "U_C519_MY18_5_Diesel_Tx" SG_ 90 TrnGearButtn_B_ActlM0 1;
BA_ "U_B479_MY17_Gas_Rx" SG_ 90 TrnGearButtn_B_ActlM0 1;
BA_ "ContentDependant" SG_ 90 TrnGearButtn_B_ActlM0 1;
BA_ "WakeupSignal" SG_ 90 TrnGearButtn_B_ActlM0 1;
BA_ "U_U611_U625_MY20_Phev_Tx" SG_ 90 TrnGearButtn_B_ActlD2 1;
BA_ "U_CX482_CX483_MY20_Hev_Tx" SG_ 90 TrnGearButtn_B_ActlD2 1;
BA_ "U_CX482_CX483_MY20_Gas_Tx" SG_ 90 TrnGearButtn_B_ActlD2 1;
BA_ "U_CX482_CX483_MY20_Diesel_Tx" SG_ 90 TrnGearButtn_B_ActlD2 1;
BA_ "U_U611_U625_MY20_Hev_Tx" SG_ 90 TrnGearButtn_B_ActlD2 1;
BA_ "U_U611_U625_MY20_Gas_Tx" SG_ 90 TrnGearButtn_B_ActlD2 1;
BA_ "U_U611_U625_MY20_Diesel_Tx" SG_ 90 TrnGearButtn_B_ActlD2 1;
BA_ "U_C519_MY18_5_Gas_Tx" SG_ 90 TrnGearButtn_B_ActlD2 1;
BA_ "U_C519_MY18_5_Diesel_Tx" SG_ 90 TrnGearButtn_B_ActlD2 1;
BA_ "U_B479_MY17_Gas_Rx" SG_ 90 TrnGearButtn_B_ActlD2 1;
BA_ "ContentDependant" SG_ 90 TrnGearButtn_B_ActlD2 1;
BA_ "WakeupSignal" SG_ 90 TrnGearButtn_B_ActlD2 1;
BA_ "U_U611_U625_MY20_Phev_Tx" SG_ 90 TrnGearButtn_B_ActlD1 1;
BA_ "U_CX482_CX483_MY20_Hev_Tx" SG_ 90 TrnGearButtn_B_ActlD1 1;
BA_ "U_CX482_CX483_MY20_Gas_Tx" SG_ 90 TrnGearButtn_B_ActlD1 1;
BA_ "U_CX482_CX483_MY20_Diesel_Tx" SG_ 90 TrnGearButtn_B_ActlD1 1;
BA_ "U_U611_U625_MY20_Hev_Tx" SG_ 90 TrnGearButtn_B_ActlD1 1;
BA_ "U_U611_U625_MY20_Gas_Tx" SG_ 90 TrnGearButtn_B_ActlD1 1;
BA_ "U_U611_U625_MY20_Diesel_Tx" SG_ 90 TrnGearButtn_B_ActlD1 1;
BA_ "U_C519_MY18_5_Gas_Tx" SG_ 90 TrnGearButtn_B_ActlD1 1;
BA_ "U_C519_MY18_5_Diesel_Tx" SG_ 90 TrnGearButtn_B_ActlD1 1;
BA_ "U_B479_MY17_Gas_Rx" SG_ 90 TrnGearButtn_B_ActlD1 1;
BA_ "ContentDependant" SG_ 90 TrnGearButtn_B_ActlD1 1;
BA_ "WakeupSignal" SG_ 90 TrnGearButtn_B_ActlD1 1;
BA_ "U_U611_U625_MY20_Phev_Tx" SG_ 90 TrnGearButtn_B_ActlD0 1;
BA_ "U_CX482_CX483_MY20_Hev_Tx" SG_ 90 TrnGearButtn_B_ActlD0 1;
BA_ "U_CX482_CX483_MY20_Gas_Tx" SG_ 90 TrnGearButtn_B_ActlD0 1;
BA_ "U_CX482_CX483_MY20_Diesel_Tx" SG_ 90 TrnGearButtn_B_ActlD0 1;
BA_ "U_U611_U625_MY20_Hev_Tx" SG_ 90 TrnGearButtn_B_ActlD0 1;
BA_ "U_U611_U625_MY20_Gas_Tx" SG_ 90 TrnGearButtn_B_ActlD0 1;
BA_ "U_U611_U625_MY20_Diesel_Tx" SG_ 90 TrnGearButtn_B_ActlD0 1;
BA_ "U_C519_MY18_5_Gas_Tx" SG_ 90 TrnGearButtn_B_ActlD0 1;
BA_ "U_C519_MY18_5_Diesel_Tx" SG_ 90 TrnGearButtn_B_ActlD0 1;
BA_ "U_B479_MY17_Gas_Rx" SG_ 90 TrnGearButtn_B_ActlD0 1;
BA_ "ContentDependant" SG_ 90 TrnGearButtn_B_ActlD0 1;
BA_ "WakeupSignal" SG_ 90 TrnGearButtn_B_ActlD0 1;
BA_ "U_U611_U625_MY20_Phev_Tx" SG_ 90 TrnGear_No_Cs 1;
BA_ "U_CX482_CX483_MY20_Hev_Tx" SG_ 90 TrnGear_No_Cs 1;
BA_ "U_CX482_CX483_MY20_Gas_Tx" SG_ 90 TrnGear_No_Cs 1;
BA_ "U_CX482_CX483_MY20_Diesel_Tx" SG_ 90 TrnGear_No_Cs 1;
BA_ "U_U611_U625_MY20_Hev_Tx" SG_ 90 TrnGear_No_Cs 1;
BA_ "U_U611_U625_MY20_Gas_Tx" SG_ 90 TrnGear_No_Cs 1;
BA_ "U_U611_U625_MY20_Diesel_Tx" SG_ 90 TrnGear_No_Cs 1;
BA_ "U_C519_MY18_5_Gas_Tx" SG_ 90 TrnGear_No_Cs 1;
BA_ "U_C519_MY18_5_Diesel_Tx" SG_ 90 TrnGear_No_Cs 1;
BA_ "ContentDependant" SG_ 90 TrnGear_No_Cs 1;
BA_ "WakeupSignal" SG_ 90 TrnGear_No_Cs 1;
BA_ "U_U611_U625_MY20_Phev_Tx" SG_ 90 TrnGear_No_Cnt 1;
BA_ "U_CX482_CX483_MY20_Hev_Tx" SG_ 90 TrnGear_No_Cnt 1;
BA_ "U_CX482_CX483_MY20_Gas_Tx" SG_ 90 TrnGear_No_Cnt 1;
BA_ "U_CX482_CX483_MY20_Diesel_Tx" SG_ 90 TrnGear_No_Cnt 1;
BA_ "U_U611_U625_MY20_Hev_Tx" SG_ 90 TrnGear_No_Cnt 1;
BA_ "U_U611_U625_MY20_Gas_Tx" SG_ 90 TrnGear_No_Cnt 1;
BA_ "U_U611_U625_MY20_Diesel_Tx" SG_ 90 TrnGear_No_Cnt 1;
BA_ "U_C519_MY18_5_Gas_Tx" SG_ 90 TrnGear_No_Cnt 1;
BA_ "U_C519_MY18_5_Diesel_Tx" SG_ 90 TrnGear_No_Cnt 1;
BA_ "ContentDependant" SG_ 90 TrnGear_No_Cnt 1;
BA_ "U_U611_U625_MY20_Phev_Tx" SG_ 90 TrnGear_D_RqDrv 1;
BA_ "U_CX482_CX483_MY20_Hev_Tx" SG_ 90 TrnGear_D_RqDrv 1;
BA_ "U_CX482_CX483_MY20_Gas_Tx" SG_ 90 TrnGear_D_RqDrv 1;
BA_ "U_CX482_CX483_MY20_Diesel_Tx" SG_ 90 TrnGear_D_RqDrv 1;
BA_ "U_U611_U625_MY20_Hev_Tx" SG_ 90 TrnGear_D_RqDrv 1;
BA_ "U_U611_U625_MY20_Gas_Tx" SG_ 90 TrnGear_D_RqDrv 1;
BA_ "U_U611_U625_MY20_Diesel_Tx" SG_ 90 TrnGear_D_RqDrv 1;
BA_ "U_C519_MY18_5_Gas_Tx" SG_ 90 TrnGear_D_RqDrv 1;
BA_ "U_C519_MY18_5_Diesel_Tx" SG_ 90 TrnGear_D_RqDrv 1;
BA_ "GenSigSendType" SG_ 90 TrnGear_D_RqDrv 3;
BA_ "ContentDependant" SG_ 90 TrnGear_D_RqDrv 1;
BA_ "U_U611_U625_MY20_Phev_Tx" SG_ 90 BrkSwtchPos_B_ActlGsm 1;
BA_ "U_CX482_CX483_MY20_Hev_Tx" SG_ 90 BrkSwtchPos_B_ActlGsm 1;
BA_ "U_CX482_CX483_MY20_Gas_Tx" SG_ 90 BrkSwtchPos_B_ActlGsm 1;
BA_ "U_CX482_CX483_MY20_Diesel_Tx" SG_ 90 BrkSwtchPos_B_ActlGsm 1;
BA_ "U_U611_U625_MY20_Hev_Tx" SG_ 90 BrkSwtchPos_B_ActlGsm 1;
BA_ "U_U611_U625_MY20_Gas_Tx" SG_ 90 BrkSwtchPos_B_ActlGsm 1;
BA_ "U_U611_U625_MY20_Diesel_Tx" SG_ 90 BrkSwtchPos_B_ActlGsm 1;
BA_ "U_C519_MY18_5_Gas_Tx" SG_ 90 BrkSwtchPos_B_ActlGsm 1;
BA_ "U_C519_MY18_5_Diesel_Tx" SG_ 90 BrkSwtchPos_B_ActlGsm 1;
BA_ "ContentDependant" SG_ 90 BrkSwtchPos_B_ActlGsm 1;
BA_ "GenSigSendType" SG_ 1809 TesterPhysicalReqTRCM 3;
BA_ "U_U611_U625_MY20_Phev_Rx" SG_ 1842 TesterPhysicalReqGSM 1;
BA_ "U_CX482_CX483_MY20_Hev_Rx" SG_ 1842 TesterPhysicalReqGSM 1;
BA_ "U_CX482_CX483_MY20_Gas_Rx" SG_ 1842 TesterPhysicalReqGSM 1;
BA_ "U_CX482_CX483_MY20_Diesel_Rx" SG_ 1842 TesterPhysicalReqGSM 1;
BA_ "U_U611_U625_MY20_Hev_Rx" SG_ 1842 TesterPhysicalReqGSM 1;
BA_ "U_U611_U625_MY20_Gas_Rx" SG_ 1842 TesterPhysicalReqGSM 1;
BA_ "U_U611_U625_MY20_Diesel_Rx" SG_ 1842 TesterPhysicalReqGSM 1;
BA_ "U_C519_MY18_5_Gas_Rx" SG_ 1842 TesterPhysicalReqGSM 1;
BA_ "U_C519_MY18_5_Diesel_Rx" SG_ 1842 TesterPhysicalReqGSM 1;
BA_ "GenSigSendType" SG_ 1842 TesterPhysicalReqGSM 3;
BA_ "GenSigSendType" SG_ 1817 TesterPhysicalResTRCM 3;
BA_ "U_U611_U625_MY20_Phev_Tx" SG_ 1850 TesterPhysicalResGSM 1;
BA_ "U_CX482_CX483_MY20_Hev_Tx" SG_ 1850 TesterPhysicalResGSM 1;
BA_ "U_CX482_CX483_MY20_Gas_Tx" SG_ 1850 TesterPhysicalResGSM 1;
BA_ "U_CX482_CX483_MY20_Diesel_Tx" SG_ 1850 TesterPhysicalResGSM 1;
BA_ "U_U611_U625_MY20_Hev_Tx" SG_ 1850 TesterPhysicalResGSM 1;
BA_ "U_U611_U625_MY20_Gas_Tx" SG_ 1850 TesterPhysicalResGSM 1;
BA_ "U_U611_U625_MY20_Diesel_Tx" SG_ 1850 TesterPhysicalResGSM 1;
BA_ "U_C519_MY18_5_Gas_Tx" SG_ 1850 TesterPhysicalResGSM 1;
BA_ "U_C519_MY18_5_Diesel_Tx" SG_ 1850 TesterPhysicalResGSM 1;
BA_ "GenSigSendType" SG_ 1850 TesterPhysicalResGSM 3;
BA_ "GenSigSendType" SG_ 1889 TesterPhysicalReqTCCM 3;
BA_ "GenSigSendType" SG_ 1897 TesterPhysicalResTCCM 3;
BA_ "U_B500_MY18_Diesel_Rx" SG_ 512 PtDrvMde_D_Stat 1;
BA_ "U_B500_MY18_Gas_Rx" SG_ 512 PtDrvMde_D_Stat 1;
BA_ "U_B515_MCA_MY17_Gas_Rx" SG_ 512 PtDrvMde_D_Stat 1;
BA_ "U_B515_MCA_MY17_Diesel_Rx" SG_ 512 PtDrvMde_D_Stat 1;
BA_ "U_CX482_CX483_MY20_Hev_Rx" SG_ 512 PtDrvMde_D_Stat 1;
BA_ "U_CX482_CX483_MY20_Gas_Rx" SG_ 512 PtDrvMde_D_Stat 1;
BA_ "U_CX482_CX483_MY20_Diesel_Rx" SG_ 512 PtDrvMde_D_Stat 1;
BA_ "U_U611_U625_MY20_Hev_Rx" SG_ 512 PtDrvMde_D_Stat 1;
BA_ "U_U611_U625_MY20_Gas_Rx" SG_ 512 PtDrvMde_D_Stat 1;
BA_ "U_U611_U625_MY20_Diesel_Rx" SG_ 512 PtDrvMde_D_Stat 1;
BA_ "U_C519_MY18_5_Gas_Rx" SG_ 512 PtDrvMde_D_Stat 1;
BA_ "U_C519_MY18_5_Diesel_Rx" SG_ 512 PtDrvMde_D_Stat 1;
BA_ "U_B479_MY17_Diesel_Rx" SG_ 512 PtDrvMde_D_Stat 1;
BA_ "U_B479_MY17_Gas_Rx" SG_ 512 PtDrvMde_D_Stat 1;
BA_ "U_CX482_CX483_MY20_Hev_Rx" SG_ 512 PrplWhlTotTqRq_No_Cs 1;
BA_ "U_CX482_CX483_MY20_Gas_Rx" SG_ 512 PrplWhlTotTqRq_No_Cs 1;
BA_ "U_CX482_CX483_MY20_Diesel_Rx" SG_ 512 PrplWhlTotTqRq_No_Cs 1;
BA_ "U_U611_U625_MY20_Hev_Rx" SG_ 512 PrplWhlTotTqRq_No_Cs 1;
BA_ "U_U611_U625_MY20_Gas_Rx" SG_ 512 PrplWhlTotTqRq_No_Cs 1;
BA_ "U_U611_U625_MY20_Diesel_Rx" SG_ 512 PrplWhlTotTqRq_No_Cs 1;
BA_ "U_B500_MY18_Diesel_Rx" SG_ 512 PrplWhlTotTqRq_No_Cs 1;
BA_ "U_B500_MY18_Gas_Rx" SG_ 512 PrplWhlTotTqRq_No_Cs 1;
BA_ "U_B515_MCA_MY17_Gas_Rx" SG_ 512 PrplWhlTotTqRq_No_Cs 1;
BA_ "U_B515_MCA_MY17_Diesel_Rx" SG_ 512 PrplWhlTotTqRq_No_Cs 1;
BA_ "U_B479_MY17_Diesel_Rx" SG_ 512 PrplWhlTotTqRq_No_Cs 1;
BA_ "U_B479_MY17_Gas_Rx" SG_ 512 PrplWhlTotTqRq_No_Cs 1;
BA_ "ContentDependant" SG_ 512 PrplWhlTotTqRq_No_Cs 1;
BA_ "U_CX482_CX483_MY20_Hev_Rx" SG_ 512 PrplWhlTotTqRq_No_Cnt 1;
BA_ "U_CX482_CX483_MY20_Gas_Rx" SG_ 512 PrplWhlTotTqRq_No_Cnt 1;
BA_ "U_CX482_CX483_MY20_Diesel_Rx" SG_ 512 PrplWhlTotTqRq_No_Cnt 1;
BA_ "U_U611_U625_MY20_Hev_Rx" SG_ 512 PrplWhlTotTqRq_No_Cnt 1;
BA_ "U_U611_U625_MY20_Gas_Rx" SG_ 512 PrplWhlTotTqRq_No_Cnt 1;
BA_ "U_U611_U625_MY20_Diesel_Rx" SG_ 512 PrplWhlTotTqRq_No_Cnt 1;
BA_ "U_B500_MY18_Diesel_Rx" SG_ 512 PrplWhlTotTqRq_No_Cnt 1;
BA_ "U_B500_MY18_Gas_Rx" SG_ 512 PrplWhlTotTqRq_No_Cnt 1;
BA_ "U_B515_MCA_MY17_Gas_Rx" SG_ 512 PrplWhlTotTqRq_No_Cnt 1;
BA_ "U_B515_MCA_MY17_Diesel_Rx" SG_ 512 PrplWhlTotTqRq_No_Cnt 1;
BA_ "U_B479_MY17_Diesel_Rx" SG_ 512 PrplWhlTotTqRq_No_Cnt 1;
BA_ "U_B479_MY17_Gas_Rx" SG_ 512 PrplWhlTotTqRq_No_Cnt 1;
BA_ "ContentDependant" SG_ 512 PrplWhlTotTqRq_No_Cnt 1;
BA_ "ContentDependant" SG_ 512 EngAout_Tq_MxMxN 1;
BA_ "U_CX482_CX483_MY20_Hev_Rx" SG_ 512 PrplWhlTot_Tq_Rq 1;
BA_ "U_CX482_CX483_MY20_Gas_Rx" SG_ 512 PrplWhlTot_Tq_Rq 1;
BA_ "U_CX482_CX483_MY20_Diesel_Rx" SG_ 512 PrplWhlTot_Tq_Rq 1;
BA_ "U_B500_MY18_Diesel_Rx" SG_ 512 PrplWhlTot_Tq_Rq 1;
BA_ "U_B500_MY18_Gas_Rx" SG_ 512 PrplWhlTot_Tq_Rq 1;
BA_ "U_B515_MCA_MY17_Gas_Rx" SG_ 512 PrplWhlTot_Tq_Rq 1;
BA_ "U_B515_MCA_MY17_Diesel_Rx" SG_ 512 PrplWhlTot_Tq_Rq 1;
BA_ "U_B479_MY17_Diesel_Rx" SG_ 512 PrplWhlTot_Tq_Rq 1;
BA_ "U_B479_MY17_Gas_Rx" SG_ 512 PrplWhlTot_Tq_Rq 1;
BA_ "U_U611_U625_MY20_Phev_Rx" SG_ 512 PrplWhlTot_Tq_Rq 1;
BA_ "U_U611_U625_MY20_Hev_Rx" SG_ 512 PrplWhlTot_Tq_Rq 1;
BA_ "U_U611_U625_MY20_Gas_Rx" SG_ 512 PrplWhlTot_Tq_Rq 1;
BA_ "U_U611_U625_MY20_Diesel_Rx" SG_ 512 PrplWhlTot_Tq_Rq 1;
BA_ "U_C519_MY18_5_Gas_Rx" SG_ 512 PrplWhlTot_Tq_Rq 1;
BA_ "U_C519_MY18_5_Diesel_Rx" SG_ 512 PrplWhlTot_Tq_Rq 1;
BA_ "U_CX482_CX483_MY20_Hev_Rx" SG_ 512 PrplWhlTot_Tq_LimMn 1;
BA_ "U_CX482_CX483_MY20_Gas_Rx" SG_ 512 PrplWhlTot_Tq_LimMn 1;
BA_ "U_CX482_CX483_MY20_Diesel_Rx" SG_ 512 PrplWhlTot_Tq_LimMn 1;
BA_ "U_U611_U625_MY20_Hev_Rx" SG_ 512 PrplWhlTot_Tq_LimMn 1;
BA_ "U_U611_U625_MY20_Gas_Rx" SG_ 512 PrplWhlTot_Tq_LimMn 1;
BA_ "U_U611_U625_MY20_Diesel_Rx" SG_ 512 PrplWhlTot_Tq_LimMn 1;
BA_ "U_B500_MY18_Diesel_Rx" SG_ 512 PrplWhlTot_Tq_LimMn 1;
BA_ "U_B500_MY18_Gas_Rx" SG_ 512 PrplWhlTot_Tq_LimMn 1;
BA_ "U_C519_MY18_5_Gas_Rx" SG_ 512 PrplWhlTot_Tq_LimMn 1;
BA_ "U_C519_MY18_5_Diesel_Rx" SG_ 512 PrplWhlTot_Tq_LimMn 1;
BA_ "U_B515_MCA_MY17_Gas_Rx" SG_ 512 PrplWhlTot_Tq_LimMn 1;
BA_ "U_B515_MCA_MY17_Diesel_Rx" SG_ 512 PrplWhlTot_Tq_LimMn 1;
BA_ "U_B479_MY17_Diesel_Rx" SG_ 512 PrplWhlTot_Tq_LimMn 1;
BA_ "U_B479_MY17_Gas_Rx" SG_ 512 PrplWhlTot_Tq_LimMn 1;
BA_ "U_B562_MY18_Gas_Rx" SG_ 936 EPASExtAngleStatReq 1;
BA_ "U_U611_U625_MY20_Phev_Rx" SG_ 936 EPASExtAngleStatReq 1;
BA_ "U_CX482_CX483_MY20_Hev_Rx" SG_ 936 EPASExtAngleStatReq 1;
BA_ "U_CX482_CX483_MY20_Gas_Rx" SG_ 936 EPASExtAngleStatReq 1;
BA_ "U_CX482_CX483_MY20_Diesel_Rx" SG_ 936 EPASExtAngleStatReq 1;
BA_ "U_U611_U625_MY20_Hev_Rx" SG_ 936 EPASExtAngleStatReq 1;
BA_ "U_U611_U625_MY20_Gas_Rx" SG_ 936 EPASExtAngleStatReq 1;
BA_ "U_U611_U625_MY20_Diesel_Rx" SG_ 936 EPASExtAngleStatReq 1;
BA_ "U_B500_MY18_Diesel_Rx" SG_ 936 EPASExtAngleStatReq 1;
BA_ "U_B500_MY18_Gas_Rx" SG_ 936 EPASExtAngleStatReq 1;
BA_ "U_C519_MY18_5_Gas_Rx" SG_ 936 EPASExtAngleStatReq 1;
BA_ "U_C519_MY18_5_Diesel_Rx" SG_ 936 EPASExtAngleStatReq 1;
BA_ "U_B515_MCA_MY17_Gas_Rx" SG_ 936 EPASExtAngleStatReq 1;
BA_ "U_B515_MCA_MY17_Diesel_Rx" SG_ 936 EPASExtAngleStatReq 1;
BA_ "U_B479_MY17_Diesel_Rx" SG_ 936 EPASExtAngleStatReq 1;
BA_ "U_B479_MY17_Gas_Rx" SG_ 936 EPASExtAngleStatReq 1;
BA_ "U_U611_U625_MY20_Phev_Rx" SG_ 936 SAPPStatusCoding 1;
BA_ "U_U611_U625_MY20_Hev_Rx" SG_ 936 SAPPStatusCoding 1;
BA_ "U_U611_U625_MY20_Gas_Rx" SG_ 936 SAPPStatusCoding 1;
BA_ "U_U611_U625_MY20_Diesel_Rx" SG_ 936 SAPPStatusCoding 1;
BA_ "CrossOver_InfoCAN" SG_ 936 SAPPStatusCoding 1;
BA_ "GenSigMissingSourceValue" SG_ 936 SAPPStatusCoding 6;
BA_ "U_U611_U625_MY20_Phev_Rx" SG_ 936 ExtSteeringAngleReq2 1;
BA_ "U_CX482_CX483_MY20_Hev_Rx" SG_ 936 ExtSteeringAngleReq2 1;
BA_ "U_CX482_CX483_MY20_Gas_Rx" SG_ 936 ExtSteeringAngleReq2 1;
BA_ "U_CX482_CX483_MY20_Diesel_Rx" SG_ 936 ExtSteeringAngleReq2 1;
BA_ "U_U611_U625_MY20_Hev_Rx" SG_ 936 ExtSteeringAngleReq2 1;
BA_ "U_U611_U625_MY20_Gas_Rx" SG_ 936 ExtSteeringAngleReq2 1;
BA_ "U_U611_U625_MY20_Diesel_Rx" SG_ 936 ExtSteeringAngleReq2 1;
BA_ "U_B500_MY18_Diesel_Rx" SG_ 936 ExtSteeringAngleReq2 1;
BA_ "U_B500_MY18_Gas_Rx" SG_ 936 ExtSteeringAngleReq2 1;
BA_ "U_C519_MY18_5_Gas_Rx" SG_ 936 ExtSteeringAngleReq2 1;
BA_ "U_C519_MY18_5_Diesel_Rx" SG_ 936 ExtSteeringAngleReq2 1;
BA_ "U_B479_MY17_Diesel_Rx" SG_ 936 ExtSteeringAngleReq2 1;
BA_ "U_B479_MY17_Gas_Rx" SG_ 936 ExtSteeringAngleReq2 1;
BA_ "U_U611_U625_MY20_Phev_Tx" SG_ 570 SuspRearRight_L_Actl 1;
BA_ "U_U611_U625_MY20_Hev_Tx" SG_ 570 SuspRearRight_L_Actl 1;
BA_ "U_U611_U625_MY20_Gas_Tx" SG_ 570 SuspRearRight_L_Actl 1;
BA_ "U_U611_U625_MY20_Diesel_Tx" SG_ 570 SuspRearRight_L_Actl 1;
BA_ "U_C519_MY18_5_Gas_Tx" SG_ 570 SuspRearRight_L_Actl 1;
BA_ "U_C519_MY18_5_Diesel_Tx" SG_ 570 SuspRearRight_L_Actl 1;
BA_ "GenSigStartValue" SG_ 570 SuspRearRight_L_Actl 511;
BA_ "U_U611_U625_MY20_Phev_Tx" SG_ 570 SuspFrntRight_L_Actl 1;
BA_ "U_U611_U625_MY20_Hev_Tx" SG_ 570 SuspFrntRight_L_Actl 1;
BA_ "U_U611_U625_MY20_Gas_Tx" SG_ 570 SuspFrntRight_L_Actl 1;
BA_ "U_U611_U625_MY20_Diesel_Tx" SG_ 570 SuspFrntRight_L_Actl 1;
BA_ "U_C519_MY18_5_Gas_Tx" SG_ 570 SuspFrntRight_L_Actl 1;
BA_ "U_C519_MY18_5_Diesel_Tx" SG_ 570 SuspFrntRight_L_Actl 1;
BA_ "GenSigStartValue" SG_ 570 SuspFrntRight_L_Actl 511;
BA_ "U_U611_U625_MY20_Phev_Tx" SG_ 570 SuspRear_L_Prev 1;
BA_ "U_U611_U625_MY20_Hev_Tx" SG_ 570 SuspRear_L_Prev 1;
BA_ "U_U611_U625_MY20_Gas_Tx" SG_ 570 SuspRear_L_Prev 1;
BA_ "U_U611_U625_MY20_Diesel_Tx" SG_ 570 SuspRear_L_Prev 1;
BA_ "U_C519_MY18_5_Gas_Tx" SG_ 570 SuspRear_L_Prev 1;
BA_ "U_C519_MY18_5_Diesel_Tx" SG_ 570 SuspRear_L_Prev 1;
BA_ "U_CX482_CX483_MY20_Hev_Rx" SG_ 570 SuspRear_L_Prev 1;
BA_ "U_CX482_CX483_MY20_Gas_Rx" SG_ 570 SuspRear_L_Prev 1;
BA_ "U_CX482_CX483_MY20_Diesel_Rx" SG_ 570 SuspRear_L_Prev 1;
BA_ "U_U611_U625_MY20_Hev_Rx" SG_ 570 SuspRear_L_Prev 1;
BA_ "U_U611_U625_MY20_Gas_Rx" SG_ 570 SuspRear_L_Prev 1;
BA_ "U_U611_U625_MY20_Diesel_Rx" SG_ 570 SuspRear_L_Prev 1;
BA_ "U_C519_MY18_5_Gas_Rx" SG_ 570 SuspRear_L_Prev 1;
BA_ "U_C519_MY18_5_Diesel_Rx" SG_ 570 SuspRear_L_Prev 1;
BA_ "GenSigStartValue" SG_ 570 SuspRear_L_Prev 511;
BA_ "U_U611_U625_MY20_Phev_Tx" SG_ 570 SuspRear_L_Actl 1;
BA_ "U_U611_U625_MY20_Hev_Tx" SG_ 570 SuspRear_L_Actl 1;
BA_ "U_U611_U625_MY20_Gas_Tx" SG_ 570 SuspRear_L_Actl 1;
BA_ "U_U611_U625_MY20_Diesel_Tx" SG_ 570 SuspRear_L_Actl 1;
BA_ "U_C519_MY18_5_Gas_Tx" SG_ 570 SuspRear_L_Actl 1;
BA_ "U_C519_MY18_5_Diesel_Tx" SG_ 570 SuspRear_L_Actl 1;
BA_ "U_CX482_CX483_MY20_Hev_Rx" SG_ 570 SuspRear_L_Actl 1;
BA_ "U_CX482_CX483_MY20_Gas_Rx" SG_ 570 SuspRear_L_Actl 1;
BA_ "U_CX482_CX483_MY20_Diesel_Rx" SG_ 570 SuspRear_L_Actl 1;
BA_ "U_U611_U625_MY20_Hev_Rx" SG_ 570 SuspRear_L_Actl 1;
BA_ "U_U611_U625_MY20_Gas_Rx" SG_ 570 SuspRear_L_Actl 1;
BA_ "U_U611_U625_MY20_Diesel_Rx" SG_ 570 SuspRear_L_Actl 1;
BA_ "U_C519_MY18_5_Gas_Rx" SG_ 570 SuspRear_L_Actl 1;
BA_ "U_C519_MY18_5_Diesel_Rx" SG_ 570 SuspRear_L_Actl 1;
BA_ "GenSigStartValue" SG_ 570 SuspRear_L_Actl 511;
BA_ "U_U611_U625_MY20_Phev_Tx" SG_ 570 SuspFrnt_L_Prev 1;
BA_ "U_U611_U625_MY20_Hev_Tx" SG_ 570 SuspFrnt_L_Prev 1;
BA_ "U_U611_U625_MY20_Gas_Tx" SG_ 570 SuspFrnt_L_Prev 1;
BA_ "U_U611_U625_MY20_Diesel_Tx" SG_ 570 SuspFrnt_L_Prev 1;
BA_ "U_C519_MY18_5_Gas_Tx" SG_ 570 SuspFrnt_L_Prev 1;
BA_ "U_C519_MY18_5_Diesel_Tx" SG_ 570 SuspFrnt_L_Prev 1;
BA_ "U_CX482_CX483_MY20_Hev_Rx" SG_ 570 SuspFrnt_L_Prev 1;
BA_ "U_CX482_CX483_MY20_Gas_Rx" SG_ 570 SuspFrnt_L_Prev 1;
BA_ "U_CX482_CX483_MY20_Diesel_Rx" SG_ 570 SuspFrnt_L_Prev 1;
BA_ "U_U611_U625_MY20_Hev_Rx" SG_ 570 SuspFrnt_L_Prev 1;
BA_ "U_U611_U625_MY20_Gas_Rx" SG_ 570 SuspFrnt_L_Prev 1;
BA_ "U_U611_U625_MY20_Diesel_Rx" SG_ 570 SuspFrnt_L_Prev 1;
BA_ "U_C519_MY18_5_Gas_Rx" SG_ 570 SuspFrnt_L_Prev 1;
BA_ "U_C519_MY18_5_Diesel_Rx" SG_ 570 SuspFrnt_L_Prev 1;
BA_ "GenSigStartValue" SG_ 570 SuspFrnt_L_Prev 511;
BA_ "U_U611_U625_MY20_Phev_Tx" SG_ 570 SuspFrnt_L_Actl 1;
BA_ "U_U611_U625_MY20_Hev_Tx" SG_ 570 SuspFrnt_L_Actl 1;
BA_ "U_U611_U625_MY20_Gas_Tx" SG_ 570 SuspFrnt_L_Actl 1;
BA_ "U_U611_U625_MY20_Diesel_Tx" SG_ 570 SuspFrnt_L_Actl 1;
BA_ "U_C519_MY18_5_Gas_Tx" SG_ 570 SuspFrnt_L_Actl 1;
BA_ "U_C519_MY18_5_Diesel_Tx" SG_ 570 SuspFrnt_L_Actl 1;
BA_ "U_CX482_CX483_MY20_Hev_Rx" SG_ 570 SuspFrnt_L_Actl 1;
BA_ "U_CX482_CX483_MY20_Gas_Rx" SG_ 570 SuspFrnt_L_Actl 1;
BA_ "U_CX482_CX483_MY20_Diesel_Rx" SG_ 570 SuspFrnt_L_Actl 1;
BA_ "U_U611_U625_MY20_Hev_Rx" SG_ 570 SuspFrnt_L_Actl 1;
BA_ "U_U611_U625_MY20_Gas_Rx" SG_ 570 SuspFrnt_L_Actl 1;
BA_ "U_U611_U625_MY20_Diesel_Rx" SG_ 570 SuspFrnt_L_Actl 1;
BA_ "U_C519_MY18_5_Gas_Rx" SG_ 570 SuspFrnt_L_Actl 1;
BA_ "U_C519_MY18_5_Diesel_Rx" SG_ 570 SuspFrnt_L_Actl 1;
BA_ "GenSigStartValue" SG_ 570 SuspFrnt_L_Actl 511;
BA_ "GenSigSendType" SG_ 76 PsngrFmidDetct_D_Actl 3;
BA_ "GenSigStartValue" SG_ 76 PsngrFmidDetct_D_Actl 3;
BA_ "U_C490_MY18_Tx" SG_ 76 FirstRowBuckleMid 1;
BA_ "GenSigSendType" SG_ 76 FirstRowBuckleMid 3;
BA_ "GenSigStartValue" SG_ 76 FirstRowBuckleMid 3;
BA_ "CrossOver_InfoCAN" SG_ 76 FirstRowBuckleMid 1;
BA_ "U_U611_U625_MY20_Hev_Tx" SG_ 76 ThirdRowBucklePsngr 1;
BA_ "U_U611_U625_MY20_Gas_Tx" SG_ 76 ThirdRowBucklePsngr 1;
BA_ "U_U611_U625_MY20_Diesel_Tx" SG_ 76 ThirdRowBucklePsngr 1;
BA_ "GenSigSendType" SG_ 76 ThirdRowBucklePsngr 3;
BA_ "GenSigStartValue" SG_ 76 ThirdRowBucklePsngr 3;
BA_ "CrossOver_InfoCAN" SG_ 76 ThirdRowBucklePsngr 1;
BA_ "U_U611_U625_MY20_Hev_Tx" SG_ 76 ThirdRowBuckleMid 1;
BA_ "U_U611_U625_MY20_Gas_Tx" SG_ 76 ThirdRowBuckleMid 1;
BA_ "U_U611_U625_MY20_Diesel_Tx" SG_ 76 ThirdRowBuckleMid 1;
BA_ "GenSigSendType" SG_ 76 ThirdRowBuckleMid 3;
BA_ "GenSigStartValue" SG_ 76 ThirdRowBuckleMid 3;
BA_ "CrossOver_InfoCAN" SG_ 76 ThirdRowBuckleMid 1;
BA_ "U_U611_U625_MY20_Hev_Tx" SG_ 76 ThirdRowBuckleDriver 1;
BA_ "U_U611_U625_MY20_Gas_Tx" SG_ 76 ThirdRowBuckleDriver 1;
BA_ "U_U611_U625_MY20_Diesel_Tx" SG_ 76 ThirdRowBuckleDriver 1;
BA_ "GenSigSendType" SG_ 76 ThirdRowBuckleDriver 3;
BA_ "GenSigStartValue" SG_ 76 ThirdRowBuckleDriver 3;
BA_ "CrossOver_InfoCAN" SG_ 76 ThirdRowBuckleDriver 1;
BA_ "U_CX482_CX483_MY20_Hev_Tx" SG_ 76 SecondRowBucklePsngr 1;
BA_ "U_CX482_CX483_MY20_Gas_Tx" SG_ 76 SecondRowBucklePsngr 1;
BA_ "U_CX482_CX483_MY20_Diesel_Tx" SG_ 76 SecondRowBucklePsngr 1;
BA_ "U_U611_U625_MY20_Hev_Tx" SG_ 76 SecondRowBucklePsngr 1;
BA_ "U_U611_U625_MY20_Gas_Tx" SG_ 76 SecondRowBucklePsngr 1;
BA_ "U_U611_U625_MY20_Diesel_Tx" SG_ 76 SecondRowBucklePsngr 1;
BA_ "U_B500_MY18_Diesel_Tx" SG_ 76 SecondRowBucklePsngr 1;
BA_ "U_B500_MY18_Gas_Tx" SG_ 76 SecondRowBucklePsngr 1;
BA_ "U_C490_MY18_Tx" SG_ 76 SecondRowBucklePsngr 1;
BA_ "U_C519_MY18_5_Gas_Tx" SG_ 76 SecondRowBucklePsngr 1;
BA_ "U_C519_MY18_5_Diesel_Tx" SG_ 76 SecondRowBucklePsngr 1;
BA_ "U_B479_MY17_Diesel_Tx" SG_ 76 SecondRowBucklePsngr 1;
BA_ "U_B479_MY17_Gas_Tx" SG_ 76 SecondRowBucklePsngr 1;
BA_ "GenSigSendType" SG_ 76 SecondRowBucklePsngr 3;
BA_ "GenSigStartValue" SG_ 76 SecondRowBucklePsngr 3;
BA_ "CrossOver_InfoCAN" SG_ 76 SecondRowBucklePsngr 1;
BA_ "U_CX482_CX483_MY20_Hev_Tx" SG_ 76 SecondRowBuckleMid 1;
BA_ "U_CX482_CX483_MY20_Gas_Tx" SG_ 76 SecondRowBuckleMid 1;
BA_ "U_CX482_CX483_MY20_Diesel_Tx" SG_ 76 SecondRowBuckleMid 1;
BA_ "U_U611_U625_MY20_Hev_Tx" SG_ 76 SecondRowBuckleMid 1;
BA_ "U_U611_U625_MY20_Gas_Tx" SG_ 76 SecondRowBuckleMid 1;
BA_ "U_U611_U625_MY20_Diesel_Tx" SG_ 76 SecondRowBuckleMid 1;
BA_ "U_C519_MY18_5_Gas_Tx" SG_ 76 SecondRowBuckleMid 1;
BA_ "U_C519_MY18_5_Diesel_Tx" SG_ 76 SecondRowBuckleMid 1;
BA_ "U_B479_MY17_Diesel_Tx" SG_ 76 SecondRowBuckleMid 1;
BA_ "U_B479_MY17_Gas_Tx" SG_ 76 SecondRowBuckleMid 1;
BA_ "GenSigSendType" SG_ 76 SecondRowBuckleMid 3;
BA_ "GenSigStartValue" SG_ 76 SecondRowBuckleMid 3;
BA_ "CrossOver_InfoCAN" SG_ 76 SecondRowBuckleMid 1;
BA_ "U_CX482_CX483_MY20_Hev_Tx" SG_ 76 SecondRowBuckleDriver 1;
BA_ "U_CX482_CX483_MY20_Gas_Tx" SG_ 76 SecondRowBuckleDriver 1;
BA_ "U_CX482_CX483_MY20_Diesel_Tx" SG_ 76 SecondRowBuckleDriver 1;
BA_ "U_U611_U625_MY20_Hev_Tx" SG_ 76 SecondRowBuckleDriver 1;
BA_ "U_U611_U625_MY20_Gas_Tx" SG_ 76 SecondRowBuckleDriver 1;
BA_ "U_U611_U625_MY20_Diesel_Tx" SG_ 76 SecondRowBuckleDriver 1;
BA_ "U_B500_MY18_Diesel_Tx" SG_ 76 SecondRowBuckleDriver 1;
BA_ "U_B500_MY18_Gas_Tx" SG_ 76 SecondRowBuckleDriver 1;
BA_ "U_C490_MY18_Tx" SG_ 76 SecondRowBuckleDriver 1;
BA_ "U_C519_MY18_5_Gas_Tx" SG_ 76 SecondRowBuckleDriver 1;
BA_ "U_C519_MY18_5_Diesel_Tx" SG_ 76 SecondRowBuckleDriver 1;
BA_ "U_B479_MY17_Diesel_Tx" SG_ 76 SecondRowBuckleDriver 1;
BA_ "U_B479_MY17_Gas_Tx" SG_ 76 SecondRowBuckleDriver 1;
BA_ "GenSigSendType" SG_ 76 SecondRowBuckleDriver 3;
BA_ "GenSigStartValue" SG_ 76 SecondRowBuckleDriver 3;
BA_ "CrossOver_InfoCAN" SG_ 76 SecondRowBuckleDriver 1;
BA_ "U_CX482_CX483_MY20_Hev_Tx" SG_ 76 FirstRowBuckleDriver 1;
BA_ "U_CX482_CX483_MY20_Gas_Tx" SG_ 76 FirstRowBuckleDriver 1;
BA_ "U_CX482_CX483_MY20_Diesel_Tx" SG_ 76 FirstRowBuckleDriver 1;
BA_ "U_U611_U625_MY20_Hev_Tx" SG_ 76 FirstRowBuckleDriver 1;
BA_ "U_U611_U625_MY20_Gas_Tx" SG_ 76 FirstRowBuckleDriver 1;
BA_ "U_U611_U625_MY20_Diesel_Tx" SG_ 76 FirstRowBuckleDriver 1;
BA_ "U_B500_MY18_Diesel_Tx" SG_ 76 FirstRowBuckleDriver 1;
BA_ "U_B500_MY18_Gas_Tx" SG_ 76 FirstRowBuckleDriver 1;
BA_ "U_C490_MY18_Tx" SG_ 76 FirstRowBuckleDriver 1;
BA_ "U_B562_MY18_Gas_Tx" SG_ 76 FirstRowBuckleDriver 1;
BA_ "U_C519_MY18_5_Gas_Tx" SG_ 76 FirstRowBuckleDriver 1;
BA_ "U_C519_MY18_5_Diesel_Tx" SG_ 76 FirstRowBuckleDriver 1;
BA_ "U_B515_MCA_MY17_Gas_Tx" SG_ 76 FirstRowBuckleDriver 1;
BA_ "U_B515_MCA_MY17_Diesel_Tx" SG_ 76 FirstRowBuckleDriver 1;
BA_ "U_B479_MY17_Diesel_Tx" SG_ 76 FirstRowBuckleDriver 1;
BA_ "U_B479_MY17_Gas_Tx" SG_ 76 FirstRowBuckleDriver 1;
BA_ "U_U611_U625_MY20_Phev_Rx" SG_ 76 FirstRowBuckleDriver 1;
BA_ "U_CX482_CX483_MY20_Hev_Rx" SG_ 76 FirstRowBuckleDriver 1;
BA_ "U_CX482_CX483_MY20_Gas_Rx" SG_ 76 FirstRowBuckleDriver 1;
BA_ "U_CX482_CX483_MY20_Diesel_Rx" SG_ 76 FirstRowBuckleDriver 1;
BA_ "U_U611_U625_MY20_Hev_Rx" SG_ 76 FirstRowBuckleDriver 1;
BA_ "U_U611_U625_MY20_Gas_Rx" SG_ 76 FirstRowBuckleDriver 1;
BA_ "U_U611_U625_MY20_Diesel_Rx" SG_ 76 FirstRowBuckleDriver 1;
BA_ "U_B515_MCA_MY17_Gas_Rx" SG_ 76 FirstRowBuckleDriver 1;
BA_ "U_B515_MCA_MY17_Diesel_Rx" SG_ 76 FirstRowBuckleDriver 1;
BA_ "U_C519_MY18_5_Gas_Rx" SG_ 76 FirstRowBuckleDriver 1;
BA_ "U_C519_MY18_5_Diesel_Rx" SG_ 76 FirstRowBuckleDriver 1;
BA_ "U_B479_MY17_Diesel_Rx" SG_ 76 FirstRowBuckleDriver 1;
BA_ "U_B479_MY17_Gas_Rx" SG_ 76 FirstRowBuckleDriver 1;
BA_ "GenSigSendType" SG_ 76 FirstRowBuckleDriver 3;
BA_ "GenSigStartValue" SG_ 76 FirstRowBuckleDriver 3;
BA_ "CrossOver_InfoCAN" SG_ 76 FirstRowBuckleDriver 1;
BA_ "U_CX482_CX483_MY20_Hev_Tx" SG_ 76 RILReq 1;
BA_ "U_CX482_CX483_MY20_Gas_Tx" SG_ 76 RILReq 1;
BA_ "U_CX482_CX483_MY20_Diesel_Tx" SG_ 76 RILReq 1;
BA_ "U_U611_U625_MY20_Hev_Tx" SG_ 76 RILReq 1;
BA_ "U_U611_U625_MY20_Gas_Tx" SG_ 76 RILReq 1;
BA_ "U_U611_U625_MY20_Diesel_Tx" SG_ 76 RILReq 1;
BA_ "U_B500_MY18_Diesel_Tx" SG_ 76 RILReq 1;
BA_ "U_B500_MY18_Gas_Tx" SG_ 76 RILReq 1;
BA_ "U_C490_MY18_Tx" SG_ 76 RILReq 1;
BA_ "U_B562_MY18_Gas_Tx" SG_ 76 RILReq 1;
BA_ "U_C519_MY18_5_Gas_Tx" SG_ 76 RILReq 1;
BA_ "U_C519_MY18_5_Diesel_Tx" SG_ 76 RILReq 1;
BA_ "U_B515_MCA_MY17_Gas_Tx" SG_ 76 RILReq 1;
BA_ "U_B515_MCA_MY17_Diesel_Tx" SG_ 76 RILReq 1;
BA_ "U_B479_MY17_Diesel_Tx" SG_ 76 RILReq 1;
BA_ "U_B479_MY17_Gas_Tx" SG_ 76 RILReq 1;
BA_ "GenSigSendType" SG_ 76 RILReq 3;
BA_ "CrossOver_InfoCAN" SG_ 76 RILReq 1;
BA_ "U_CX482_CX483_MY20_Hev_Tx" SG_ 76 FirstRowBucklePsngr 1;
BA_ "U_CX482_CX483_MY20_Gas_Tx" SG_ 76 FirstRowBucklePsngr 1;
BA_ "U_CX482_CX483_MY20_Diesel_Tx" SG_ 76 FirstRowBucklePsngr 1;
BA_ "U_U611_U625_MY20_Hev_Tx" SG_ 76 FirstRowBucklePsngr 1;
BA_ "U_U611_U625_MY20_Gas_Tx" SG_ 76 FirstRowBucklePsngr 1;
BA_ "U_U611_U625_MY20_Diesel_Tx" SG_ 76 FirstRowBucklePsngr 1;
BA_ "U_B500_MY18_Diesel_Tx" SG_ 76 FirstRowBucklePsngr 1;
BA_ "U_B500_MY18_Gas_Tx" SG_ 76 FirstRowBucklePsngr 1;
BA_ "U_C490_MY18_Tx" SG_ 76 FirstRowBucklePsngr 1;
BA_ "U_B562_MY18_Gas_Tx" SG_ 76 FirstRowBucklePsngr 1;
BA_ "U_C519_MY18_5_Gas_Tx" SG_ 76 FirstRowBucklePsngr 1;
BA_ "U_C519_MY18_5_Diesel_Tx" SG_ 76 FirstRowBucklePsngr 1;
BA_ "U_B515_MCA_MY17_Gas_Tx" SG_ 76 FirstRowBucklePsngr 1;
BA_ "U_B515_MCA_MY17_Diesel_Tx" SG_ 76 FirstRowBucklePsngr 1;
BA_ "U_B479_MY17_Diesel_Tx" SG_ 76 FirstRowBucklePsngr 1;
BA_ "U_B479_MY17_Gas_Tx" SG_ 76 FirstRowBucklePsngr 1;
BA_ "U_U611_U625_MY20_Phev_Rx" SG_ 76 FirstRowBucklePsngr 1;
BA_ "U_CX482_CX483_MY20_Hev_Rx" SG_ 76 FirstRowBucklePsngr 1;
BA_ "U_CX482_CX483_MY20_Gas_Rx" SG_ 76 FirstRowBucklePsngr 1;
BA_ "U_CX482_CX483_MY20_Diesel_Rx" SG_ 76 FirstRowBucklePsngr 1;
BA_ "U_U611_U625_MY20_Hev_Rx" SG_ 76 FirstRowBucklePsngr 1;
BA_ "U_U611_U625_MY20_Gas_Rx" SG_ 76 FirstRowBucklePsngr 1;
BA_ "U_U611_U625_MY20_Diesel_Rx" SG_ 76 FirstRowBucklePsngr 1;
BA_ "U_C519_MY18_5_Gas_Rx" SG_ 76 FirstRowBucklePsngr 1;
BA_ "U_C519_MY18_5_Diesel_Rx" SG_ 76 FirstRowBucklePsngr 1;
BA_ "U_B515_MCA_MY17_Gas_Rx" SG_ 76 FirstRowBucklePsngr 1;
BA_ "U_B515_MCA_MY17_Diesel_Rx" SG_ 76 FirstRowBucklePsngr 1;
BA_ "U_B479_MY17_Diesel_Rx" SG_ 76 FirstRowBucklePsngr 1;
BA_ "U_B479_MY17_Gas_Rx" SG_ 76 FirstRowBucklePsngr 1;
BA_ "GenSigSendType" SG_ 76 FirstRowBucklePsngr 3;
BA_ "GenSigStartValue" SG_ 76 FirstRowBucklePsngr 3;
BA_ "CrossOver_InfoCAN" SG_ 76 FirstRowBucklePsngr 1;
BA_ "U_CX482_CX483_MY20_Hev_Tx" SG_ 76 RstrnImpactEvntStatus 1;
BA_ "U_CX482_CX483_MY20_Gas_Tx" SG_ 76 RstrnImpactEvntStatus 1;
BA_ "U_CX482_CX483_MY20_Diesel_Tx" SG_ 76 RstrnImpactEvntStatus 1;
BA_ "U_U611_U625_MY20_Hev_Tx" SG_ 76 RstrnImpactEvntStatus 1;
BA_ "U_U611_U625_MY20_Gas_Tx" SG_ 76 RstrnImpactEvntStatus 1;
BA_ "U_U611_U625_MY20_Diesel_Tx" SG_ 76 RstrnImpactEvntStatus 1;
BA_ "U_B500_MY18_Diesel_Tx" SG_ 76 RstrnImpactEvntStatus 1;
BA_ "U_B500_MY18_Gas_Tx" SG_ 76 RstrnImpactEvntStatus 1;
BA_ "U_C490_MY18_Tx" SG_ 76 RstrnImpactEvntStatus 1;
BA_ "U_B562_MY18_Gas_Tx" SG_ 76 RstrnImpactEvntStatus 1;
BA_ "U_C519_MY18_5_Gas_Tx" SG_ 76 RstrnImpactEvntStatus 1;
BA_ "U_C519_MY18_5_Diesel_Tx" SG_ 76 RstrnImpactEvntStatus 1;
BA_ "U_B515_MCA_MY17_Gas_Tx" SG_ 76 RstrnImpactEvntStatus 1;
BA_ "U_B515_MCA_MY17_Diesel_Tx" SG_ 76 RstrnImpactEvntStatus 1;
BA_ "U_B479_MY17_Diesel_Tx" SG_ 76 RstrnImpactEvntStatus 1;
BA_ "U_B479_MY17_Gas_Tx" SG_ 76 RstrnImpactEvntStatus 1;
BA_ "U_B500_MY18_Diesel_Rx" SG_ 76 RstrnImpactEvntStatus 1;
BA_ "U_B500_MY18_Gas_Rx" SG_ 76 RstrnImpactEvntStatus 1;
BA_ "U_U611_U625_MY20_Phev_Rx" SG_ 76 RstrnImpactEvntStatus 1;
BA_ "U_CX482_CX483_MY20_Hev_Rx" SG_ 76 RstrnImpactEvntStatus 1;
BA_ "U_CX482_CX483_MY20_Gas_Rx" SG_ 76 RstrnImpactEvntStatus 1;
BA_ "U_CX482_CX483_MY20_Diesel_Rx" SG_ 76 RstrnImpactEvntStatus 1;
BA_ "U_U611_U625_MY20_Hev_Rx" SG_ 76 RstrnImpactEvntStatus 1;
BA_ "U_U611_U625_MY20_Gas_Rx" SG_ 76 RstrnImpactEvntStatus 1;
BA_ "U_U611_U625_MY20_Diesel_Rx" SG_ 76 RstrnImpactEvntStatus 1;
BA_ "U_B515_MCA_MY17_Gas_Rx" SG_ 76 RstrnImpactEvntStatus 1;
BA_ "U_B515_MCA_MY17_Diesel_Rx" SG_ 76 RstrnImpactEvntStatus 1;
BA_ "U_C519_MY18_5_Gas_Rx" SG_ 76 RstrnImpactEvntStatus 1;
BA_ "U_C519_MY18_5_Diesel_Rx" SG_ 76 RstrnImpactEvntStatus 1;
BA_ "U_B479_MY17_Diesel_Rx" SG_ 76 RstrnImpactEvntStatus 1;
BA_ "U_B479_MY17_Gas_Rx" SG_ 76 RstrnImpactEvntStatus 1;
BA_ "GenSigSendType" SG_ 76 RstrnImpactEvntStatus 3;
BA_ "CrossOver_InfoCAN" SG_ 76 RstrnImpactEvntStatus 1;
BA_ "WakeupSignal" SG_ 76 RstrnImpactEvntStatus 1;
BA_ "U_CX482_CX483_MY20_Hev_Tx" SG_ 76 PsngrFrntDetct_D_Actl 1;
BA_ "U_CX482_CX483_MY20_Gas_Tx" SG_ 76 PsngrFrntDetct_D_Actl 1;
BA_ "U_CX482_CX483_MY20_Diesel_Tx" SG_ 76 PsngrFrntDetct_D_Actl 1;
BA_ "U_U611_U625_MY20_Hev_Tx" SG_ 76 PsngrFrntDetct_D_Actl 1;
BA_ "U_U611_U625_MY20_Gas_Tx" SG_ 76 PsngrFrntDetct_D_Actl 1;
BA_ "U_U611_U625_MY20_Diesel_Tx" SG_ 76 PsngrFrntDetct_D_Actl 1;
BA_ "U_B500_MY18_Diesel_Tx" SG_ 76 PsngrFrntDetct_D_Actl 1;
BA_ "U_B500_MY18_Gas_Tx" SG_ 76 PsngrFrntDetct_D_Actl 1;
BA_ "U_C490_MY18_Tx" SG_ 76 PsngrFrntDetct_D_Actl 1;
BA_ "U_B562_MY18_Gas_Tx" SG_ 76 PsngrFrntDetct_D_Actl 1;
BA_ "U_C519_MY18_5_Gas_Tx" SG_ 76 PsngrFrntDetct_D_Actl 1;
BA_ "U_C519_MY18_5_Diesel_Tx" SG_ 76 PsngrFrntDetct_D_Actl 1;
BA_ "U_B515_MCA_MY17_Gas_Tx" SG_ 76 PsngrFrntDetct_D_Actl 1;
BA_ "U_B515_MCA_MY17_Diesel_Tx" SG_ 76 PsngrFrntDetct_D_Actl 1;
BA_ "U_B479_MY17_Diesel_Tx" SG_ 76 PsngrFrntDetct_D_Actl 1;
BA_ "U_B479_MY17_Gas_Tx" SG_ 76 PsngrFrntDetct_D_Actl 1;
BA_ "GenSigSendType" SG_ 76 PsngrFrntDetct_D_Actl 3;
BA_ "GenSigStartValue" SG_ 76 PsngrFrntDetct_D_Actl 3;
BA_ "CrossOver_InfoCAN" SG_ 76 PsngrFrntDetct_D_Actl 1;
BA_ "U_CX482_CX483_MY20_Hev_Tx" SG_ 76 EDRTriggerEvntSync 1;
BA_ "U_CX482_CX483_MY20_Gas_Tx" SG_ 76 EDRTriggerEvntSync 1;
BA_ "U_CX482_CX483_MY20_Diesel_Tx" SG_ 76 EDRTriggerEvntSync 1;
BA_ "U_U611_U625_MY20_Hev_Tx" SG_ 76 EDRTriggerEvntSync 1;
BA_ "U_U611_U625_MY20_Gas_Tx" SG_ 76 EDRTriggerEvntSync 1;
BA_ "U_U611_U625_MY20_Diesel_Tx" SG_ 76 EDRTriggerEvntSync 1;
BA_ "U_B500_MY18_Diesel_Tx" SG_ 76 EDRTriggerEvntSync 1;
BA_ "U_B500_MY18_Gas_Tx" SG_ 76 EDRTriggerEvntSync 1;
BA_ "U_C490_MY18_Tx" SG_ 76 EDRTriggerEvntSync 1;
BA_ "U_B562_MY18_Gas_Tx" SG_ 76 EDRTriggerEvntSync 1;
BA_ "U_C519_MY18_5_Gas_Tx" SG_ 76 EDRTriggerEvntSync 1;
BA_ "U_C519_MY18_5_Diesel_Tx" SG_ 76 EDRTriggerEvntSync 1;
BA_ "U_B515_MCA_MY17_Gas_Tx" SG_ 76 EDRTriggerEvntSync 1;
BA_ "U_B515_MCA_MY17_Diesel_Tx" SG_ 76 EDRTriggerEvntSync 1;
BA_ "U_B479_MY17_Diesel_Tx" SG_ 76 EDRTriggerEvntSync 1;
BA_ "U_B479_MY17_Gas_Tx" SG_ 76 EDRTriggerEvntSync 1;
BA_ "U_CX482_CX483_MY20_Hev_Rx" SG_ 76 EDRTriggerEvntSync 1;
BA_ "U_CX482_CX483_MY20_Gas_Rx" SG_ 76 EDRTriggerEvntSync 1;
BA_ "U_CX482_CX483_MY20_Diesel_Rx" SG_ 76 EDRTriggerEvntSync 1;
BA_ "U_U611_U625_MY20_Hev_Rx" SG_ 76 EDRTriggerEvntSync 1;
BA_ "U_U611_U625_MY20_Gas_Rx" SG_ 76 EDRTriggerEvntSync 1;
BA_ "U_U611_U625_MY20_Diesel_Rx" SG_ 76 EDRTriggerEvntSync 1;
BA_ "U_C519_MY18_5_Gas_Rx" SG_ 76 EDRTriggerEvntSync 1;
BA_ "U_C519_MY18_5_Diesel_Rx" SG_ 76 EDRTriggerEvntSync 1;
BA_ "U_B479_MY17_Diesel_Rx" SG_ 76 EDRTriggerEvntSync 1;
BA_ "U_B479_MY17_Gas_Rx" SG_ 76 EDRTriggerEvntSync 1;
BA_ "GenSigSendType" SG_ 76 EDRTriggerEvntSync 3;
BA_ "CrossOver_InfoCAN" SG_ 76 EDRTriggerEvntSync 1;
BA_ "U_U611_U625_MY20_Hev_Tx" SG_ 76 PassRstrnInd_Req 1;
BA_ "U_U611_U625_MY20_Gas_Tx" SG_ 76 PassRstrnInd_Req 1;
BA_ "U_U611_U625_MY20_Diesel_Tx" SG_ 76 PassRstrnInd_Req 1;
BA_ "U_B562_MY18_Gas_Tx" SG_ 76 PassRstrnInd_Req 1;
BA_ "GenSigSendType" SG_ 76 PassRstrnInd_Req 3;
BA_ "GenSigStartValue" SG_ 76 PassRstrnInd_Req 3;
BA_ "CrossOver_InfoCAN" SG_ 76 PassRstrnInd_Req 1;
BA_ "GenSigStartValue" SG_ 120 TrlrAidCtl_U_RqDrv 4094;
BA_ "U_U611_U625_MY20_Hev_Rx" SG_ 120 BpedDrvMsgTxt_B_Dsply_UB 1;
BA_ "U_U611_U625_MY20_Gas_Rx" SG_ 120 BpedDrvMsgTxt_B_Dsply_UB 1;
BA_ "U_U611_U625_MY20_Diesel_Rx" SG_ 120 BpedDrvMsgTxt_B_Dsply_UB 1;
BA_ "U_U611_U625_MY20_Hev_Rx" SG_ 120 BpedDrvMsgTxt_B_Dsply 1;
BA_ "U_U611_U625_MY20_Gas_Rx" SG_ 120 BpedDrvMsgTxt_B_Dsply 1;
BA_ "U_U611_U625_MY20_Diesel_Rx" SG_ 120 BpedDrvMsgTxt_B_Dsply 1;
BA_ "U_U611_U625_MY20_Hev_Rx" SG_ 120 PassRstrnInd_Stat_UB 1;
BA_ "U_U611_U625_MY20_Gas_Rx" SG_ 120 PassRstrnInd_Stat_UB 1;
BA_ "U_U611_U625_MY20_Diesel_Rx" SG_ 120 PassRstrnInd_Stat_UB 1;
BA_ "U_C490_MY18_Rx" SG_ 120 PassRstrnInd_Stat_UB 1;
BA_ "U_B562_MY18_Gas_Rx" SG_ 120 PassRstrnInd_Stat_UB 1;
BA_ "U_U611_U625_MY20_Hev_Rx" SG_ 120 PassRstrnInd_Stat 1;
BA_ "U_U611_U625_MY20_Gas_Rx" SG_ 120 PassRstrnInd_Stat 1;
BA_ "U_U611_U625_MY20_Diesel_Rx" SG_ 120 PassRstrnInd_Stat 1;
BA_ "U_C490_MY18_Rx" SG_ 120 PassRstrnInd_Stat 1;
BA_ "U_B562_MY18_Gas_Rx" SG_ 120 PassRstrnInd_Stat 1;
BA_ "CrossOver_InfoCAN" SG_ 120 HtrnWarnLamp_B_Dsply_UB 1;
BA_ "U_CX482_CX483_MY20_Hev_Rx" SG_ 120 HtrnWarnLamp_B_Dsply 1;
BA_ "U_CX482_CX483_MY20_Gas_Rx" SG_ 120 HtrnWarnLamp_B_Dsply 1;
BA_ "U_CX482_CX483_MY20_Diesel_Rx" SG_ 120 HtrnWarnLamp_B_Dsply 1;
BA_ "U_C490_MY18_Rx" SG_ 120 HtrnWarnLamp_B_Dsply 1;
BA_ "U_C519_MY18_5_Gas_Rx" SG_ 120 HtrnWarnLamp_B_Dsply 1;
BA_ "U_C519_MY18_5_Diesel_Rx" SG_ 120 HtrnWarnLamp_B_Dsply 1;
BA_ "CrossOver_InfoCAN" SG_ 120 HtrnWarnLamp_B_Dsply 1;
BA_ "U_CX482_CX483_MY20_Hev_Rx" SG_ 120 ECMMILRequest_UB 1;
BA_ "U_CX482_CX483_MY20_Gas_Rx" SG_ 120 ECMMILRequest_UB 1;
BA_ "U_CX482_CX483_MY20_Diesel_Rx" SG_ 120 ECMMILRequest_UB 1;
BA_ "U_U611_U625_MY20_Hev_Rx" SG_ 120 ECMMILRequest_UB 1;
BA_ "U_U611_U625_MY20_Gas_Rx" SG_ 120 ECMMILRequest_UB 1;
BA_ "U_U611_U625_MY20_Diesel_Rx" SG_ 120 ECMMILRequest_UB 1;
BA_ "U_B500_MY18_Diesel_Rx" SG_ 120 ECMMILRequest_UB 1;
BA_ "U_B500_MY18_Gas_Rx" SG_ 120 ECMMILRequest_UB 1;
BA_ "U_C490_MY18_Rx" SG_ 120 ECMMILRequest_UB 1;
BA_ "U_B562_MY18_Gas_Rx" SG_ 120 ECMMILRequest_UB 1;
BA_ "U_C519_MY18_5_Gas_Rx" SG_ 120 ECMMILRequest_UB 1;
BA_ "U_C519_MY18_5_Diesel_Rx" SG_ 120 ECMMILRequest_UB 1;
BA_ "U_B515_MCA_MY17_Gas_Rx" SG_ 120 ECMMILRequest_UB 1;
BA_ "U_B515_MCA_MY17_Diesel_Rx" SG_ 120 ECMMILRequest_UB 1;
BA_ "U_B479_MY17_Diesel_Rx" SG_ 120 ECMMILRequest_UB 1;
BA_ "U_B479_MY17_Gas_Rx" SG_ 120 ECMMILRequest_UB 1;
BA_ "U_CX482_CX483_MY20_Hev_Rx" SG_ 120 ECMMILRequest 1;
BA_ "U_CX482_CX483_MY20_Gas_Rx" SG_ 120 ECMMILRequest 1;
BA_ "U_CX482_CX483_MY20_Diesel_Rx" SG_ 120 ECMMILRequest 1;
BA_ "U_U611_U625_MY20_Hev_Rx" SG_ 120 ECMMILRequest 1;
BA_ "U_U611_U625_MY20_Gas_Rx" SG_ 120 ECMMILRequest 1;
BA_ "U_U611_U625_MY20_Diesel_Rx" SG_ 120 ECMMILRequest 1;
BA_ "U_B500_MY18_Diesel_Rx" SG_ 120 ECMMILRequest 1;
BA_ "U_B500_MY18_Gas_Rx" SG_ 120 ECMMILRequest 1;
BA_ "U_C490_MY18_Rx" SG_ 120 ECMMILRequest 1;
BA_ "U_B562_MY18_Gas_Rx" SG_ 120 ECMMILRequest 1;
BA_ "U_C519_MY18_5_Gas_Rx" SG_ 120 ECMMILRequest 1;
BA_ "U_C519_MY18_5_Diesel_Rx" SG_ 120 ECMMILRequest 1;
BA_ "U_B515_MCA_MY17_Gas_Rx" SG_ 120 ECMMILRequest 1;
BA_ "U_B515_MCA_MY17_Diesel_Rx" SG_ 120 ECMMILRequest 1;
BA_ "U_B479_MY17_Diesel_Rx" SG_ 120 ECMMILRequest 1;
BA_ "U_B479_MY17_Gas_Rx" SG_ 120 ECMMILRequest 1;
BA_ "CrossOver_InfoCAN" SG_ 120 ECMMILRequest 1;
BA_ "U_U611_U625_MY20_Phev_Rx" SG_ 120 TrnIpcDsplyMde_D_Stat 1;
BA_ "U_CX482_CX483_MY20_Hev_Rx" SG_ 120 TrnIpcDsplyMde_D_Stat 1;
BA_ "U_CX482_CX483_MY20_Gas_Rx" SG_ 120 TrnIpcDsplyMde_D_Stat 1;
BA_ "U_CX482_CX483_MY20_Diesel_Rx" SG_ 120 TrnIpcDsplyMde_D_Stat 1;
BA_ "U_U611_U625_MY20_Hev_Rx" SG_ 120 TrnIpcDsplyMde_D_Stat 1;
BA_ "U_U611_U625_MY20_Gas_Rx" SG_ 120 TrnIpcDsplyMde_D_Stat 1;
BA_ "U_U611_U625_MY20_Diesel_Rx" SG_ 120 TrnIpcDsplyMde_D_Stat 1;
BA_ "U_C519_MY18_5_Gas_Rx" SG_ 120 TrnIpcDsplyMde_D_Stat 1;
BA_ "U_C519_MY18_5_Diesel_Rx" SG_ 120 TrnIpcDsplyMde_D_Stat 1;
BA_ "CrossOver_InfoCAN" SG_ 120 TrnIpcDsplyMde_D_Stat 1;
BA_ "WakeupSignal" SG_ 120 TrnIpcDsplyMde_D_Stat 1;
BA_ "U_U611_U625_MY20_Phev_Rx" SG_ 120 TrnIpcDsplyMde_D_Actl 1;
BA_ "U_CX482_CX483_MY20_Hev_Rx" SG_ 120 TrnIpcDsplyMde_D_Actl 1;
BA_ "U_CX482_CX483_MY20_Gas_Rx" SG_ 120 TrnIpcDsplyMde_D_Actl 1;
BA_ "U_CX482_CX483_MY20_Diesel_Rx" SG_ 120 TrnIpcDsplyMde_D_Actl 1;
BA_ "U_U611_U625_MY20_Hev_Rx" SG_ 120 TrnIpcDsplyMde_D_Actl 1;
BA_ "U_U611_U625_MY20_Gas_Rx" SG_ 120 TrnIpcDsplyMde_D_Actl 1;
BA_ "U_U611_U625_MY20_Diesel_Rx" SG_ 120 TrnIpcDsplyMde_D_Actl 1;
BA_ "U_C519_MY18_5_Gas_Rx" SG_ 120 TrnIpcDsplyMde_D_Actl 1;
BA_ "U_C519_MY18_5_Diesel_Rx" SG_ 120 TrnIpcDsplyMde_D_Actl 1;
BA_ "CrossOver_InfoCAN" SG_ 120 TrnIpcDsplyMde_D_Actl 1;
BA_ "WakeupSignal" SG_ 120 TrnIpcDsplyMde_D_Actl 1;
BA_ "U_CX482_CX483_MY20_Hev_Rx" SG_ 120 EngSrvcRqd_B_Rq 1;
BA_ "U_CX482_CX483_MY20_Gas_Rx" SG_ 120 EngSrvcRqd_B_Rq 1;
BA_ "U_CX482_CX483_MY20_Diesel_Rx" SG_ 120 EngSrvcRqd_B_Rq 1;
BA_ "U_U611_U625_MY20_Hev_Rx" SG_ 120 EngSrvcRqd_B_Rq 1;
BA_ "U_U611_U625_MY20_Gas_Rx" SG_ 120 EngSrvcRqd_B_Rq 1;
BA_ "U_U611_U625_MY20_Diesel_Rx" SG_ 120 EngSrvcRqd_B_Rq 1;
BA_ "U_B500_MY18_Diesel_Rx" SG_ 120 EngSrvcRqd_B_Rq 1;
BA_ "U_B500_MY18_Gas_Rx" SG_ 120 EngSrvcRqd_B_Rq 1;
BA_ "U_C490_MY18_Rx" SG_ 120 EngSrvcRqd_B_Rq 1;
BA_ "U_B562_MY18_Gas_Rx" SG_ 120 EngSrvcRqd_B_Rq 1;
BA_ "U_C519_MY18_5_Gas_Rx" SG_ 120 EngSrvcRqd_B_Rq 1;
BA_ "U_C519_MY18_5_Diesel_Rx" SG_ 120 EngSrvcRqd_B_Rq 1;
BA_ "U_B515_MCA_MY17_Gas_Rx" SG_ 120 EngSrvcRqd_B_Rq 1;
BA_ "U_B515_MCA_MY17_Diesel_Rx" SG_ 120 EngSrvcRqd_B_Rq 1;
BA_ "U_B479_MY17_Diesel_Rx" SG_ 120 EngSrvcRqd_B_Rq 1;
BA_ "U_B479_MY17_Gas_Rx" SG_ 120 EngSrvcRqd_B_Rq 1;
BA_ "CrossOver_InfoCAN" SG_ 120 EngSrvcRqd_B_Rq 1;
BA_ "U_CX482_CX483_MY20_Hev_Rx" SG_ 120 HtrnSrvcRqd_B_Dsply 1;
BA_ "U_CX482_CX483_MY20_Gas_Rx" SG_ 120 HtrnSrvcRqd_B_Dsply 1;
BA_ "U_CX482_CX483_MY20_Diesel_Rx" SG_ 120 HtrnSrvcRqd_B_Dsply 1;
BA_ "U_C519_MY18_5_Gas_Rx" SG_ 120 HtrnSrvcRqd_B_Dsply 1;
BA_ "U_C519_MY18_5_Diesel_Rx" SG_ 120 HtrnSrvcRqd_B_Dsply 1;
BA_ "CrossOver_InfoCAN" SG_ 120 HtrnSrvcRqd_B_Dsply 1;
BA_ "CrossOver_InfoCAN" SG_ 120 HtrnSrvcRqd_B_Dsply_UB 1;
BA_ "U_U611_U625_MY20_Phev_Rx" SG_ 120 TrnIpcDsplyMde_D_Stat_UB 1;
BA_ "U_CX482_CX483_MY20_Hev_Rx" SG_ 120 TrnIpcDsplyMde_D_Stat_UB 1;
BA_ "U_CX482_CX483_MY20_Gas_Rx" SG_ 120 TrnIpcDsplyMde_D_Stat_UB 1;
BA_ "U_CX482_CX483_MY20_Diesel_Rx" SG_ 120 TrnIpcDsplyMde_D_Stat_UB 1;
BA_ "U_U611_U625_MY20_Hev_Rx" SG_ 120 TrnIpcDsplyMde_D_Stat_UB 1;
BA_ "U_U611_U625_MY20_Gas_Rx" SG_ 120 TrnIpcDsplyMde_D_Stat_UB 1;
BA_ "U_U611_U625_MY20_Diesel_Rx" SG_ 120 TrnIpcDsplyMde_D_Stat_UB 1;
BA_ "U_C519_MY18_5_Gas_Rx" SG_ 120 TrnIpcDsplyMde_D_Stat_UB 1;
BA_ "U_C519_MY18_5_Diesel_Rx" SG_ 120 TrnIpcDsplyMde_D_Stat_UB 1;
BA_ "U_U611_U625_MY20_Phev_Rx" SG_ 120 TrnIpcDsplyMde_D_Actl_UB 1;
BA_ "U_CX482_CX483_MY20_Hev_Rx" SG_ 120 TrnIpcDsplyMde_D_Actl_UB 1;
BA_ "U_CX482_CX483_MY20_Gas_Rx" SG_ 120 TrnIpcDsplyMde_D_Actl_UB 1;
BA_ "U_CX482_CX483_MY20_Diesel_Rx" SG_ 120 TrnIpcDsplyMde_D_Actl_UB 1;
BA_ "U_U611_U625_MY20_Hev_Rx" SG_ 120 TrnIpcDsplyMde_D_Actl_UB 1;
BA_ "U_U611_U625_MY20_Gas_Rx" SG_ 120 TrnIpcDsplyMde_D_Actl_UB 1;
BA_ "U_U611_U625_MY20_Diesel_Rx" SG_ 120 TrnIpcDsplyMde_D_Actl_UB 1;
BA_ "U_C519_MY18_5_Gas_Rx" SG_ 120 TrnIpcDsplyMde_D_Actl_UB 1;
BA_ "U_C519_MY18_5_Diesel_Rx" SG_ 120 TrnIpcDsplyMde_D_Actl_UB 1;
BA_ "U_CX482_CX483_MY20_Hev_Tx" SG_ 1665 UUDTRCMResponse2 1;
BA_ "U_CX482_CX483_MY20_Gas_Tx" SG_ 1665 UUDTRCMResponse2 1;
BA_ "U_CX482_CX483_MY20_Diesel_Tx" SG_ 1665 UUDTRCMResponse2 1;
BA_ "U_U611_U625_MY20_Hev_Tx" SG_ 1665 UUDTRCMResponse2 1;
BA_ "U_U611_U625_MY20_Gas_Tx" SG_ 1665 UUDTRCMResponse2 1;
BA_ "U_U611_U625_MY20_Diesel_Tx" SG_ 1665 UUDTRCMResponse2 1;
BA_ "U_B500_MY18_Diesel_Tx" SG_ 1665 UUDTRCMResponse2 1;
BA_ "U_B500_MY18_Gas_Tx" SG_ 1665 UUDTRCMResponse2 1;
BA_ "U_C490_MY18_Tx" SG_ 1665 UUDTRCMResponse2 1;
BA_ "U_B562_MY18_Gas_Tx" SG_ 1665 UUDTRCMResponse2 1;
BA_ "U_C519_MY18_5_Gas_Tx" SG_ 1665 UUDTRCMResponse2 1;
BA_ "U_C519_MY18_5_Diesel_Tx" SG_ 1665 UUDTRCMResponse2 1;
BA_ "U_B515_MCA_MY17_Gas_Tx" SG_ 1665 UUDTRCMResponse2 1;
BA_ "U_B515_MCA_MY17_Diesel_Tx" SG_ 1665 UUDTRCMResponse2 1;
BA_ "U_B479_MY17_Diesel_Tx" SG_ 1665 UUDTRCMResponse2 1;
BA_ "U_B479_MY17_Gas_Tx" SG_ 1665 UUDTRCMResponse2 1;
BA_ "GenSigSendType" SG_ 1665 UUDTRCMResponse2 3;
BA_ "U_CX482_CX483_MY20_Hev_Tx" SG_ 2041 TesterPhysicalResPCU 1;
BA_ "U_CX482_CX483_MY20_Gas_Tx" SG_ 2041 TesterPhysicalResPCU 1;
BA_ "U_CX482_CX483_MY20_Diesel_Tx" SG_ 2041 TesterPhysicalResPCU 1;
BA_ "U_U611_U625_MY20_Hev_Tx" SG_ 2041 TesterPhysicalResPCU 1;
BA_ "U_U611_U625_MY20_Gas_Tx" SG_ 2041 TesterPhysicalResPCU 1;
BA_ "U_U611_U625_MY20_Diesel_Tx" SG_ 2041 TesterPhysicalResPCU 1;
BA_ "U_B500_MY18_Diesel_Tx" SG_ 2041 TesterPhysicalResPCU 1;
BA_ "U_B500_MY18_Gas_Tx" SG_ 2041 TesterPhysicalResPCU 1;
BA_ "U_C490_MY18_Tx" SG_ 2041 TesterPhysicalResPCU 1;
BA_ "U_B562_MY18_Gas_Tx" SG_ 2041 TesterPhysicalResPCU 1;
BA_ "U_C519_MY18_5_Gas_Tx" SG_ 2041 TesterPhysicalResPCU 1;
BA_ "U_C519_MY18_5_Diesel_Tx" SG_ 2041 TesterPhysicalResPCU 1;
BA_ "U_B515_MCA_MY17_Gas_Tx" SG_ 2041 TesterPhysicalResPCU 1;
BA_ "U_B515_MCA_MY17_Diesel_Tx" SG_ 2041 TesterPhysicalResPCU 1;
BA_ "U_B479_MY17_Diesel_Tx" SG_ 2041 TesterPhysicalResPCU 1;
BA_ "U_B479_MY17_Gas_Tx" SG_ 2041 TesterPhysicalResPCU 1;
BA_ "GenSigSendType" SG_ 2041 TesterPhysicalResPCU 3;
BA_ "U_U611_U625_MY20_Phev_Rx" SG_ 1438 GWM_GWOnBoardTester 1;
BA_ "U_CX482_CX483_MY20_Hev_Rx" SG_ 1438 GWM_GWOnBoardTester 1;
BA_ "U_CX482_CX483_MY20_Gas_Rx" SG_ 1438 GWM_GWOnBoardTester 1;
BA_ "U_CX482_CX483_MY20_Diesel_Rx" SG_ 1438 GWM_GWOnBoardTester 1;
BA_ "U_U611_U625_MY20_Hev_Rx" SG_ 1438 GWM_GWOnBoardTester 1;
BA_ "U_U611_U625_MY20_Gas_Rx" SG_ 1438 GWM_GWOnBoardTester 1;
BA_ "U_U611_U625_MY20_Diesel_Rx" SG_ 1438 GWM_GWOnBoardTester 1;
BA_ "U_B500_MY18_Diesel_Rx" SG_ 1438 GWM_GWOnBoardTester 1;
BA_ "U_B500_MY18_Gas_Rx" SG_ 1438 GWM_GWOnBoardTester 1;
BA_ "U_C490_MY18_Rx" SG_ 1438 GWM_GWOnBoardTester 1;
BA_ "U_B562_MY18_Gas_Rx" SG_ 1438 GWM_GWOnBoardTester 1;
BA_ "U_C519_MY18_5_Gas_Rx" SG_ 1438 GWM_GWOnBoardTester 1;
BA_ "U_C519_MY18_5_Diesel_Rx" SG_ 1438 GWM_GWOnBoardTester 1;
BA_ "ContentDependant" SG_ 1438 GWM_GWOnBoardTester 1;
BA_ "GenSigStartValue" SG_ 1438 GWM_GWOnBoardTester 255;
BA_ "U_U611_U625_MY20_Phev_Rx" SG_ 1438 GWM_GWNMProxy 1;
BA_ "U_CX482_CX483_MY20_Hev_Rx" SG_ 1438 GWM_GWNMProxy 1;
BA_ "U_CX482_CX483_MY20_Gas_Rx" SG_ 1438 GWM_GWNMProxy 1;
BA_ "U_CX482_CX483_MY20_Diesel_Rx" SG_ 1438 GWM_GWNMProxy 1;
BA_ "U_U611_U625_MY20_Hev_Rx" SG_ 1438 GWM_GWNMProxy 1;
BA_ "U_U611_U625_MY20_Gas_Rx" SG_ 1438 GWM_GWNMProxy 1;
BA_ "U_U611_U625_MY20_Diesel_Rx" SG_ 1438 GWM_GWNMProxy 1;
BA_ "U_B500_MY18_Diesel_Rx" SG_ 1438 GWM_GWNMProxy 1;
BA_ "U_B500_MY18_Gas_Rx" SG_ 1438 GWM_GWNMProxy 1;
BA_ "U_C490_MY18_Rx" SG_ 1438 GWM_GWNMProxy 1;
BA_ "U_B562_MY18_Gas_Rx" SG_ 1438 GWM_GWNMProxy 1;
BA_ "U_C519_MY18_5_Gas_Rx" SG_ 1438 GWM_GWNMProxy 1;
BA_ "U_C519_MY18_5_Diesel_Rx" SG_ 1438 GWM_GWNMProxy 1;
BA_ "ContentDependant" SG_ 1438 GWM_GWNMProxy 1;
BA_ "GenSigStartValue" SG_ 1438 GWM_GWNMProxy 255;
BA_ "U_U611_U625_MY20_Phev_Rx" SG_ 1438 GWM_AutoSarNMReserved4 1;
BA_ "U_CX482_CX483_MY20_Hev_Rx" SG_ 1438 GWM_AutoSarNMReserved4 1;
BA_ "U_CX482_CX483_MY20_Gas_Rx" SG_ 1438 GWM_AutoSarNMReserved4 1;
BA_ "U_CX482_CX483_MY20_Diesel_Rx" SG_ 1438 GWM_AutoSarNMReserved4 1;
BA_ "U_U611_U625_MY20_Hev_Rx" SG_ 1438 GWM_AutoSarNMReserved4 1;
BA_ "U_U611_U625_MY20_Gas_Rx" SG_ 1438 GWM_AutoSarNMReserved4 1;
BA_ "U_U611_U625_MY20_Diesel_Rx" SG_ 1438 GWM_AutoSarNMReserved4 1;
BA_ "U_B500_MY18_Diesel_Rx" SG_ 1438 GWM_AutoSarNMReserved4 1;
BA_ "U_B500_MY18_Gas_Rx" SG_ 1438 GWM_AutoSarNMReserved4 1;
BA_ "U_C490_MY18_Rx" SG_ 1438 GWM_AutoSarNMReserved4 1;
BA_ "U_B562_MY18_Gas_Rx" SG_ 1438 GWM_AutoSarNMReserved4 1;
BA_ "U_C519_MY18_5_Gas_Rx" SG_ 1438 GWM_AutoSarNMReserved4 1;
BA_ "U_C519_MY18_5_Diesel_Rx" SG_ 1438 GWM_AutoSarNMReserved4 1;
BA_ "ContentDependant" SG_ 1438 GWM_AutoSarNMReserved4 1;
BA_ "GenSigStartValue" SG_ 1438 GWM_AutoSarNMReserved4 255;
BA_ "U_U611_U625_MY20_Phev_Rx" SG_ 1438 GWM_AutoSarNMReserved3 1;
BA_ "U_CX482_CX483_MY20_Hev_Rx" SG_ 1438 GWM_AutoSarNMReserved3 1;
BA_ "U_CX482_CX483_MY20_Gas_Rx" SG_ 1438 GWM_AutoSarNMReserved3 1;
BA_ "U_CX482_CX483_MY20_Diesel_Rx" SG_ 1438 GWM_AutoSarNMReserved3 1;
BA_ "U_U611_U625_MY20_Hev_Rx" SG_ 1438 GWM_AutoSarNMReserved3 1;
BA_ "U_U611_U625_MY20_Gas_Rx" SG_ 1438 GWM_AutoSarNMReserved3 1;
BA_ "U_U611_U625_MY20_Diesel_Rx" SG_ 1438 GWM_AutoSarNMReserved3 1;
BA_ "U_B500_MY18_Diesel_Rx" SG_ 1438 GWM_AutoSarNMReserved3 1;
BA_ "U_B500_MY18_Gas_Rx" SG_ 1438 GWM_AutoSarNMReserved3 1;
BA_ "U_C490_MY18_Rx" SG_ 1438 GWM_AutoSarNMReserved3 1;
BA_ "U_B562_MY18_Gas_Rx" SG_ 1438 GWM_AutoSarNMReserved3 1;
BA_ "U_C519_MY18_5_Gas_Rx" SG_ 1438 GWM_AutoSarNMReserved3 1;
BA_ "U_C519_MY18_5_Diesel_Rx" SG_ 1438 GWM_AutoSarNMReserved3 1;
BA_ "ContentDependant" SG_ 1438 GWM_AutoSarNMReserved3 1;
BA_ "GenSigStartValue" SG_ 1438 GWM_AutoSarNMReserved3 255;
BA_ "U_U611_U625_MY20_Phev_Rx" SG_ 1438 GWM_AutoSarNMReserved2 1;
BA_ "U_CX482_CX483_MY20_Hev_Rx" SG_ 1438 GWM_AutoSarNMReserved2 1;
BA_ "U_CX482_CX483_MY20_Gas_Rx" SG_ 1438 GWM_AutoSarNMReserved2 1;
BA_ "U_CX482_CX483_MY20_Diesel_Rx" SG_ 1438 GWM_AutoSarNMReserved2 1;
BA_ "U_U611_U625_MY20_Hev_Rx" SG_ 1438 GWM_AutoSarNMReserved2 1;
BA_ "U_U611_U625_MY20_Gas_Rx" SG_ 1438 GWM_AutoSarNMReserved2 1;
BA_ "U_U611_U625_MY20_Diesel_Rx" SG_ 1438 GWM_AutoSarNMReserved2 1;
BA_ "U_B500_MY18_Diesel_Rx" SG_ 1438 GWM_AutoSarNMReserved2 1;
BA_ "U_B500_MY18_Gas_Rx" SG_ 1438 GWM_AutoSarNMReserved2 1;
BA_ "U_C490_MY18_Rx" SG_ 1438 GWM_AutoSarNMReserved2 1;
BA_ "U_B562_MY18_Gas_Rx" SG_ 1438 GWM_AutoSarNMReserved2 1;
BA_ "U_C519_MY18_5_Gas_Rx" SG_ 1438 GWM_AutoSarNMReserved2 1;
BA_ "U_C519_MY18_5_Diesel_Rx" SG_ 1438 GWM_AutoSarNMReserved2 1;
BA_ "ContentDependant" SG_ 1438 GWM_AutoSarNMReserved2 1;
BA_ "GenSigStartValue" SG_ 1438 GWM_AutoSarNMReserved2 255;
BA_ "U_U611_U625_MY20_Phev_Rx" SG_ 1438 GWM_AutoSarNMReserved1 1;
BA_ "U_CX482_CX483_MY20_Hev_Rx" SG_ 1438 GWM_AutoSarNMReserved1 1;
BA_ "U_CX482_CX483_MY20_Gas_Rx" SG_ 1438 GWM_AutoSarNMReserved1 1;
BA_ "U_CX482_CX483_MY20_Diesel_Rx" SG_ 1438 GWM_AutoSarNMReserved1 1;
BA_ "U_U611_U625_MY20_Hev_Rx" SG_ 1438 GWM_AutoSarNMReserved1 1;
BA_ "U_U611_U625_MY20_Gas_Rx" SG_ 1438 GWM_AutoSarNMReserved1 1;
BA_ "U_U611_U625_MY20_Diesel_Rx" SG_ 1438 GWM_AutoSarNMReserved1 1;
BA_ "U_B500_MY18_Diesel_Rx" SG_ 1438 GWM_AutoSarNMReserved1 1;
BA_ "U_B500_MY18_Gas_Rx" SG_ 1438 GWM_AutoSarNMReserved1 1;
BA_ "U_C490_MY18_Rx" SG_ 1438 GWM_AutoSarNMReserved1 1;
BA_ "U_B562_MY18_Gas_Rx" SG_ 1438 GWM_AutoSarNMReserved1 1;
BA_ "U_C519_MY18_5_Gas_Rx" SG_ 1438 GWM_AutoSarNMReserved1 1;
BA_ "U_C519_MY18_5_Diesel_Rx" SG_ 1438 GWM_AutoSarNMReserved1 1;
BA_ "ContentDependant" SG_ 1438 GWM_AutoSarNMReserved1 1;
BA_ "GenSigStartValue" SG_ 1438 GWM_AutoSarNMReserved1 255;
BA_ "U_CX482_CX483_MY20_Hev_Rx" SG_ 1438 GWM_AutoSarNMNodeId 1;
BA_ "U_CX482_CX483_MY20_Gas_Rx" SG_ 1438 GWM_AutoSarNMNodeId 1;
BA_ "U_CX482_CX483_MY20_Diesel_Rx" SG_ 1438 GWM_AutoSarNMNodeId 1;
BA_ "U_C490_MY18_Rx" SG_ 1438 GWM_AutoSarNMNodeId 1;
BA_ "U_B562_MY18_Gas_Rx" SG_ 1438 GWM_AutoSarNMNodeId 1;
BA_ "U_C519_MY18_5_Gas_Rx" SG_ 1438 GWM_AutoSarNMNodeId 1;
BA_ "U_C519_MY18_5_Diesel_Rx" SG_ 1438 GWM_AutoSarNMNodeId 1;
BA_ "U_U611_U625_MY20_Phev_Rx" SG_ 1438 GWM_AutoSarNMNodeId 1;
BA_ "U_U611_U625_MY20_Hev_Rx" SG_ 1438 GWM_AutoSarNMNodeId 1;
BA_ "U_U611_U625_MY20_Gas_Rx" SG_ 1438 GWM_AutoSarNMNodeId 1;
BA_ "U_U611_U625_MY20_Diesel_Rx" SG_ 1438 GWM_AutoSarNMNodeId 1;
BA_ "U_B500_MY18_Diesel_Rx" SG_ 1438 GWM_AutoSarNMNodeId 1;
BA_ "U_B500_MY18_Gas_Rx" SG_ 1438 GWM_AutoSarNMNodeId 1;
BA_ "ContentDependant" SG_ 1438 GWM_AutoSarNMNodeId 1;
BA_ "GenSigStartValue" SG_ 1438 GWM_AutoSarNMNodeId 158;
BA_ "U_CX482_CX483_MY20_Hev_Rx" SG_ 1438 GWM_AutoSarNMControl 1;
BA_ "U_CX482_CX483_MY20_Gas_Rx" SG_ 1438 GWM_AutoSarNMControl 1;
BA_ "U_CX482_CX483_MY20_Diesel_Rx" SG_ 1438 GWM_AutoSarNMControl 1;
BA_ "U_C490_MY18_Rx" SG_ 1438 GWM_AutoSarNMControl 1;
BA_ "U_B562_MY18_Gas_Rx" SG_ 1438 GWM_AutoSarNMControl 1;
BA_ "U_C519_MY18_5_Gas_Rx" SG_ 1438 GWM_AutoSarNMControl 1;
BA_ "U_C519_MY18_5_Diesel_Rx" SG_ 1438 GWM_AutoSarNMControl 1;
BA_ "U_U611_U625_MY20_Phev_Rx" SG_ 1438 GWM_AutoSarNMControl 1;
BA_ "U_U611_U625_MY20_Hev_Rx" SG_ 1438 GWM_AutoSarNMControl 1;
BA_ "U_U611_U625_MY20_Gas_Rx" SG_ 1438 GWM_AutoSarNMControl 1;
BA_ "U_U611_U625_MY20_Diesel_Rx" SG_ 1438 GWM_AutoSarNMControl 1;
BA_ "U_B500_MY18_Diesel_Rx" SG_ 1438 GWM_AutoSarNMControl 1;
BA_ "U_B500_MY18_Gas_Rx" SG_ 1438 GWM_AutoSarNMControl 1;
BA_ "ContentDependant" SG_ 1438 GWM_AutoSarNMControl 1;
BA_ "U_C490_MY18_Rx" SG_ 1034 VehicleGGCCData 1;
BA_ "U_B562_MY18_Gas_Rx" SG_ 1034 VehicleGGCCData 1;
BA_ "U_U611_U625_MY20_Phev_Rx" SG_ 1034 VehicleGGCCData 1;
BA_ "U_CX482_CX483_MY20_Hev_Rx" SG_ 1034 VehicleGGCCData 1;
BA_ "U_CX482_CX483_MY20_Gas_Rx" SG_ 1034 VehicleGGCCData 1;
BA_ "U_CX482_CX483_MY20_Diesel_Rx" SG_ 1034 VehicleGGCCData 1;
BA_ "U_U611_U625_MY20_Hev_Rx" SG_ 1034 VehicleGGCCData 1;
BA_ "U_U611_U625_MY20_Gas_Rx" SG_ 1034 VehicleGGCCData 1;
BA_ "U_U611_U625_MY20_Diesel_Rx" SG_ 1034 VehicleGGCCData 1;
BA_ "U_B500_MY18_Diesel_Rx" SG_ 1034 VehicleGGCCData 1;
BA_ "U_B500_MY18_Gas_Rx" SG_ 1034 VehicleGGCCData 1;
BA_ "U_C519_MY18_5_Gas_Rx" SG_ 1034 VehicleGGCCData 1;
BA_ "U_C519_MY18_5_Diesel_Rx" SG_ 1034 VehicleGGCCData 1;
BA_ "U_B515_MCA_MY17_Gas_Rx" SG_ 1034 VehicleGGCCData 1;
BA_ "U_B515_MCA_MY17_Diesel_Rx" SG_ 1034 VehicleGGCCData 1;
BA_ "U_B479_MY17_Diesel_Rx" SG_ 1034 VehicleGGCCData 1;
BA_ "U_B479_MY17_Gas_Rx" SG_ 1034 VehicleGGCCData 1;
BA_ "CrossOver_InfoCAN" SG_ 1034 VehicleGGCCData 1;
BA_ "U_CX482_CX483_MY20_Hev_Rx" SG_ 376 LnchCtlSys_D_Stat 1;
BA_ "U_CX482_CX483_MY20_Gas_Rx" SG_ 376 LnchCtlSys_D_Stat 1;
BA_ "U_CX482_CX483_MY20_Diesel_Rx" SG_ 376 LnchCtlSys_D_Stat 1;
BA_ "U_C519_MY18_5_Gas_Rx" SG_ 376 LnchCtlSys_D_Stat 1;
BA_ "U_C519_MY18_5_Diesel_Rx" SG_ 376 LnchCtlSys_D_Stat 1;
BA_ "U_B515_MCA_MY17_Gas_Rx" SG_ 376 LnchCtlSys_D_Stat 1;
BA_ "U_B515_MCA_MY17_Diesel_Rx" SG_ 376 LnchCtlSys_D_Stat 1;
BA_ "U_B479_MY17_Diesel_Rx" SG_ 376 LnchCtlSys_D_Stat 1;
BA_ "U_B479_MY17_Gas_Rx" SG_ 376 LnchCtlSys_D_Stat 1;
BA_ "U_CX482_CX483_MY20_Hev_Rx" SG_ 376 EngAout_Aa_Actl 1;
BA_ "U_CX482_CX483_MY20_Gas_Rx" SG_ 376 EngAout_Aa_Actl 1;
BA_ "U_CX482_CX483_MY20_Diesel_Rx" SG_ 376 EngAout_Aa_Actl 1;
BA_ "U_U611_U625_MY20_Hev_Rx" SG_ 376 EngAout_Aa_Actl 1;
BA_ "U_U611_U625_MY20_Gas_Rx" SG_ 376 EngAout_Aa_Actl 1;
BA_ "U_U611_U625_MY20_Diesel_Rx" SG_ 376 EngAout_Aa_Actl 1;
BA_ "U_B500_MY18_Diesel_Rx" SG_ 376 EngAout_Aa_Actl 1;
BA_ "U_B500_MY18_Gas_Rx" SG_ 376 EngAout_Aa_Actl 1;
BA_ "U_C490_MY18_Rx" SG_ 376 EngAout_Aa_Actl 1;
BA_ "U_B562_MY18_Gas_Rx" SG_ 376 EngAout_Aa_Actl 1;
BA_ "U_C519_MY18_5_Gas_Rx" SG_ 376 EngAout_Aa_Actl 1;
BA_ "U_C519_MY18_5_Diesel_Rx" SG_ 376 EngAout_Aa_Actl 1;
BA_ "U_B515_MCA_MY17_Gas_Rx" SG_ 376 EngAout_Aa_Actl 1;
BA_ "U_B515_MCA_MY17_Diesel_Rx" SG_ 376 EngAout_Aa_Actl 1;
BA_ "U_B479_MY17_Diesel_Rx" SG_ 376 EngAout_Aa_Actl 1;
BA_ "U_B479_MY17_Gas_Rx" SG_ 376 EngAout_Aa_Actl 1;
BA_ "ContentDependant" SG_ 376 EngAout_Aa_Actl 1;
BA_ "CrossOver_InfoCAN" SG_ 376 EngAout_Aa_Actl 1;
BA_ "U_CX482_CX483_MY20_Hev_Rx" SG_ 376 DynoMde_B_Cmd 1;
BA_ "U_CX482_CX483_MY20_Gas_Rx" SG_ 376 DynoMde_B_Cmd 1;
BA_ "U_CX482_CX483_MY20_Diesel_Rx" SG_ 376 DynoMde_B_Cmd 1;
BA_ "U_U611_U625_MY20_Hev_Rx" SG_ 376 DynoMde_B_Cmd 1;
BA_ "U_U611_U625_MY20_Gas_Rx" SG_ 376 DynoMde_B_Cmd 1;
BA_ "U_U611_U625_MY20_Diesel_Rx" SG_ 376 DynoMde_B_Cmd 1;
BA_ "U_B500_MY18_Diesel_Rx" SG_ 376 DynoMde_B_Cmd 1;
BA_ "U_B500_MY18_Gas_Rx" SG_ 376 DynoMde_B_Cmd 1;
BA_ "U_C490_MY18_Rx" SG_ 376 DynoMde_B_Cmd 1;
BA_ "U_B562_MY18_Gas_Rx" SG_ 376 DynoMde_B_Cmd 1;
BA_ "U_C519_MY18_5_Gas_Rx" SG_ 376 DynoMde_B_Cmd 1;
BA_ "U_C519_MY18_5_Diesel_Rx" SG_ 376 DynoMde_B_Cmd 1;
BA_ "U_B515_MCA_MY17_Gas_Rx" SG_ 376 DynoMde_B_Cmd 1;
BA_ "U_B515_MCA_MY17_Diesel_Rx" SG_ 376 DynoMde_B_Cmd 1;
BA_ "U_B479_MY17_Diesel_Rx" SG_ 376 DynoMde_B_Cmd 1;
BA_ "U_B479_MY17_Gas_Rx" SG_ 376 DynoMde_B_Cmd 1;
BA_ "GenSigStartValue" SG_ 376 HvacHtrCore2_Te_Actl 200;
BA_ "U_CX482_CX483_MY20_Hev_Rx" SG_ 376 AirAmbTe_D_Qf 1;
BA_ "U_CX482_CX483_MY20_Gas_Rx" SG_ 376 AirAmbTe_D_Qf 1;
BA_ "U_CX482_CX483_MY20_Diesel_Rx" SG_ 376 AirAmbTe_D_Qf 1;
BA_ "U_B500_MY18_Diesel_Rx" SG_ 376 AirAmbTe_D_Qf 1;
BA_ "U_B500_MY18_Gas_Rx" SG_ 376 AirAmbTe_D_Qf 1;
BA_ "U_C490_MY18_Rx" SG_ 376 AirAmbTe_D_Qf 1;
BA_ "U_B562_MY18_Gas_Rx" SG_ 376 AirAmbTe_D_Qf 1;
BA_ "U_B515_MCA_MY17_Gas_Rx" SG_ 376 AirAmbTe_D_Qf 1;
BA_ "U_B515_MCA_MY17_Diesel_Rx" SG_ 376 AirAmbTe_D_Qf 1;
BA_ "U_B479_MY17_Diesel_Rx" SG_ 376 AirAmbTe_D_Qf 1;
BA_ "U_B479_MY17_Gas_Rx" SG_ 376 AirAmbTe_D_Qf 1;
BA_ "U_U611_U625_MY20_Phev_Rx" SG_ 376 AirAmbTe_D_Qf 1;
BA_ "U_U611_U625_MY20_Hev_Rx" SG_ 376 AirAmbTe_D_Qf 1;
BA_ "U_U611_U625_MY20_Gas_Rx" SG_ 376 AirAmbTe_D_Qf 1;
BA_ "U_U611_U625_MY20_Diesel_Rx" SG_ 376 AirAmbTe_D_Qf 1;
BA_ "U_C519_MY18_5_Gas_Rx" SG_ 376 AirAmbTe_D_Qf 1;
BA_ "U_C519_MY18_5_Diesel_Rx" SG_ 376 AirAmbTe_D_Qf 1;
BA_ "GenSigStartValue" SG_ 376 AirAmbTe_D_Qf 1;
BA_ "CrossOver_InfoCAN" SG_ 376 AirAmbTe_D_Qf 1;
BA_ "U_CX482_CX483_MY20_Hev_Rx" SG_ 376 AirAmb_Te_ActlFilt 1;
BA_ "U_CX482_CX483_MY20_Gas_Rx" SG_ 376 AirAmb_Te_ActlFilt 1;
BA_ "U_CX482_CX483_MY20_Diesel_Rx" SG_ 376 AirAmb_Te_ActlFilt 1;
BA_ "U_U611_U625_MY20_Hev_Rx" SG_ 376 AirAmb_Te_ActlFilt 1;
BA_ "U_U611_U625_MY20_Gas_Rx" SG_ 376 AirAmb_Te_ActlFilt 1;
BA_ "U_U611_U625_MY20_Diesel_Rx" SG_ 376 AirAmb_Te_ActlFilt 1;
BA_ "U_C519_MY18_5_Gas_Rx" SG_ 376 AirAmb_Te_ActlFilt 1;
BA_ "U_C519_MY18_5_Diesel_Rx" SG_ 376 AirAmb_Te_ActlFilt 1;
BA_ "U_B479_MY17_Diesel_Rx" SG_ 376 AirAmb_Te_ActlFilt 1;
BA_ "U_B479_MY17_Gas_Rx" SG_ 376 AirAmb_Te_ActlFilt 1;
BA_ "GenSigStartValue" SG_ 376 AirAmb_Te_ActlFilt 512;
BA_ "CrossOver_InfoCAN" SG_ 376 AirAmb_Te_ActlFilt 1;
BA_ "U_CX482_CX483_MY20_Hev_Rx" SG_ 376 AirAmb_P_Actl 1;
BA_ "U_CX482_CX483_MY20_Gas_Rx" SG_ 376 AirAmb_P_Actl 1;
BA_ "U_CX482_CX483_MY20_Diesel_Rx" SG_ 376 AirAmb_P_Actl 1;
BA_ "U_B500_MY18_Diesel_Rx" SG_ 376 AirAmb_P_Actl 1;
BA_ "U_B500_MY18_Gas_Rx" SG_ 376 AirAmb_P_Actl 1;
BA_ "U_C490_MY18_Rx" SG_ 376 AirAmb_P_Actl 1;
BA_ "U_B562_MY18_Gas_Rx" SG_ 376 AirAmb_P_Actl 1;
BA_ "U_C519_MY18_5_Gas_Rx" SG_ 376 AirAmb_P_Actl 1;
BA_ "U_C519_MY18_5_Diesel_Rx" SG_ 376 AirAmb_P_Actl 1;
BA_ "U_B515_MCA_MY17_Gas_Rx" SG_ 376 AirAmb_P_Actl 1;
BA_ "U_B515_MCA_MY17_Diesel_Rx" SG_ 376 AirAmb_P_Actl 1;
BA_ "U_B479_MY17_Diesel_Rx" SG_ 376 AirAmb_P_Actl 1;
BA_ "U_B479_MY17_Gas_Rx" SG_ 376 AirAmb_P_Actl 1;
BA_ "CrossOver_InfoCAN" SG_ 376 AirAmb_P_Actl 1;
BA_ "U_CX482_CX483_MY20_Hev_Rx" SG_ 376 AirAmb_Te_Actl 1;
BA_ "U_CX482_CX483_MY20_Gas_Rx" SG_ 376 AirAmb_Te_Actl 1;
BA_ "U_CX482_CX483_MY20_Diesel_Rx" SG_ 376 AirAmb_Te_Actl 1;
BA_ "U_B500_MY18_Diesel_Rx" SG_ 376 AirAmb_Te_Actl 1;
BA_ "U_B500_MY18_Gas_Rx" SG_ 376 AirAmb_Te_Actl 1;
BA_ "U_C490_MY18_Rx" SG_ 376 AirAmb_Te_Actl 1;
BA_ "U_B562_MY18_Gas_Rx" SG_ 376 AirAmb_Te_Actl 1;
BA_ "U_B515_MCA_MY17_Gas_Rx" SG_ 376 AirAmb_Te_Actl 1;
BA_ "U_B515_MCA_MY17_Diesel_Rx" SG_ 376 AirAmb_Te_Actl 1;
BA_ "U_B479_MY17_Diesel_Rx" SG_ 376 AirAmb_Te_Actl 1;
BA_ "U_B479_MY17_Gas_Rx" SG_ 376 AirAmb_Te_Actl 1;
BA_ "U_U611_U625_MY20_Phev_Rx" SG_ 376 AirAmb_Te_Actl 1;
BA_ "U_U611_U625_MY20_Hev_Rx" SG_ 376 AirAmb_Te_Actl 1;
BA_ "U_U611_U625_MY20_Gas_Rx" SG_ 376 AirAmb_Te_Actl 1;
BA_ "U_U611_U625_MY20_Diesel_Rx" SG_ 376 AirAmb_Te_Actl 1;
BA_ "U_C519_MY18_5_Gas_Rx" SG_ 376 AirAmb_Te_Actl 1;
BA_ "U_C519_MY18_5_Diesel_Rx" SG_ 376 AirAmb_Te_Actl 1;
BA_ "GenSigStartValue" SG_ 376 AirAmb_Te_Actl 512;
BA_ "CrossOver_InfoCAN" SG_ 376 AirAmb_Te_Actl 1;
BA_ "GenSigStartValue" SG_ 516 EngAoutNActl_D_QF 1;
BA_ "CrossOver_InfoCAN" SG_ 516 EngAoutNActl_D_QF 1;
BA_ "CrossOver_InfoCAN" SG_ 516 ApedPos_PcRate_ActlArb 1;
BA_ "U_U611_U625_MY20_Phev_Rx" SG_ 516 ApedPos_Pc_ActlArb 1;
BA_ "U_CX482_CX483_MY20_Hev_Rx" SG_ 516 ApedPos_Pc_ActlArb 1;
BA_ "U_CX482_CX483_MY20_Gas_Rx" SG_ 516 ApedPos_Pc_ActlArb 1;
BA_ "U_CX482_CX483_MY20_Diesel_Rx" SG_ 516 ApedPos_Pc_ActlArb 1;
BA_ "U_U611_U625_MY20_Hev_Rx" SG_ 516 ApedPos_Pc_ActlArb 1;
BA_ "U_U611_U625_MY20_Gas_Rx" SG_ 516 ApedPos_Pc_ActlArb 1;
BA_ "U_U611_U625_MY20_Diesel_Rx" SG_ 516 ApedPos_Pc_ActlArb 1;
BA_ "U_C490_MY18_Rx" SG_ 516 ApedPos_Pc_ActlArb 1;
BA_ "U_B562_MY18_Gas_Rx" SG_ 516 ApedPos_Pc_ActlArb 1;
BA_ "U_C519_MY18_5_Gas_Rx" SG_ 516 ApedPos_Pc_ActlArb 1;
BA_ "U_C519_MY18_5_Diesel_Rx" SG_ 516 ApedPos_Pc_ActlArb 1;
BA_ "U_B515_MCA_MY17_Gas_Rx" SG_ 516 ApedPos_Pc_ActlArb 1;
BA_ "U_B515_MCA_MY17_Diesel_Rx" SG_ 516 ApedPos_Pc_ActlArb 1;
BA_ "U_B479_MY17_Diesel_Rx" SG_ 516 ApedPos_Pc_ActlArb 1;
BA_ "U_B479_MY17_Gas_Rx" SG_ 516 ApedPos_Pc_ActlArb 1;
BA_ "CrossOver_InfoCAN" SG_ 516 ApedPos_Pc_ActlArb 1;
BA_ "U_U611_U625_MY20_Phev_Rx" SG_ 516 ApedPosPcActl_D_Qf 1;
BA_ "U_CX482_CX483_MY20_Hev_Rx" SG_ 516 ApedPosPcActl_D_Qf 1;
BA_ "U_CX482_CX483_MY20_Gas_Rx" SG_ 516 ApedPosPcActl_D_Qf 1;
BA_ "U_CX482_CX483_MY20_Diesel_Rx" SG_ 516 ApedPosPcActl_D_Qf 1;
BA_ "U_U611_U625_MY20_Hev_Rx" SG_ 516 ApedPosPcActl_D_Qf 1;
BA_ "U_U611_U625_MY20_Gas_Rx" SG_ 516 ApedPosPcActl_D_Qf 1;
BA_ "U_U611_U625_MY20_Diesel_Rx" SG_ 516 ApedPosPcActl_D_Qf 1;
BA_ "U_C490_MY18_Rx" SG_ 516 ApedPosPcActl_D_Qf 1;
BA_ "U_B562_MY18_Gas_Rx" SG_ 516 ApedPosPcActl_D_Qf 1;
BA_ "U_C519_MY18_5_Gas_Rx" SG_ 516 ApedPosPcActl_D_Qf 1;
BA_ "U_C519_MY18_5_Diesel_Rx" SG_ 516 ApedPosPcActl_D_Qf 1;
BA_ "U_B515_MCA_MY17_Gas_Rx" SG_ 516 ApedPosPcActl_D_Qf 1;
BA_ "U_B515_MCA_MY17_Diesel_Rx" SG_ 516 ApedPosPcActl_D_Qf 1;
BA_ "U_B479_MY17_Diesel_Rx" SG_ 516 ApedPosPcActl_D_Qf 1;
BA_ "U_B479_MY17_Gas_Rx" SG_ 516 ApedPosPcActl_D_Qf 1;
BA_ "GenSigStartValue" SG_ 516 ApedPosPcActl_D_Qf 1;
BA_ "CrossOver_InfoCAN" SG_ 516 ApedPosPcActl_D_Qf 1;
BA_ "U_U611_U625_MY20_Phev_Rx" SG_ 516 EngAout_N_Actl 1;
BA_ "U_CX482_CX483_MY20_Hev_Rx" SG_ 516 EngAout_N_Actl 1;
BA_ "U_CX482_CX483_MY20_Gas_Rx" SG_ 516 EngAout_N_Actl 1;
BA_ "U_CX482_CX483_MY20_Diesel_Rx" SG_ 516 EngAout_N_Actl 1;
BA_ "U_U611_U625_MY20_Hev_Rx" SG_ 516 EngAout_N_Actl 1;
BA_ "U_U611_U625_MY20_Gas_Rx" SG_ 516 EngAout_N_Actl 1;
BA_ "U_U611_U625_MY20_Diesel_Rx" SG_ 516 EngAout_N_Actl 1;
BA_ "U_C490_MY18_Rx" SG_ 516 EngAout_N_Actl 1;
BA_ "U_B562_MY18_Gas_Rx" SG_ 516 EngAout_N_Actl 1;
BA_ "U_C519_MY18_5_Gas_Rx" SG_ 516 EngAout_N_Actl 1;
BA_ "U_C519_MY18_5_Diesel_Rx" SG_ 516 EngAout_N_Actl 1;
BA_ "U_B515_MCA_MY17_Gas_Rx" SG_ 516 EngAout_N_Actl 1;
BA_ "U_B515_MCA_MY17_Diesel_Rx" SG_ 516 EngAout_N_Actl 1;
BA_ "U_B479_MY17_Diesel_Rx" SG_ 516 EngAout_N_Actl 1;
BA_ "U_B479_MY17_Gas_Rx" SG_ 516 EngAout_N_Actl 1;
BA_ "CrossOver_InfoCAN" SG_ 516 EngAout_N_Actl 1;
BA_ "U_CX482_CX483_MY20_Hev_Rx" SG_ 516 ApedPosPcActl_No_Cs 1;
BA_ "U_CX482_CX483_MY20_Gas_Rx" SG_ 516 ApedPosPcActl_No_Cs 1;
BA_ "U_CX482_CX483_MY20_Diesel_Rx" SG_ 516 ApedPosPcActl_No_Cs 1;
BA_ "U_U611_U625_MY20_Hev_Rx" SG_ 516 ApedPosPcActl_No_Cs 1;
BA_ "U_U611_U625_MY20_Gas_Rx" SG_ 516 ApedPosPcActl_No_Cs 1;
BA_ "U_U611_U625_MY20_Diesel_Rx" SG_ 516 ApedPosPcActl_No_Cs 1;
BA_ "U_B500_MY18_Diesel_Rx" SG_ 516 ApedPosPcActl_No_Cs 1;
BA_ "U_B500_MY18_Gas_Rx" SG_ 516 ApedPosPcActl_No_Cs 1;
BA_ "U_B515_MCA_MY17_Gas_Rx" SG_ 516 ApedPosPcActl_No_Cs 1;
BA_ "U_B515_MCA_MY17_Diesel_Rx" SG_ 516 ApedPosPcActl_No_Cs 1;
BA_ "U_B479_MY17_Diesel_Rx" SG_ 516 ApedPosPcActl_No_Cs 1;
BA_ "U_B479_MY17_Gas_Rx" SG_ 516 ApedPosPcActl_No_Cs 1;
BA_ "ContentDependant" SG_ 516 ApedPosPcActl_No_Cs 1;
BA_ "CrossOver_InfoCAN" SG_ 516 ApedPosPcActl_No_Cs 1;
BA_ "ContentDependant" SG_ 516 EngAout3_N_Actl 1;
BA_ "CrossOver_InfoCAN" SG_ 516 EngAout3_N_Actl 1;
BA_ "U_CX482_CX483_MY20_Hev_Rx" SG_ 516 ApedPosPcActl_No_Cnt 1;
BA_ "U_CX482_CX483_MY20_Gas_Rx" SG_ 516 ApedPosPcActl_No_Cnt 1;
BA_ "U_CX482_CX483_MY20_Diesel_Rx" SG_ 516 ApedPosPcActl_No_Cnt 1;
BA_ "U_U611_U625_MY20_Hev_Rx" SG_ 516 ApedPosPcActl_No_Cnt 1;
BA_ "U_U611_U625_MY20_Gas_Rx" SG_ 516 ApedPosPcActl_No_Cnt 1;
BA_ "U_U611_U625_MY20_Diesel_Rx" SG_ 516 ApedPosPcActl_No_Cnt 1;
BA_ "U_B500_MY18_Diesel_Rx" SG_ 516 ApedPosPcActl_No_Cnt 1;
BA_ "U_B500_MY18_Gas_Rx" SG_ 516 ApedPosPcActl_No_Cnt 1;
BA_ "U_B562_MY18_Gas_Rx" SG_ 516 ApedPosPcActl_No_Cnt 1;
BA_ "U_B515_MCA_MY17_Gas_Rx" SG_ 516 ApedPosPcActl_No_Cnt 1;
BA_ "U_B515_MCA_MY17_Diesel_Rx" SG_ 516 ApedPosPcActl_No_Cnt 1;
BA_ "U_B479_MY17_Diesel_Rx" SG_ 516 ApedPosPcActl_No_Cnt 1;
BA_ "U_B479_MY17_Gas_Rx" SG_ 516 ApedPosPcActl_No_Cnt 1;
BA_ "ContentDependant" SG_ 516 ApedPosPcActl_No_Cnt 1;
BA_ "CrossOver_InfoCAN" SG_ 516 ApedPosPcActl_No_Cnt 1;
BA_ "CrossOver_InfoCAN" SG_ 514 StrtrMtrCtlMsgTxt_D_Rq 1;
BA_ "U_B515_MCA_MY17_Gas_Rx" SG_ 514 VehVActlEng_No_Cs 1;
BA_ "U_B515_MCA_MY17_Diesel_Rx" SG_ 514 VehVActlEng_No_Cs 1;
BA_ "U_CX482_CX483_MY20_Hev_Rx" SG_ 514 VehVActlEng_No_Cs 1;
BA_ "U_CX482_CX483_MY20_Gas_Rx" SG_ 514 VehVActlEng_No_Cs 1;
BA_ "U_CX482_CX483_MY20_Diesel_Rx" SG_ 514 VehVActlEng_No_Cs 1;
BA_ "U_B479_MY17_Diesel_Rx" SG_ 514 VehVActlEng_No_Cs 1;
BA_ "U_B479_MY17_Gas_Rx" SG_ 514 VehVActlEng_No_Cs 1;
BA_ "CrossOver_InfoCAN" SG_ 514 VehVActlEng_No_Cs 1;
BA_ "U_B515_MCA_MY17_Gas_Rx" SG_ 514 VehVActlEng_No_Cnt 1;
BA_ "U_B515_MCA_MY17_Diesel_Rx" SG_ 514 VehVActlEng_No_Cnt 1;
BA_ "U_CX482_CX483_MY20_Hev_Rx" SG_ 514 VehVActlEng_No_Cnt 1;
BA_ "U_CX482_CX483_MY20_Gas_Rx" SG_ 514 VehVActlEng_No_Cnt 1;
BA_ "U_CX482_CX483_MY20_Diesel_Rx" SG_ 514 VehVActlEng_No_Cnt 1;
BA_ "U_B479_MY17_Diesel_Rx" SG_ 514 VehVActlEng_No_Cnt 1;
BA_ "U_B479_MY17_Gas_Rx" SG_ 514 VehVActlEng_No_Cnt 1;
BA_ "CrossOver_InfoCAN" SG_ 514 VehVActlEng_No_Cnt 1;
BA_ "U_CX482_CX483_MY20_Hev_Rx" SG_ 514 Veh_V_RqCcSet 1;
BA_ "U_CX482_CX483_MY20_Gas_Rx" SG_ 514 Veh_V_RqCcSet 1;
BA_ "U_CX482_CX483_MY20_Diesel_Rx" SG_ 514 Veh_V_RqCcSet 1;
BA_ "U_U611_U625_MY20_Hev_Rx" SG_ 514 Veh_V_RqCcSet 1;
BA_ "U_U611_U625_MY20_Gas_Rx" SG_ 514 Veh_V_RqCcSet 1;
BA_ "U_U611_U625_MY20_Diesel_Rx" SG_ 514 Veh_V_RqCcSet 1;
BA_ "U_C519_MY18_5_Gas_Rx" SG_ 514 Veh_V_RqCcSet 1;
BA_ "U_C519_MY18_5_Diesel_Rx" SG_ 514 Veh_V_RqCcSet 1;
BA_ "U_B479_MY17_Diesel_Rx" SG_ 514 Veh_V_RqCcSet 1;
BA_ "U_B479_MY17_Gas_Rx" SG_ 514 Veh_V_RqCcSet 1;
BA_ "CrossOver_InfoCAN" SG_ 514 Veh_V_RqCcSet 1;
BA_ "U_U611_U625_MY20_Phev_Rx" SG_ 514 VehVActlEng_D_Qf 1;
BA_ "U_B500_MY18_Diesel_Rx" SG_ 514 VehVActlEng_D_Qf 1;
BA_ "U_B500_MY18_Gas_Rx" SG_ 514 VehVActlEng_D_Qf 1;
BA_ "U_B515_MCA_MY17_Gas_Rx" SG_ 514 VehVActlEng_D_Qf 1;
BA_ "U_B515_MCA_MY17_Diesel_Rx" SG_ 514 VehVActlEng_D_Qf 1;
BA_ "U_CX482_CX483_MY20_Hev_Rx" SG_ 514 VehVActlEng_D_Qf 1;
BA_ "U_CX482_CX483_MY20_Gas_Rx" SG_ 514 VehVActlEng_D_Qf 1;
BA_ "U_CX482_CX483_MY20_Diesel_Rx" SG_ 514 VehVActlEng_D_Qf 1;
BA_ "U_U611_U625_MY20_Hev_Rx" SG_ 514 VehVActlEng_D_Qf 1;
BA_ "U_U611_U625_MY20_Gas_Rx" SG_ 514 VehVActlEng_D_Qf 1;
BA_ "U_U611_U625_MY20_Diesel_Rx" SG_ 514 VehVActlEng_D_Qf 1;
BA_ "U_C519_MY18_5_Gas_Rx" SG_ 514 VehVActlEng_D_Qf 1;
BA_ "U_C519_MY18_5_Diesel_Rx" SG_ 514 VehVActlEng_D_Qf 1;
BA_ "U_B479_MY17_Diesel_Rx" SG_ 514 VehVActlEng_D_Qf 1;
BA_ "U_B479_MY17_Gas_Rx" SG_ 514 VehVActlEng_D_Qf 1;
BA_ "CrossOver_InfoCAN" SG_ 514 VehVActlEng_D_Qf 1;
BA_ "U_U611_U625_MY20_Phev_Rx" SG_ 514 Veh_V_ActlEng 1;
BA_ "U_B515_MCA_MY17_Gas_Rx" SG_ 514 Veh_V_ActlEng 1;
BA_ "U_B515_MCA_MY17_Diesel_Rx" SG_ 514 Veh_V_ActlEng 1;
BA_ "U_CX482_CX483_MY20_Hev_Rx" SG_ 514 Veh_V_ActlEng 1;
BA_ "U_CX482_CX483_MY20_Gas_Rx" SG_ 514 Veh_V_ActlEng 1;
BA_ "U_CX482_CX483_MY20_Diesel_Rx" SG_ 514 Veh_V_ActlEng 1;
BA_ "U_U611_U625_MY20_Hev_Rx" SG_ 514 Veh_V_ActlEng 1;
BA_ "U_U611_U625_MY20_Gas_Rx" SG_ 514 Veh_V_ActlEng 1;
BA_ "U_U611_U625_MY20_Diesel_Rx" SG_ 514 Veh_V_ActlEng 1;
BA_ "U_C519_MY18_5_Gas_Rx" SG_ 514 Veh_V_ActlEng 1;
BA_ "U_C519_MY18_5_Diesel_Rx" SG_ 514 Veh_V_ActlEng 1;
BA_ "U_B479_MY17_Diesel_Rx" SG_ 514 Veh_V_ActlEng 1;
BA_ "U_B479_MY17_Gas_Rx" SG_ 514 Veh_V_ActlEng 1;
BA_ "CrossOver_InfoCAN" SG_ 514 Veh_V_ActlEng 1;
BA_ "ContentDependant" SG_ 514 EngAout_Tq_VacLimSpcN 1;
BA_ "CrossOver_InfoCAN" SG_ 514 EngAout_Tq_VacLimSpcN 1;
BA_ "ContentDependant" SG_ 514 EngCylSync_No_Ctr 1;
BA_ "CrossOver_InfoCAN" SG_ 514 EngCylSync_No_Ctr 1;
BA_ "U_C490_MY18_Rx" SG_ 514 GearRvrse_D_Actl 1;
BA_ "U_B562_MY18_Gas_Rx" SG_ 514 GearRvrse_D_Actl 1;
BA_ "U_B515_MCA_MY17_Gas_Rx" SG_ 514 GearRvrse_D_Actl 1;
BA_ "U_B515_MCA_MY17_Diesel_Rx" SG_ 514 GearRvrse_D_Actl 1;
BA_ "U_U611_U625_MY20_Phev_Rx" SG_ 514 GearRvrse_D_Actl 1;
BA_ "U_CX482_CX483_MY20_Hev_Rx" SG_ 514 GearRvrse_D_Actl 1;
BA_ "U_CX482_CX483_MY20_Gas_Rx" SG_ 514 GearRvrse_D_Actl 1;
BA_ "U_CX482_CX483_MY20_Diesel_Rx" SG_ 514 GearRvrse_D_Actl 1;
BA_ "U_U611_U625_MY20_Hev_Rx" SG_ 514 GearRvrse_D_Actl 1;
BA_ "U_U611_U625_MY20_Gas_Rx" SG_ 514 GearRvrse_D_Actl 1;
BA_ "U_U611_U625_MY20_Diesel_Rx" SG_ 514 GearRvrse_D_Actl 1;
BA_ "U_B500_MY18_Diesel_Rx" SG_ 514 GearRvrse_D_Actl 1;
BA_ "U_B500_MY18_Gas_Rx" SG_ 514 GearRvrse_D_Actl 1;
BA_ "U_C519_MY18_5_Gas_Rx" SG_ 514 GearRvrse_D_Actl 1;
BA_ "U_C519_MY18_5_Diesel_Rx" SG_ 514 GearRvrse_D_Actl 1;
BA_ "U_B479_MY17_Diesel_Rx" SG_ 514 GearRvrse_D_Actl 1;
BA_ "U_B479_MY17_Gas_Rx" SG_ 514 GearRvrse_D_Actl 1;
BA_ "GenSigStartValue" SG_ 514 GearRvrse_D_Actl 7;
BA_ "CrossOver_InfoCAN" SG_ 514 GearRvrse_D_Actl 1;
BA_ "GenSigMissingSourceValue" SG_ 514 GearRvrse_D_Actl 3;
BA_ "GenSigStartValue" SG_ 1003 PersNoPos_D_Actl 4;
BA_ "CrossOver_InfoCAN" SG_ 1003 PersNoPos_D_Actl 1;
BA_ "CrossOver_InfoCAN" SG_ 1003 PersSetupRestr_D_Actl 1;
BA_ "CrossOver_InfoCAN" SG_ 1003 PersSetupAccessCtrl 1;
BA_ "CrossOver_InfoCAN" SG_ 1003 PersSetup_No_Actl 1;
BA_ "GenSigStartValue" SG_ 1003 PersConflict_D_Actl 1;
BA_ "CrossOver_InfoCAN" SG_ 1003 PersConflict_D_Actl 1;
BA_ "CrossOver_InfoCAN" SG_ 1003 AssocConfirm_D_Actl 1;
BA_ "U_U611_U625_MY20_Hev_Rx" SG_ 1003 RecallEvent_No_Cnt 1;
BA_ "U_U611_U625_MY20_Gas_Rx" SG_ 1003 RecallEvent_No_Cnt 1;
BA_ "U_U611_U625_MY20_Diesel_Rx" SG_ 1003 RecallEvent_No_Cnt 1;
BA_ "CrossOver_InfoCAN" SG_ 1003 RecallEvent_No_Cnt 1;
BA_ "U_CX482_CX483_MY20_Hev_Rx" SG_ 1003 PersNo_D_Actl 1;
BA_ "U_CX482_CX483_MY20_Gas_Rx" SG_ 1003 PersNo_D_Actl 1;
BA_ "U_CX482_CX483_MY20_Diesel_Rx" SG_ 1003 PersNo_D_Actl 1;
BA_ "U_U611_U625_MY20_Hev_Rx" SG_ 1003 PersNo_D_Actl 1;
BA_ "U_U611_U625_MY20_Gas_Rx" SG_ 1003 PersNo_D_Actl 1;
BA_ "U_U611_U625_MY20_Diesel_Rx" SG_ 1003 PersNo_D_Actl 1;
BA_ "U_C519_MY18_5_Gas_Rx" SG_ 1003 PersNo_D_Actl 1;
BA_ "U_C519_MY18_5_Diesel_Rx" SG_ 1003 PersNo_D_Actl 1;
BA_ "U_B479_MY17_Diesel_Rx" SG_ 1003 PersNo_D_Actl 1;
BA_ "U_B479_MY17_Gas_Rx" SG_ 1003 PersNo_D_Actl 1;
BA_ "GenSigStartValue" SG_ 1003 PersNo_D_Actl 4;
BA_ "CrossOver_InfoCAN" SG_ 1003 PersNo_D_Actl 1;
VAL_ 1082 EsaOn_B_Rq_UB 1 "Fresh_data" 0 "Unchanged_data" ;
VAL_ 1082 EsaOn_B_Rq 1 "On" 0 "Off" ;
VAL_ 1082 RearDiffLck_D_RqArb_UB 1 "Fresh_data" 0 "Unchanged_data" ;
VAL_ 1082 RearDiffLck_D_RqArb 3 "Faulty" 2 "NotUsed" 1 "On" 0 "Off" ;
VAL_ 1082 AwdMde_D_RqArb_UB 1 "Fresh_data" 0 "Unchanged_data" ;
VAL_ 1082 AwdMde_D_RqArb 7 "Faulty" 6 "NotUsed2" 5 "NoRequest" 4 "Neutral" 3 "FourByFourLow" 2 "FourByFourHigh" 1 "FourByFourAuto" 0 "FourByTwo" ;
VAL_ 1082 SelDrvMdeTxtReset_B_Rq_UB 1 "Fresh_data" 0 "Unchanged_data" ;
VAL_ 1082 SelDrvMdeTxtReset_B_Rq 1 "Yes" 0 "No" ;
VAL_ 1082 SelDrvMdeDsply_B_Avail_UB 1 "Fresh_data" 0 "Unchanged_data" ;
VAL_ 1082 AirSusp_D_RqDrv_UB 1 "Fresh_data" 0 "Unchanged_data" ;
VAL_ 1082 DrvInputRequired_B_Rq_UB 1 "Fresh_data" 0 "Unchanged_data" ;
VAL_ 1082 DrvInputRequired_B_Rq 1 "Yes" 0 "No" ;
VAL_ 1082 SelDrvMdeSwtch_D_Stat2_UB 1 "Fresh_data" 0 "Unchanged_data" ;
VAL_ 1082 SelDrvMdeSwtch_D_Stat2 3 "Faulty" 2 "SwitchState2" 1 "SwitchState1" 0 "NotPressed" ;
VAL_ 1082 SelDrvMdeSwtch_D_Stat3_UB 1 "Fresh_data" 0 "Unchanged_data" ;
VAL_ 1082 FapLcStopHold_B_Rq 1 "Yes" 0 "No" ;
VAL_ 1082 SelDrvMdeDsply_B_Avail 1 "Available" 0 "NotAvailable" ;
VAL_ 1082 FapLcPrchgBrk_B_Rq 1 "Yes" 0 "No" ;
VAL_ 1082 FapLcStopHold_B_Rq_UB 1 "Fresh_data" 0 "Unchanged_data" ;
VAL_ 1082 FapLcPrchgBrk_B_Rq_UB 1 "Fresh_data" 0 "Unchanged_data" ;
VAL_ 1082 LnchCtl_N_Rq_UB 1 "Fresh_data" 0 "Unchanged_data" ;
VAL_ 1082 LnchCtl_D_Rq_UB 1 "Fresh_data" 0 "Unchanged_data" ;
VAL_ 1082 LnchCtl_D_Rq 3 "NotUsed2" 2 "NotUsed1" 1 "LC_On" 0 "LC_Off" ;
VAL_ 1082 AirSusp_D_RqDrv 3 "NotUsed" 2 "On" 1 "Off" 0 "NoModeSelected" ;
VAL_ 1082 AwdRnge_D_ActlIpc_UB 1 "Fresh_data" 0 "Unchanged_data" ;
VAL_ 1082 AwdRnge_D_ActlIpc 7 "Unknown" 6 "High_Range_2wd" 5 "High_Range_Auto" 4 "High_Range_Locked" 3 "Neutral" 2 "Low_Range_2wd" 1 "Low_Range_Auto" 0 "Low_Range_Locked" ;
VAL_ 1082 NtrlTowMdeEnbl_B_RqDrv_UB 1 "Fresh_data" 0 "Unchanged_data" ;
VAL_ 1082 NtrlTowMdeEnbl_B_RqDrv 1 "Yes" 0 "No" ;
VAL_ 1082 DrvSlipCtlMde_B_RqMyKey_UB 1 "Fresh_data" 0 "Unchanged_data" ;
VAL_ 1082 DrvSlipCtlMde_B_RqMyKey 1 "On" 0 "Off" ;
VAL_ 1082 AwdDrvMde_D_Rq_UB 1 "Fresh_data" 0 "Unchanged_data" ;
VAL_ 1082 AwdDrvMde_D_Rq 7 "Faulty" 6 "NotAvailable" 5 "RockCrawl" 4 "Baja" 3 "MudAndSand" 2 "Weather" 1 "Sport" 0 "Normal" ;
VAL_ 1082 MetricActv_B_Actl_UB 1 "Fresh_data" 0 "Unchanged_data" ;
VAL_ 1082 MetricActv_B_Actl 1 "Active" 0 "Inactive" ;
VAL_ 1082 CamraFrntBttn_D_Stat2_UB 1 "Fresh_data" 0 "Unchanged_data" ;
VAL_ 1082 CamraFrntBttn_D_Stat2 1 "Pressed" 0 "Not_Pressed" ;
VAL_ 1082 BrkLineLck_D_Rq_UB 1 "Fresh_data" 0 "Unchanged_data" ;
VAL_ 1082 BrkLineLck_D_Rq 3 "Off" 2 "Engage" 1 "Initiate" 0 "NoRequest" ;
VAL_ 1082 SuspDrvMde_D_Rq_UB 1 "Fresh_data" 0 "Unchanged_data" ;
VAL_ 1082 SuspDrvMde_D_Rq 7 "Faulty" 6 "NotUsed2" 5 "NotUsed1" 4 "Drag" 3 "Track" 2 "Snow_Wet" 1 "Sport" 0 "Normal" ;
VAL_ 1082 SelDrvMdePt_D_Stat_UB 1 "Fresh_data" 0 "Unchanged_data" ;
VAL_ 1082 SelDrvMdePt_D_Stat 3 "Faulty" 2 "TemporarilyNotAvailable" 1 "Available" 0 "NotAvailable" ;
VAL_ 609 AwdLck_Tq_Rq 4095 "Fault" 4094 "Unknown" ;
VAL_ 609 AwdLck_Tq_Actl 4095 "Fault" 4094 "Unknown" ;
VAL_ 609 AwdTerrMdeChng_D_Rdy 7 "Fault" 6 "Undefined_2" 5 "Undefined_1" 4 "ModeUnavailDrInputRqd" 3 "SpOpModes_NotSupported" 2 "ModeUnavailDynamicCond" 1 "Module_In_Initialization" 0 "Mode_Change_Available" ;
VAL_ 609 AwdTerrMde_D_Actl 7 "Fail_Safe_Default" 6 "Dynamic_Mode" 5 "Rock_Crawl_Mode" 4 "Mud_Ruts_Mode" 3 "Sand_Mode" 2 "Undefined" 1 "Low_Mu_Mode" 0 "Special_Operating_Mode_Off" ;
VAL_ 609 AwdStat_D_RqDsply 31 "NotUsed9" 30 "NotUsed8" 29 "NotUsed7" 28 "NotUsed6" 27 "NotUsed5" 26 "NotUsed4" 25 "Lkr_Mode_Unavail_TMS" 24 " _4x4_Mode_Unavail_TMS" 23 "Out_of_4Low_Crawl" 22 "AWD_PTU_Oil_Changed" 21 "Change_AWD_PTU_Oil" 20 "Neutral_Tow_Disabled" 19 "Neutral_Tow_Enabled" 18 "AWD_OFF" 17 "_4x4_Off_Road_Speed" 16 "_4x4_Extreme_Off_Road_Mode" 15 "_4x4_Exiting_Off_Road" 14 "_4x4_Off_Road_Mode" 10 "_4x4_Locked_Temporarily" 9 "Shift_In_Progress" 13 "Blocked_Shift_Assist" 12 "_4x4_Auto_Restored" 11 "_4x4_Disabled_Temporarily" 7 "Out_of_4Low__Neutral" 6 "Out_of_4Low__Brake" 5 "Out_of_4Low__Speed" 4 "Into_4Low__Clutch" 3 "Into_4Low__Neutral" 2 "Into_4Low__Brake" 1 "Into_4Low__Speed" 0 "Normal__No_Message" 8 "Out_of_4Low__Clutch" ;
VAL_ 609 AwdLck_D_Stat 9 "Undefined" 8 "Under_External_Torque_Ctrl" 7 "Torque_Limited_by_Cmd" 6 "Fully_Locked_by_Cmd" 5 "Disabled" 4 "Warning" 3 "Fault" 2 "Inactive" 1 "Completely_Opened_by_Cmd" 0 "OK" ;
VAL_ 609 AwdSrvcRqd_B_Rq 1 "On" 0 "Off" ;
VAL_ 92 TrnLvrV_D_Rq 3 "Full_Speed" 2 "Aggressive" 1 "Normal" 0 "Quiet" ;
VAL_ 92 TrnSbwSysHlth_D_Actl 3 "OK" 2 "Degraded" 1 "No_Data_Exists" 0 "Faulty" ;
VAL_ 92 TrnDtpCmd_D_Actl 7 "NotUsed4" 6 "NotUsed3" 5 "NotUsed2" 4 "Relatch" 3 "Deploy" 2 "Self_Test" 1 "No_Command" 0 "NotUsed1" ;
VAL_ 92 TrnGearNtmAllow_B_Stat 1 "Yes" 0 "No" ;
VAL_ 92 GearSelLck_D_Rq 3 "PreventionBlocker" 2 "Unlock" 1 "Lock" 0 "Null" ;
VAL_ 92 TrnValidGear_D_Cnfm 3 "Accept" 2 "Reject" 1 "Internal_Request" 0 "No_Command" ;
VAL_ 92 TrnNtrlTowCmd_D_Actl 3 "NotUsed" 2 "Neutral_Tow_Entry" 1 "Car_Wash_Mode" 0 "Normal_Mode" ;
VAL_ 92 TrnGearCmd_Pc_ActlPt 1023 "Fault" ;
VAL_ 92 TrnGear_D_RqPt 7 "Fault" 6 "NotUsed" 5 "Manual" 4 "Drive" 3 "Neutral" 2 "Reverse" 1 "Park" 0 "No_Gear" ;
VAL_ 92 TrnCmdState_B_Actl 1 "Yes" 0 "No" ;
VAL_ 92 PrkBrkActv_D_RqTrnGear 3 "NotUsed2" 2 "RequestParkBrakeEngage" 1 "NoRequest" 0 "NotUsed1" ;
VAL_ 92 TrnGearMsgTxt_D_Rq 15 "Message_15" 14 "Message_14" 13 "Message_13" 12 "Message_12" 11 "Message_11" 10 "Message_10" 9 "Message_9" 8 "Message_8" 7 "Message_7" 6 "Message_6" 5 "Message_5" 4 "Message_4" 3 "Message_3" 2 "Message_2" 1 "Message_1" 0 "NoMessage" ;
VAL_ 361 TrcmSrvcRqd_B_Rq 1 "Yes" 0 "No" ;
VAL_ 361 TrnGear_I_MeasMax 255 "Fault" ;
VAL_ 361 TrnActFalt_B_Actl 1 "Yes" 0 "No" ;
VAL_ 361 TrnCapHlth_Actl 3 "Capacitor_OK" 2 "Degraded_Capacitor" 1 "Capacitor_State_Unknown" 0 "Capacitor_Fault" ;
VAL_ 361 TrnPwmFalt_B_Actl 1 "Yes" 0 "No" ;
VAL_ 93 TrnTrcmNtmState_D_Actl 3 "Faulty" 2 "Neutral_Tow_Mode" 1 "Car_Wash_Mode" 0 "None" ;
VAL_ 93 TrnSns2Pos_Pc_Actl 1023 "Fault" ;
VAL_ 93 TrnSns1Pos_Pc_Actl 1023 "Fault" ;
VAL_ 93 TrnSecPrkStat_D_Actl 7 "Faulty" 6 "Fault_Released" 5 "Fault_Latched" 4 "Recouple_in_Progress" 3 "Mechanism_Released" 2 "RTP_in_Progress" 1 "Pending" 0 "Latched" ;
VAL_ 93 TrnNtrlTowCnfm_B_Actl 1 "Yes" 0 "No" ;
VAL_ 93 TrnGearFinalPos_B_Actl 1 "Yes" 0 "No" ;
VAL_ 93 TrnGear_D_Actl 7 "Fault" 6 "NotUsed" 5 "Manual" 4 "Drive" 3 "Neutral" 2 "Reverse" 1 "Park" 0 "Transition_State" ;
VAL_ 360 GsmSrvcRqd_B_Rq 1 "Yes" 0 "No" ;
VAL_ 360 TrnTrcmPwmSig_D_Actl 15 "Faulty" 14 "NoDataExists" 13 "NotUsed5" 12 "NotUsed4" 11 "NotUsed3" 10 "NotUsed2" 9 "NotUsed1" 8 "Default_To_Park" 7 "Neutral_Tow" 6 "Car_Wash_Mode" 5 "Manual" 4 "Drive" 3 "Neutral" 2 "Reverse" 1 "Park" 0 "No_Gear" ;
VAL_ 360 TrnGearPwmFalt_B_Actl 1 "Yes" 0 "No" ;
VAL_ 360 GearButtnStuck_B_Actl 1 "Yes" 0 "No" ;
VAL_ 90 TrnGsmNtmState_D_Actl 3 "Faulty" 2 "Neutral_Tow_Mode" 1 "Car_Wash_Mode" 0 "None" ;
VAL_ 90 DrQltyDrv_D_StatGsm 7 "Faulty" 6 "NoDataExists" 5 "NotUsed2" 4 "NotUsed1" 3 "ClosedDegraded" 2 "OpenDegraded" 1 "ClosedOkay" 0 "OpenOkay" ;
VAL_ 90 TrnBtsiOvrrd_B_Stat 1 "Override" 0 "Null" ;
VAL_ 90 GsmGearMsgTxt_D_Rq 3 "Message3" 2 "Message2" 1 "Message1" 0 "NoMessage" ;
VAL_ 90 TrnRng_D_RqGsm 15 "Fault" 14 "UnknownPosition" 13 "Undefined_2" 12 "Undefined_1" 11 "_6" 10 "_5" 9 "_4" 8 "_3" 7 "_2" 6 "_1" 5 "Low" 4 "Sport_DriveSport" 3 "Drive" 2 "Neutral" 1 "Reverse" 0 "Park" ;
VAL_ 90 PrkBrkActv_D_RqGsmGear 3 "NotUsed" 2 "RequestParkBrakeEngage" 1 "NoRequest" 0 "Null" ;
VAL_ 90 TrnValidGearRq_D_Stat 3 "Valid_Request" 2 "Valid_Degraded_Request" 1 "Invalid_Request" 0 "No_Request" ;
VAL_ 90 TrnGearButtn_U_Actl 255 "Fault" ;
VAL_ 90 TrnGearButtn_B_ActlR2 1 "Yes" 0 "No" ;
VAL_ 90 TrnGearButtn_B_ActlR1 1 "Yes" 0 "No" ;
VAL_ 90 TrnGearButtn_B_ActlR0 1 "Yes" 0 "No" ;
VAL_ 90 TrnGearButtn_B_ActlP2 1 "Yes" 0 "No" ;
VAL_ 90 TrnGearButtn_B_ActlP1 1 "Yes" 0 "No" ;
VAL_ 90 TrnGearButtn_B_ActlP0 1 "Yes" 0 "No" ;
VAL_ 90 TrnGearButtn_B_ActlN2 1 "Yes" 0 "No" ;
VAL_ 90 TrnGearButtn_B_ActlN1 1 "Yes" 0 "No" ;
VAL_ 90 TrnGearButtn_B_ActlN0 1 "Yes" 0 "No" ;
VAL_ 90 TrnGearButtn_B_ActlM2 1 "Yes" 0 "No" ;
VAL_ 90 TrnGearButtn_B_ActlM1 1 "Yes" 0 "No" ;
VAL_ 90 TrnGearButtn_B_ActlM0 1 "Yes" 0 "No" ;
VAL_ 90 TrnGearButtn_B_ActlD2 1 "Yes" 0 "No" ;
VAL_ 90 TrnGearButtn_B_ActlD1 1 "Yes" 0 "No" ;
VAL_ 90 TrnGearButtn_B_ActlD0 1 "Yes" 0 "No" ;
VAL_ 90 TrnGear_D_RqDrv 31 "Fault" 30 "NotUsed_25" 29 "NotUsed_24" 28 "NotUsed_23" 27 "NotUsed_22" 26 "Return_to_Park" 25 "NotUsed_20" 24 "NotUsed_19" 23 "NotUsed_18" 22 "NotUsed_17" 21 "Return_To_Park" 20 "NotUsed_15" 19 "NotUsed_14" 18 "NotUsed_13" 17 "NotUsed_12" 16 "Manual" 15 "Not_Used11" 14 "Not_Used10" 13 "NotUsed_9" 12 "NotUsed_8" 11 "NotUsed_7" 10 "NotUsed_6" 9 "NotUsed_5" 8 "Drive" 7 "NotUsed_4" 6 "NotUsed_3" 5 "NotUsed_2" 4 "Neutral" 3 "NotUsed_1" 2 "Reverse" 1 "Park" 0 "No_Gear" ;
VAL_ 90 BrkSwtchPos_B_ActlGsm 1 "Yes" 0 "No" ;
VAL_ 512 PtDrvMde_D_Stat 15 "Faulty" 14 "NotUsed11" 13 "NotUsed10" 12 "NotUsed9" 11 "NotUsed8" 10 "NotUsed7" 9 "NotUsed6" 8 "NotUsed5" 7 "NotUsed4" 6 "Rock" 5 "Baja" 4 "Sand" 3 "TowHaulGradeAssist" 2 "SnowWet" 1 "Sport" 0 "Normal" ;
VAL_ 936 ApaChime_D_Rq 7 "NotUsed2" 6 "NotUsed1" 5 "Warning_Chime" 4 "Finish_Chime" 3 "Stop_Now_Chime" 2 "Spot_Ready_Chime" 1 "Spot_Found_Chime" 0 "No_Chime" ;
VAL_ 936 ApaSys_D_Stat 7 "Faulty" 6 "Finished" 5 "NotAccessible" 4 "ApaCancelled" 3 "Overspeed" 2 "On" 1 "Off" 0 "Null" ;
VAL_ 936 ApaSteWhl_D_RqDrv 3 "TakeControl" 2 "RemoveHands" 1 "NoRequest" 0 "Null" ;
VAL_ 936 ApaSteScanMde_D_Stat 3 "Steering" 2 "Scanning" 1 "NotScanning" 0 "Null" ;
VAL_ 936 ApaSelSapp_D_Stat 3 "NotConfigured" 2 "NotSelectable" 1 "Selectable" 0 "Null" ;
VAL_ 936 ApaSelPpa_D_Stat 3 "NotConfigured" 2 "NotSelectable" 1 "Selectable" 0 "Null" ;
VAL_ 936 ApaSelPoa_D_Stat 3 "NotConfigured" 2 "NotSelectable" 1 "Selectable" 0 "Null" ;
VAL_ 936 ApaScan_D_Stat 3 "ParkSlotReady" 2 "ParkSlotFound" 1 "NoParkSlot" 0 "Null" ;
VAL_ 936 ApaLongCtl_D_RqDrv 7 "NotUsed3" 6 "NotUsed2" 5 "ReleaseBrake" 4 "DriveBackward" 3 "DriveForward" 2 "Stop" 1 "NoRequest" 0 "Null" ;
VAL_ 936 ApaGearShif_D_RqDrv 7 "NotUSed2" 6 "NotUsed1" 5 "ShiftToP" 4 "ShiftToN" 3 "ShiftToD" 2 "ShiftToR" 1 "NoRequest" 0 "Null" ;
VAL_ 936 ApaActvSide2_D_Stat 3 "NoSide" 2 "Right" 1 "Left" 0 "Null" ;
VAL_ 936 ApaAcsy_D_RqDrv 7 "CloseDoor" 6 "SelectSideRight" 5 "SelectSideLeft" 4 "CheckForObject" 3 "PressApaButton" 2 "SelectSide" 1 "NoRequest" 0 "Null" ;
VAL_ 936 ApaTrgtDist_D_Stat 15 "Step15" 14 "Step14" 13 "Step13" 12 "Step12" 11 "Step11" 10 "Step10" 9 "Step9" 8 "Step8" 7 "Step7" 6 "Step6" 5 "Step5" 4 "Step4" 3 "Step3" 2 "Step2" 1 "Step1" 0 "Off" ;
VAL_ 936 EPASExtAngleStatReq 1 "Request" 0 "NoRequest" ;
VAL_ 936 ExtSteeringAngleReq2 32767 "Invalid" 32766 "Unknown" ;
VAL_ 570 SuspRearRight_L_Actl 511 "Faulty" ;
VAL_ 570 SuspFrntRight_L_Actl 511 "Faulty" ;
VAL_ 570 SuspRear_L_Prev 511 "Fault" ;
VAL_ 570 SuspRear_L_Actl 511 "Fault" ;
VAL_ 570 SuspFrnt_L_Prev 511 "Fault" ;
VAL_ 570 SuspFrnt_L_Actl 511 "Fault" ;
VAL_ 76 PsngrFmidDetct_D_Actl 3 "Unknown" 2 "Empty" 1 "Occupied" 0 "Fault" ;
VAL_ 76 FirstRowBuckleMid 3 "Unknown" 2 "Unbelted" 1 "Belted" 0 "Faulty" ;
VAL_ 76 ThirdRowBucklePsngr 3 "Unknown" 2 "Unbelted" 1 "Belted" 0 "Faulty" ;
VAL_ 76 ThirdRowBuckleMid 3 "Unknown" 2 "Unbelted" 1 "Belted" 0 "Faulty" ;
VAL_ 76 ThirdRowBuckleDriver 3 "Unknown" 2 "Unbelted" 1 "Belted" 0 "Faulty" ;
VAL_ 76 SecondRowBucklePsngr 3 "Unknown" 2 "Unbelted" 1 "Belted" 0 "Faulty" ;
VAL_ 76 SecondRowBuckleMid 3 "Unknown" 2 "Unbelted" 1 "Belted" 0 "Faulty" ;
VAL_ 76 SecondRowBuckleDriver 3 "Unknown" 2 "Unbelted" 1 "Belted" 0 "Faulty" ;
VAL_ 76 FirstRowBuckleDriver 3 "Unknown" 2 "Unbelted" 1 "Belted" 0 "Faulty" ;
VAL_ 76 RILReq 3 "Not_Used" 2 "Plant_Mode" 1 "On" 0 "Off" ;
VAL_ 76 FirstRowBucklePsngr 3 "Unknown" 2 "Unbelted" 1 "Belted" 0 "Faulty" ;
VAL_ 76 RstrnImpactEvntStatus 7 "Invalid" 6 "Not_Used_4" 5 "Threshold_2_Exceeded" 4 "Not_Used_3" 3 "Threshold_1_Exceeded" 2 "Not_Used_2" 1 "Not_Used_1" 0 "Normal" ;
VAL_ 76 PsngrFrntDetct_D_Actl 3 "Unknown" 2 "Empty" 0 "Faulty" 1 "Occupied" ;
VAL_ 76 EDRTriggerEvntSync 1 "Threshold_Exceeded" 0 "Normal" ;
VAL_ 76 PassRstrnInd_Req 3 "ABOnNotIllum_OffNotIllum" 2 "AirbagOnNot_Illum_OffIllum" 1 "AirbagOn_Illum_OffNotIllum" 0 "AirbagOn_Illum_Off_Illum" ;
VAL_ 120 TrlrAidSwtch_D_RqDrv 3 "Faulty" 2 "NotUsed" 1 "Pressed" 0 "Not_Pressed" ;
VAL_ 120 TrlrAidCtl_U_RqDrv 4095 "Faulty" 4094 "NoDataExists" ;
VAL_ 120 TrlrAidSwtch_D_RqDrv_UB 1 "Fresh_data" 0 "Unchanged_data" ;
VAL_ 120 TrlrAidCtl_U_RqDrv_UB 1 "Fresh_data" 0 "Unchanged_data" ;
VAL_ 120 BpedDrvMsgTxt_B_Dsply_UB 1 "Fresh_data" 0 "Unchanged_data" ;
VAL_ 120 BpedDrvMsgTxt_B_Dsply 1 "On" 0 "Off" ;
VAL_ 120 PassRstrnInd_Stat_UB 1 "Fresh_data" 0 "Unchanged_data" ;
VAL_ 120 PassRstrnInd_Stat 7 "Invalid" 6 "Unused_2" 5 "Unused_1" 4 "Both_Indicators_Faulted" 3 "AirbagOff_Indicator_fault" 2 "AirbagOn_Indicator_fault" 1 "Normal" 0 "Not_Supported" ;
VAL_ 120 HtrnWarnLamp_B_Dsply_UB 1 "Fresh_data" 0 "Unchanged_data" ;
VAL_ 120 HtrnWarnLamp_B_Dsply 1 "On" 0 "Off" ;
VAL_ 120 ECMMILRequest_UB 1 "Fresh_data" 0 "Unchanged_data" ;
VAL_ 120 ECMMILRequest 3 "Not_Used" 2 "Flash" 1 "On" 0 "Off" ;
VAL_ 120 TrnIpcDsplyMde_D_Stat 3 "Reserved_Blank_No_Display" 2 "Flash" 1 "On" 0 "Blank_No_Display" ;
VAL_ 120 TrnIpcDsplyMde_D_Actl 7 "Manual_3" 6 "Manual_2" 5 "Manual_1_Low" 4 "Sport" 3 "Drive" 2 "Neutral" 1 "Reverse" 0 "Park" ;
VAL_ 120 EngSrvcRqd_B_Rq_UB 1 "Fresh_data" 0 "Unchanged_data" ;
VAL_ 120 EngSrvcRqd_B_Rq 1 "Engine_Service_Required" 0 "No_engine_service_required" ;
VAL_ 120 HtrnSrvcRqd_B_Dsply 1 "On" 0 "Off" ;
VAL_ 120 HtrnSrvcRqd_B_Dsply_UB 1 "Fresh_data" 0 "Unchanged_data" ;
VAL_ 120 TrnIpcDsplyMde_D_Stat_UB 1 "Fresh_data" 0 "Unchanged_data" ;
VAL_ 120 TrnIpcDsplyMde_D_Actl_UB 1 "Fresh_data" 0 "Unchanged_data" ;
VAL_ 376 GasPrtc_D_RqDsply 7 "NotUsed_5" 6 "NotUsed_4" 5 "NotUsed_3" 4 "NotUsed_2" 3 "NotUsed_1" 2 "GpfOverLimit" 1 "GpfAtLimit" 0 "NormalOperation" ;
VAL_ 376 LnchCtlSys_D_Stat 7 "NotUsed3" 6 "NotUsed2" 5 "NotUsed1" 4 "On_LC_Unavailable_TC_On" 3 "On_LC_Unavailable" 2 "On_LC_Available" 1 "On_LC_Active" 0 "LC_OFF" ;
VAL_ 376 DynoMde_B_Cmd 1 "Two_Wheel_Dyno" 0 "Normal_Operation" ;
VAL_ 376 AslIconDsply_D_Rq 3 "Not_Used" 2 "On_Active" 1 "On_Passive" 0 "Off" ;
VAL_ 376 AslChime_B_Rq 1 "Yes" 0 "No" ;
VAL_ 376 PtcHtr_D_Cmd 3 "TurnOn" 2 "AutoMode" 1 "TurnOff" 0 "NoDecision_Initializing" ;
VAL_ 376 HvacHtrCore2_Te_Actl 1023 "Faulty" ;
VAL_ 376 EcssLamp_D_RqDsply 3 "Not_Used" 2 "Flash" 1 "On" 0 "Off" ;
VAL_ 376 AirAmbTe_D_Qf 3 "OK" 2 "Not_Within_Specifications" 1 "No_Data_Exists" 0 "Faulty" ;
VAL_ 376 AirAmb_P_Actl 63 "Fault" 62 "NoDataExists" ;
VAL_ 516 EngAoutNActl_D_QF 3 "OK" 2 "Not_Within_Specifications" 1 "No_Data_Exists" 0 "Faulty" ;
VAL_ 516 ApedPos_PcRate_ActlArb 255 "Fault" 254 "Unknown" ;
VAL_ 516 ApedPosPcActl_D_Qf 3 "OK" 2 "Not_Within_Specifications" 1 "No_Data_Exists" 0 "Faulty" ;
VAL_ 516 EngAout3_N_Actl 65535 "Invalid" ;
VAL_ 514 VehVTrlrAid_B_Avail 1 "Yes" 0 "No" ;
VAL_ 514 StrtrMtrCtlMsgTxt_D_Rq 7 "Start_In_Gear_Allowed" 6 "Pending_Start_Cancelled" 5 "Start_Pending_Please_Wait" 4 "Cranking_Limit_Exceeded" 3 "Press_Brk_and_Shift_to_P_N" 2 "Press_Clutch_and_Brake" 1 "Press_Clutch_To_Start" 0 "No_Display" ;
VAL_ 514 StrtrMtrDlyStrt_B_Stat 1 "Yes" 0 "No" ;
VAL_ 514 VehVActlEng_D_Qf 3 "OK" 2 "Not_Within_Specifications" 1 "No_Data_Exists" 0 "Faulty" ;
VAL_ 514 GearRvrse_D_Actl 7 "Fault" 6 "NotUsed_3" 5 "NotUsed_2" 4 "NotUsed_1" 3 "Active_confirmed" 2 "Active_not_confirmed" 1 "Inactive_confirmed" 0 "Inactive_not_confirmed" ;
VAL_ 1003 VehKeyActv_D_Stat 15 "NotUsed7" 14 "NotUsed6" 13 "NotUsed5" 12 "NotUsed4" 11 "NotUsed3" 10 "NotUsed2" 9 "NotUsed1" 8 "Key8Active" 7 "Key7Active" 6 "Key6Active" 5 "Key5Active" 4 "Key4Active" 3 "Key3Active" 2 "Key2Active" 1 "Key1Active" 0 "NoKeyActive" ;
VAL_ 1003 PersNoPos_D_Actl 7 "Unused_3" 6 "Unused_2" 5 "Unused_1" 4 "Vehicle" 3 "PERS_4" 2 "PERS_3" 1 "PERS_2" 0 "PERS_1" ;
VAL_ 1003 PersSetupRestr_D_Actl 3 "Non_Moveable_Person" 2 "Moveable_Person" 1 "Vehicle" 0 "Factory" ;
VAL_ 1003 PersSetupAccessCtrl 1 "Limited" 0 "Full" ;
VAL_ 1003 PersConflict_D_Actl 1 "Conflict" 0 "No_Conflict" ;
VAL_ 1003 AssocConfirm_D_Actl 0 "None" 7 "Associate" 6 "Keycode_Rejected" 5 "Keycode_Accepted" 4 "In_Progress" 3 "Erase" 2 "Duplicate" 1 "Disassociate" ;
VAL_ 1003 PersNo_D_Actl 7 "Unused_3" 6 "Unused_2" 5 "NotDetermined" 4 "Vehicle" 3 "PERS_4" 2 "PERS_3" 1 "PERS_2" 0 "PERS_1" ;
